VERSION ""

NS_ :

BS_:

BU_: TIMServer TIMClient3 TIMClient2 TIMClient1 DiagnosticNode

BO_ 2498166526 VT12: 34 Vector__XXX
 SG_ AffectedMaskObjectID m189 : 24|16@1+ (1,0) [0|65535] "" Vector__XXX
 SG_ AuxiliaryFunctionID m32 : 24|16@1+ (1,0) [0|65535] "" Vector__XXX
 SG_ AuxiliaryInputNumber m32 : 16|8@1+ (1,0) [0|255] "" Vector__XXX
 SG_ SourceAddressOfAuxiliaryInputDev m32 : 8|8@1+ (1,0) [0|255] "" Vector__XXX
 SG_ ErrorCodeSelectColourMap3 m186 : 26|1@1+ (1,0) [0|1] "" Vector__XXX
 SG_ ErrorCodeGetAttributeValue3 m65535 : 52|1@1+ (1,0) [0|1] "" Vector__XXX
 SG_ ErrorCodeGetAttributeValue2 m65535 : 49|1@1+ (1,0) [0|1] "" Vector__XXX
 SG_ ErrorCodeGetAttributeValue1 m65535 : 48|1@1+ (1,0) [0|1] "" Vector__XXX
 SG_ GetAttributeValueObjectID m65535 : 32|16@1+ (1,0) [0|65535] "" Vector__XXX
 SG_ AttributeValue m0 : 32|64@1+ (1,0) [0|4294967295] "" Vector__XXX
 SG_ ErrorCodeChangeSoftKeyMask3 m174 : 42|1@1+ (1,0) [0|1] "" Vector__XXX
 SG_ ErrorCodeChangeSoftKeyMask4 m174 : 43|1@1+ (1,0) [0|1] "" Vector__XXX
 SG_ ErrorCodeAudioVolume3 m164 : 12|1@1+ (1,0) [0|1] "" Vector__XXX
 SG_ ErrorCodeHideShowObj4 m160 : 36|1@1+ (1,0) [0|1] "" Vector__XXX
 SG_ ErrorCodeGetSupportedWideChars3 m193 : 52|1@1+ (1,0) [0|1] "" Vector__XXX
 SG_ Hardware8 m199 : 31|1@1+ (1,0) [0|1] "" Vector__XXX
 SG_ Hardware7 m199 : 30|1@1+ (1,0) [0|1] "" Vector__XXX
 SG_ ImageIdentificationNumber m198 : 32|16@1+ (1,0) [0|65535] "" Vector__XXX
 SG_ VTControlAudioSigTerminationTAN m10 : 20|4@1+ (1,0) [0|0] "" Vector__XXX
 SG_ ParentMaskObjectID m2 : 48|16@1+ (1,0) [0|0] "" Vector__XXX
 SG_ OperatingState4 m38 : 59|1@1+ (1,0) [0|1] "" Vector__XXX
 SG_ OperatingState3 m38 : 58|1@1+ (1,0) [0|1] "" Vector__XXX
 SG_ VTSelectInputObjectMessageTAN m3 : 60|4@1+ (1,0) [0|15] "" Vector__XXX
 SG_ VTOnUserLayoutHideShowMessageTAN m9 : 60|4@1+ (1,0) [0|15] "" Vector__XXX
 SG_ VTESCMessageTAN m4 : 60|4@1+ (1,0) [0|15] "" Vector__XXX
 SG_ VTChangeNumericValueMessageTAN m5 : 28|4@1+ (1,0) [0|15] "" Vector__XXX
 SG_ SoftKeyActivationMessageTAN m0 : 60|4@1+ (1,0) [0|15] "" Vector__XXX
 SG_ PointingEventMessageTAN m2 : 44|4@1+ (1,0) [0|15] "" Vector__XXX
 SG_ ButtonActivationMessageTAN m1 : 60|4@1+ (1,0) [0|15] "" Vector__XXX
 SG_ PathRequested m198 : 16|8@1+ (1,0) [0|255] "" Vector__XXX
 SG_ ItemRequested m198 : 8|8@1+ (1,0) [0|255] "" Vector__XXX
 SG_ ErrorCodeShowWorkingSet8 m144 : 15|1@1+ (1,0) [0|1] "" Vector__XXX
 SG_ ErrorCodeShowWorkingSet5 m144 : 12|1@1+ (1,0) [0|1] "" Vector__XXX
 SG_ ErrorCodeShowWorkingSet4 m144 : 11|1@1+ (1,0) [0|1] "" Vector__XXX
 SG_ ErrorCodeShowWorkingSet3 m144 : 10|1@1+ (1,0) [0|1] "" Vector__XXX
 SG_ ErrorCodeShowWorkingSet2 m144 : 9|1@1+ (1,0) [0|1] "" Vector__XXX
 SG_ ErrorCodeShowWorkingSet1 m144 : 8|1@1+ (1,0) [0|1] "" Vector__XXX
 SG_ ErrorCodeScreenCapture6 m198 : 29|1@1+ (1,0) [0|1] "" Vector__XXX
 SG_ ErrorCodeScreenCapture5 m198 : 28|1@1+ (1,0) [0|1] "" Vector__XXX
 SG_ ErrorCodeScreenCapture4 m198 : 27|1@1+ (1,0) [0|1] "" Vector__XXX
 SG_ ErrorCodeScreenCapture3 m198 : 26|1@1+ (1,0) [0|1] "" Vector__XXX
 SG_ ErrorCodeScreenCapture2 m198 : 25|1@1+ (1,0) [0|1] "" Vector__XXX
 SG_ ErrorCodeScreenCapture1 m198 : 24|1@1+ (1,0) [0|1] "" Vector__XXX
 SG_ UnsupportedVtFunction m253 : 8|8@1+ (1,0) [0|255] "" Vector__XXX
 SG_ AssignedAttribute2OfSet1 m39 : 105|1@1+ (1,0) [0|1] "" Vector__XXX
 SG_ AssignedAttribute1OfSet1 m39 : 104|1@1+ (1,0) [0|1] "" Vector__XXX
 SG_ FunctionAttributeOfSet1 m39 : 96|8@1+ (1,0) [0|255] "" Vector__XXX
 SG_ AuxiliaryFunctionObjectID m36 : 96|16@1+ (1,0) [0|65535] "" Vector__XXX
 SG_ NumberOfInstancesOfSet1 m39 : 88|8@1+ (1,0) [0|255] "" Vector__XXX
 SG_ NumberOfDifferentSetsOfUnit1 m39 : 80|8@1+ (1,0) [0|255] "" Vector__XXX
 SG_ AuxiliaryInputObjectID m36 : 80|16@1+ (1,0) [0|65535] "" Vector__XXX
 SG_ StoreAsPreferredAssignment m36 : 79|1@1+ (1,0) [0|1] "" Vector__XXX
 SG_ ErrorCodeChangeAttribute5 m175 : 36|1@1+ (1,0) [0|1] "" Vector__XXX
 SG_ AuxiliaryFunctionType m36 : 72|4@1+ (1,0) [0|15] "" Vector__XXX
 SG_ SelfConfigurableAddress m36 : 71|1@1+ (1,0) [0|1] "" Vector__XXX
 SG_ DeviceClassInstance m36 : 64|4@1+ (1,0) [0|15] "" Vector__XXX
 SG_ IndustryGroup m36 : 68|3@1+ (1,0) [0|7] "" Vector__XXX
 SG_ FontType_ProportionalFont m195 : 63|1@1+ (1,0) [0|1] "" Vector__XXX
 SG_ FontType_FlashHidden m195 : 62|1@1+ (1,0) [0|1] "" Vector__XXX
 SG_ FontType_FlashInverted m195 : 61|1@1+ (1,0) [0|1] "" Vector__XXX
 SG_ FontType_InvertedText m195 : 60|1@1+ (1,0) [0|1] "" Vector__XXX
 SG_ ErrorCodeChangePolygonScale5 m183 : 60|1@1+ (1,0) [0|1] "" Vector__XXX
 SG_ FontType_ItalicsText m195 : 59|1@1+ (1,0) [0|1] "" Vector__XXX
 SG_ FontType_UnderlinedText m195 : 58|1@1+ (1,0) [0|1] "" Vector__XXX
 SG_ FontType_CrossedOutText m195 : 57|1@1+ (1,0) [0|1] "" Vector__XXX
 SG_ DeviceClass m36 : 57|7@1+ (1,0) [0|127] "" Vector__XXX
 SG_ OperatingState2 m38 : 57|1@1+ (1,0) [0|1] "" Vector__XXX
 SG_ VTFunctionCode m254 : 56|8@1+ (1,0) [0|255] "" Vector__XXX
 SG_ FontType_BoldText m195 : 56|1@1+ (1,0) [0|1] "" Vector__XXX
 SG_ NumberOfPhysicalSoftKeys m194 : 56|8@1+ (1,0) [0|255] "" Vector__XXX
 SG_ NumberOfRanges m193 : 56|8@1+ (1,0) [0|255] "" Vector__XXX
 SG_ ErrorCodeChangePolygonScale1 m183 : 56|1@1+ (1,0) [0|1] "" Vector__XXX
 SG_ OperatingState1 m38 : 56|1@1+ (1,0) [0|1] "" Vector__XXX
 SG_ VTBusyCode8 m254 : 55|1@1+ (1,0) [0|1] "" Vector__XXX
 SG_ FontSize_128x192 m195 : 54|1@1+ (1,0) [0|1] "" Vector__XXX
 SG_ VTBusyCode7 m254 : 54|1@1+ (1,0) [0|1] "" Vector__XXX
 SG_ FontSize_128x128 m195 : 53|1@1+ (1,0) [0|1] "" Vector__XXX
 SG_ VTBusyCode5 m254 : 52|1@1+ (1,0) [0|1] "" Vector__XXX
 SG_ FontSize_96x128 m195 : 52|1@1+ (1,0) [0|1] "" Vector__XXX
 SG_ ErrorCodeGetSupportedWideChars2 m193 : 49|1@1+ (1,0) [0|1] "" Vector__XXX
 SG_ ErrorCodeChangeListItem5 m177 : 52|1@1+ (1,0) [0|1] "" Vector__XXX
 SG_ ErrorCodeChangeListItem4 m177 : 51|1@1+ (1,0) [0|1] "" Vector__XXX
 SG_ VTBusyCode4 m254 : 51|1@1+ (1,0) [0|1] "" Vector__XXX
 SG_ FontSize_64x96 m195 : 51|1@1+ (1,0) [0|1] "" Vector__XXX
 SG_ ErrorCodeObjectPool4 m18 : 51|1@1+ (1,0) [0|1] "" Vector__XXX
 SG_ VTBusyCode3 m254 : 50|1@1+ (1,0) [0|1] "" Vector__XXX
 SG_ FontSize_64x64 m195 : 50|1@1+ (1,0) [0|1] "" Vector__XXX
 SG_ ErrorCodeChangeListItem3 m177 : 50|1@1+ (1,0) [0|1] "" Vector__XXX
 SG_ ErrorCodeObjectPool3 m18 : 50|1@1+ (1,0) [0|1] "" Vector__XXX
 SG_ VTBusyCode2 m254 : 49|1@1+ (1,0) [0|1] "" Vector__XXX
 SG_ FontSize_48x64 m195 : 49|1@1+ (1,0) [0|1] "" Vector__XXX
 SG_ ErrorCodeChangeListItem2 m177 : 49|1@1+ (1,0) [0|1] "" Vector__XXX
 SG_ ErrorCodeObjectPool2 m18 : 49|1@1+ (1,0) [0|1] "" Vector__XXX
 SG_ VTBusyCode1 m254 : 48|1@1+ (1,0) [0|1] "" Vector__XXX
 SG_ NrOfYPixelsInDataAreaMask m199 : 48|16@1+ (1,0) [0|65535] "" Vector__XXX
 SG_ FontSize_32x48 m195 : 48|1@1+ (1,0) [0|1] "" Vector__XXX
 SG_ NumberOfPossibleVirtualSoftKeys m194 : 48|8@1+ (1,0) [0|255] "" Vector__XXX
 SG_ ErrorCodeGetSupportedWideChars1 m193 : 48|1@1+ (1,0) [0|1] "" Vector__XXX
 SG_ ErrorCodeChangeListItem1 m177 : 48|1@1+ (1,0) [0|1] "" Vector__XXX
 SG_ Function m36 : 48|8@1+ (1,0) [0|255] "" Vector__XXX
 SG_ ErrorCodeObjectPool1 m18 : 48|1@1+ (1,0) [0|1] "" Vector__XXX
 SG_ VTChangeActiveMaskParentID m6 : 48|16@1+ (1,0) [0|65535] "" Vector__XXX
 SG_ ButtonKeyCode m1 : 48|8@1+ (1,0) [0|255] "" Vector__XXX
 SG_ SoftKeyCode m0 : 48|8@1+ (1,0) [0|255] "" Vector__XXX
 SG_ BooleanValue m33 : 48|8@1+ (1,0) [0|2] "" Vector__XXX
 SG_ Status_2 m9 : 48|8@1+ (1,0) [0|1] "" Vector__XXX
 SG_ ErrorCodeVTChangeSoftKeyMask4 m7 : 45|1@1+ (1,0) [0|1] "" Vector__XXX
 SG_ FontSize_32x32 m195 : 46|1@1+ (1,0) [0|1] "" Vector__XXX
 SG_ FontSize_24x32 m195 : 45|1@1+ (1,0) [0|1] "" Vector__XXX
 SG_ FontSize_16x24 m195 : 44|1@1+ (1,0) [0|1] "" Vector__XXX
 SG_ ErrorCodeChangePosInvalidError m180 : 44|1@1+ (1,0) [0|1] "" Vector__XXX
 SG_ ErrorCodeChangeSoftKeyMask5 m174 : 44|1@1+ (1,0) [0|1] "" Vector__XXX
 SG_ ErrorCodeChangeChildLocation5 m165 : 44|1@1+ (1,0) [0|1] "" Vector__XXX
 SG_ ErrorCodeVTChangeSoftKeyMask3 m7 : 44|1@1+ (1,0) [0|1] "" Vector__XXX
 SG_ ErrorCodeChangeStrValueInUse m179 : 44|1@1+ (1,0) [0|1] "" Vector__XXX
 SG_ ErrorCodeVtObjPoolError4 m240 : 43|1@1+ (1,0) [0|1] "" Vector__XXX
 SG_ FontSize_16x16 m195 : 43|1@1+ (1,0) [0|1] "" Vector__XXX
 SG_ ErrorCodeChangeStrError m179 : 43|1@1+ (1,0) [0|1] "" Vector__XXX
 SG_ FunctionInstance m36 : 43|5@1+ (1,0) [0|31] "" Vector__XXX
 SG_ ErrorCodeVTChangeSoftKeyMask2 m7 : 43|1@1+ (1,0) [0|1] "" Vector__XXX
 SG_ ErrorCodeVtObjPoolError3 m240 : 42|1@1+ (1,0) [0|1] "" Vector__XXX
 SG_ FontSize_12x16 m195 : 42|1@1+ (1,0) [0|1] "" Vector__XXX
 SG_ ErrorCodeChangeStrTooLong m179 : 42|1@1+ (1,0) [0|1] "" Vector__XXX
 SG_ ErrorCodeVTChangeSoftKeyMask1 m7 : 42|1@1+ (1,0) [0|1] "" Vector__XXX
 SG_ ErrorCodeVtObjPoolError2 m240 : 41|1@1+ (1,0) [0|1] "" Vector__XXX
 SG_ FontSize_8x12 m195 : 41|1@1+ (1,0) [0|1] "" Vector__XXX
 SG_ ErrorCodeChangePosInvalidObject m180 : 41|1@1+ (1,0) [0|1] "" Vector__XXX
 SG_ ErrorCodeChangeStrObjectID m179 : 41|1@1+ (1,0) [0|1] "" Vector__XXX
 SG_ ErrorCodeChangeSoftKeyMask2 m174 : 41|1@1+ (1,0) [0|1] "" Vector__XXX
 SG_ ErrorCodeChangeChildLocation2 m165 : 41|1@1+ (1,0) [0|1] "" Vector__XXX
 SG_ ErrorCodeVtObjPoolError1 m240 : 40|1@1+ (1,0) [0|1] "" Vector__XXX
 SG_ AcknowledgmentDeleteVersion m210 : 40|4@1+ (1,0) [0|8] "" Vector__XXX
 SG_ AcknowledgmentLoadVersion m209 : 40|4@1+ (1,0) [0|8] "" Vector__XXX
 SG_ AcknowledgmentStoreVersion m208 : 40|4@1+ (1,0) [0|8] "" Vector__XXX
 SG_ FontSize_8x8 m195 : 40|1@1+ (1,0) [0|1] "" Vector__XXX
 SG_ YDotsForSoftKeyDescriptor m194 : 40|8@1+ (1,0) [0|255] "" Vector__XXX
 SG_ NewHeigthAttribute m183 : 40|16@1+ (1,0) [0|0] "" Vector__XXX
 SG_ ErrorCodeChangePosInvalidParent m180 : 40|1@1+ (1,0) [0|1] "" Vector__XXX
 SG_ ErrorCodeChangeSoftKeyMask1 m174 : 40|1@1+ (1,0) [0|1] "" Vector__XXX
 SG_ ErrorCodeChangeChildLocation1 m165 : 40|1@1+ (1,0) [0|1] "" Vector__XXX
 SG_ Value2 m38 : 40|16@1+ (1,0) [0|65535] "" Vector__XXX
 SG_ ECUInstance m36 : 40|3@1+ (1,0) [0|7] "" Vector__XXX
 SG_ TouchState m2 : 40|4@1+ (1,0) [0|255] "" Vector__XXX
 SG_ ErrorCodeSelectObject6 m162 : 37|1@1+ (1,0) [0|1] "" Vector__XXX
 SG_ ErrorCodeGraphicsContextCmd5 m184 : 36|1@1+ (1,0) [0|1] "" Vector__XXX
 SG_ ErrorCodeChangePriority3 m176 : 36|1@1+ (1,0) [0|1] "" Vector__XXX
 SG_ ErrorCodeChangeAttribute4 m175 : 35|1@1+ (1,0) [0|1] "" Vector__XXX
 SG_ ErrorCodeChangeColour3 m167 : 36|1@1+ (1,0) [0|1] "" Vector__XXX
 SG_ ErrorCodeSelectObject5 m162 : 36|1@1+ (1,0) [0|1] "" Vector__XXX
 SG_ ErrorCodeEnableDisableObj4 m161 : 36|1@1+ (1,0) [0|1] "" Vector__XXX
 SG_ ErrorCodeGraphicsContextCmd4 m184 : 35|1@1+ (1,0) [0|1] "" Vector__XXX
 SG_ ErrorCodeSelectObject4 m162 : 35|1@1+ (1,0) [0|1] "" Vector__XXX
 SG_ ErrorCodeEnableDisableObj3 m161 : 35|1@1+ (1,0) [0|1] "" Vector__XXX
 SG_ ErrorCodeHideShowObj3 m160 : 34|1@1+ (1,0) [0|1] "" Vector__XXX
 SG_ ErrorCodeGraphicsContextCmd3 m184 : 34|1@1+ (1,0) [0|1] "" Vector__XXX
 SG_ ErrorCodeChangeAttribute3 m175 : 34|1@1+ (1,0) [0|1] "" Vector__XXX
 SG_ ErrorCodeSelectObject3 m162 : 34|1@1+ (1,0) [0|1] "" Vector__XXX
 SG_ ErrorCodeEnableDisableObj2 m161 : 34|1@1+ (1,0) [0|1] "" Vector__XXX
 SG_ ErrorCodeGraphicsContextCmd2 m184 : 33|1@1+ (1,0) [0|1] "" Vector__XXX
 SG_ ErrorCodeChangePriority2 m176 : 33|1@1+ (1,0) [0|1] "" Vector__XXX
 SG_ ErrorCodeChangeAttribute2 m175 : 33|1@1+ (1,0) [0|1] "" Vector__XXX
 SG_ ErrorCodeChangeColour2 m167 : 33|1@1+ (1,0) [0|1] "" Vector__XXX
 SG_ ErrorCodeSelectObject2 m162 : 33|1@1+ (1,0) [0|1] "" Vector__XXX
 SG_ ErrorCodeEnableDisableObj1 m161 : 33|1@1+ (1,0) [0|1] "" Vector__XXX
 SG_ ErrorCodeHideShowObj2 m160 : 33|1@1+ (1,0) [0|1] "" Vector__XXX
 SG_ VisibleSoftKeyMaskObjectID m254 : 32|16@1+ (1,0) [0|65535] "" Vector__XXX
 SG_ NrOfXPixelsInDataAreaMask m199 : 32|16@1+ (1,0) [0|65535] "" Vector__XXX
 SG_ XDotsForSoftKeyDescriptor m194 : 32|8@1+ (1,0) [0|255] "" Vector__XXX
 SG_ LastWideChar m193 : 32|16@1+ (1,0) [0|65535] "" Vector__XXX
 SG_ ErrorCodeGraphicsContextCmd1 m184 : 32|1@1+ (1,0) [0|1] "" Vector__XXX
 SG_ NewObjectID m177 : 32|16@1+ (1,0) [0|65535] "" Vector__XXX
 SG_ ErrorCodeChangePriority1 m176 : 32|1@1+ (1,0) [0|1] "" Vector__XXX
 SG_ ErrorCodeChangeAttribute1 m175 : 32|1@1+ (1,0) [0|1] "" Vector__XXX
 SG_ ValueOfTheObject m168 : 32|32@1+ (1,0) [0|2704] "" Vector__XXX
 SG_ ErrorCodeChangeColour1 m167 : 32|1@1+ (1,0) [0|1] "" Vector__XXX
 SG_ ErrorCodeSelectObject1 m162 : 32|1@1+ (1,0) [0|1] "" Vector__XXX
 SG_ ErrorCodeHideShowObj1 m160 : 32|1@1+ (1,0) [0|1] "" Vector__XXX
 SG_ ObjectIdOfFaultyObject m18 : 32|16@1+ (1,0) [0|65535] "" Vector__XXX
 SG_ VTChangeActiveMaskErrorID m6 : 32|16@1+ (1,0) [0|65535] "" Vector__XXX
 SG_ VTChangeNumericValueValue m5 : 32|32@1+ (1,0) [0|4294967295] "" Vector__XXX
 SG_ VTSelectInputObjectIsEdited m3 : 32|1@1+ (1,0) [0|1] "" Vector__XXX
 SG_ ButtonObjectParentID m1 : 32|16@1+ (1,0) [0|65535] "" Vector__XXX
 SG_ KeyObjectParentID m0 : 32|16@1+ (1,0) [0|65535] "" Vector__XXX
 SG_ NumTransitionsDisabledToEnabled m33 : 32|16@1+ (1,0) [0|65535] "" Vector__XXX
 SG_ ObjectID_2 m9 : 32|16@1+ (1,0) [0|65535] "" Vector__XXX
 SG_ Hardware6 m199 : 29|1@1+ (1,0) [0|1] "" Vector__XXX
 SG_ ErrorCodeChangeFont6 m170 : 29|1@1+ (1,0) [0|1] "" Vector__XXX
 SG_ ManufacturerCode m36 : 29|11@1+ (1,0) [0|2047] "" Vector__XXX
 SG_ ErrorCodePoolDeleted m6 : 29|1@1+ (1,0) [0|1] "" Vector__XXX
 SG_ Hardware5 m199 : 28|1@1+ (1,0) [0|1] "" Vector__XXX
 SG_ ErrorCodeChangeActiveMask3 m173 : 28|1@1+ (1,0) [0|1] "" Vector__XXX
 SG_ ErrorCodeChangeFillAttributes5 m172 : 28|1@1+ (1,0) [0|1] "" Vector__XXX
 SG_ ErrorCodeChangeLineAttribute4 m171 : 28|1@1+ (1,0) [0|1] "" Vector__XXX
 SG_ ErrorCodeChangeFont5 m170 : 28|1@1+ (1,0) [0|1] "" Vector__XXX
 SG_ ErrorCodeChangeEditPoint3 m169 : 28|1@1+ (1,0) [0|1] "" Vector__XXX
 SG_ ErrorCodeObjToSize2 m166 : 28|1@1+ (1,0) [0|1] "" Vector__XXX
 SG_ ErrorCodeEscapeObj2 m146 : 28|1@1+ (1,0) [0|1] "" Vector__XXX
 SG_ ErrorCodeAnyOtherError m6 : 28|1@1+ (1,0) [0|1] "" Vector__XXX
 SG_ ErrorCodeVTEsc5 m4 : 28|1@1+ (1,0) [0|1] "" Vector__XXX
 SG_ ErrorCodeChangeNumValue4 m168 : 28|1@1+ (1,0) [0|1] "" Vector__XXX
 SG_ Hardware4 m199 : 27|1@1+ (1,0) [0|1] "" Vector__XXX
 SG_ ErrorCodeChangeFillAttributes4 m172 : 27|1@1+ (1,0) [0|1] "" Vector__XXX
 SG_ ErrorCodeChangeFont4 m170 : 27|1@1+ (1,0) [0|1] "" Vector__XXX
 SG_ ErrorCodeMaskOrChildObjectError m6 : 27|1@1+ (1,0) [0|1] "" Vector__XXX
 SG_ ErrorCodeChangeNumValue3 m168 : 26|1@1+ (1,0) [0|1] "" Vector__XXX
 SG_ Hardware3 m199 : 26|1@1+ (1,0) [0|1] "" Vector__XXX
 SG_ ErrorCodeChangePoygonPoint3 m182 : 26|1@1+ (1,0) [0|1] "" Vector__XXX
 SG_ ErrorCodeChangeFillAttributes3 m172 : 26|1@1+ (1,0) [0|1] "" Vector__XXX
 SG_ ErrorCodeChangeLineAttribute3 m171 : 26|1@1+ (1,0) [0|1] "" Vector__XXX
 SG_ ErrorCodeChangeFont3 m170 : 26|1@1+ (1,0) [0|1] "" Vector__XXX
 SG_ ErrorCodeMissingObjects m6 : 26|1@1+ (1,0) [0|1] "" Vector__XXX
 SG_ ErrorCodeExecuteExtendedMacro3 m188 : 26|1@1+ (1,0) [0|1] "" Vector__XXX
 SG_ Hardware2 m199 : 25|1@1+ (1,0) [0|1] "" Vector__XXX
 SG_ ErrorCodeSelectColourMap2 m186 : 25|1@1+ (1,0) [0|1] "" Vector__XXX
 SG_ ErrorCodeChangePoygonPoint2 m182 : 25|1@1+ (1,0) [0|1] "" Vector__XXX
 SG_ ErrorCodeChangeActiveMask2 m173 : 25|1@1+ (1,0) [0|1] "" Vector__XXX
 SG_ ErrorCodeChangeFillAttributes2 m172 : 25|1@1+ (1,0) [0|1] "" Vector__XXX
 SG_ ErrorCodeChangeLineAttribute2 m171 : 25|1@1+ (1,0) [0|1] "" Vector__XXX
 SG_ ErrorCodeChangeFont2 m170 : 25|1@1+ (1,0) [0|1] "" Vector__XXX
 SG_ ErrorCodeChangeEditPoint2 m169 : 25|1@1+ (1,0) [0|1] "" Vector__XXX
 SG_ ErrorCodeChangeNumValue2 m168 : 25|1@1+ (1,0) [0|1] "" Vector__XXX
 SG_ ErrorCodeExecuteExtendedMacro2 m188 : 25|1@1+ (1,0) [0|1] "" Vector__XXX
 SG_ ObjectIDOfFaultyObject m240 : 24|16@1+ (1,0) [0|65535] "" Vector__XXX
 SG_ Hardware1 m199 : 24|1@1+ (1,0) [0|1] "" Vector__XXX
 SG_ ErrorCodeSelectColourMap1 m186 : 24|1@1+ (1,0) [0|1] "" Vector__XXX
 SG_ AttributeID m185M : 24|8@1+ (1,0) [0|0] "" Vector__XXX
 SG_ SubCommandID m184 : 24|8@1+ (1,0) [0|0] "" Vector__XXX
 SG_ NewWidthAttribute m183 : 24|16@1+ (1,0) [0|65535] "" Vector__XXX
 SG_ ErrorCodeChangePoygonPoint1 m182 : 24|1@1+ (1,0) [0|1] "" Vector__XXX
 SG_ ChangeChildPosObjID m180 : 24|16@1+ (1,0) [0|65535] "" Vector__XXX
 SG_ ChangeStringValueObjID m179 : 24|16@1+ (1,0) [0|65535] "" Vector__XXX
 SG_ ListIndex m177 : 24|8@1+ (1,0) [0|255] "" Vector__XXX
 SG_ NewPriority m176 : 24|8@1+ (1,0) [0|255] "" Vector__XXX
 SG_ AttributeToChangeID m175 : 24|8@1+ (1,0) [0|65535] "" Vector__XXX
 SG_ SoftKeyMaskObjectID m174 : 24|16@1+ (1,0) [0|65535] "" Vector__XXX
 SG_ ErrorCodeChangeActiveMask1 m173 : 24|1@1+ (1,0) [0|1] "" Vector__XXX
 SG_ ErrorCodeChangeFillAttributes1 m172 : 24|1@1+ (1,0) [0|1] "" Vector__XXX
 SG_ ErrorCodeChangeLineAttribute1 m171 : 24|1@1+ (1,0) [0|1] "" Vector__XXX
 SG_ ErrorCodeChangeFont1 m170 : 24|1@1+ (1,0) [0|1] "" Vector__XXX
 SG_ ErrorCodeChangeEditPoint1 m169 : 24|1@1+ (1,0) [0|1] "" Vector__XXX
 SG_ ErrorCodeChangeNumValue1 m168 : 24|1@1+ (1,0) [0|1] "" Vector__XXX
 SG_ NewBackgroundColour m167 : 24|8@1+ (1,0) [0|255] "" Vector__XXX
 SG_ ErrorCodeObjToSize1 m166 : 24|1@1+ (1,0) [0|1] "" Vector__XXX
 SG_ ChangeChildLocObjID m165 : 24|16@1+ (1,0) [0|65535] "" Vector__XXX
 SG_ ObjectSelectStatus m162 : 24|8@1+ (1,0) [0|2] "" Vector__XXX
 SG_ ObjectEnableStatus m161 : 24|8@1+ (1,0) [0|1] "" Vector__XXX
 SG_ ObjectShowStatus m160 : 24|8@1+ (1,0) [0|1] "" Vector__XXX
 SG_ ErrorCodeEscapeObj1 m146 : 24|1@1+ (1,0) [0|1] "" Vector__XXX
 SG_ AuxInputEnable m37 : 24|8@1+ (1,0) [0|1] "" Vector__XXX
 SG_ Value1 m38 : 24|16@1+ (1,0) [0|65535] "" Vector__XXX
 SG_ EnteredStringValue m8 : 24|8@1+ (1,0) [0|255] "" Vector__XXX
 SG_ VTChangeSoftKeyMaskObjectID m7 : 24|16@1+ (1,0) [0|65535] "" Vector__XXX
 SG_ ErrorCodeVTEsc1 m4 : 24|1@1+ (1,0) [0|1] "" Vector__XXX
 SG_ VTSelectInputObjectStatus m3 : 24|8@1+ (1,0) [0|1] "" Vector__XXX
 SG_ YPosition m2 : 24|16@1+ (1,0) [0|65535] "" Vector__XXX
 SG_ Status_1 m9 : 24|8@1+ (1,0) [0|1] "" Vector__XXX
 SG_ ErrorCodeExecuteExtendedMacro1 m188 : 24|1@1+ (1,0) [0|1] "" Vector__XXX
 SG_ ErrorCodeLockUnlockMask8 m189 : 23|1@1+ (1,0) [0|1] "" Vector__XXX
 SG_ ErrorCodeLockUnlockMask7 m189 : 22|1@1+ (1,0) [0|1] "" Vector__XXX
 SG_ ErrorCodeLockUnlockMask6 m189 : 21|1@1+ (1,0) [0|1] "" Vector__XXX
 SG_ ErrorCodeLockUnlockMask5 m189 : 20|1@1+ (1,0) [0|1] "" Vector__XXX
 SG_ ErrorCodeLockUnlockMask4 m189 : 19|1@1+ (1,0) [0|1] "" Vector__XXX
 SG_ ErrorCodeExecuteMacro3 m190 : 18|1@1+ (1,0) [0|1] "" Vector__XXX
 SG_ ErrorCodeLockUnlockMask3 m189 : 18|1@1+ (1,0) [0|1] "" Vector__XXX
 SG_ ErrorCodeExecuteMacro2 m190 : 17|1@1+ (1,0) [0|1] "" Vector__XXX
 SG_ ErrorCodeLockUnlockMask2 m189 : 17|1@1+ (1,0) [0|1] "" Vector__XXX
 SG_ NameOfAuxiliaryUnit1 m39 : 16|64@1+ (1,0) [0|0] "" Vector__XXX
 SG_ ExtendedVersionLables m211 : 16|256@1+ (1,0) [0|16777215] "" Vector__XXX
 SG_ VisibleDataOrAlarmMaskObjectID m254 : 16|16@1+ (1,0) [0|65535] "" Vector__XXX
 SG_ VersionLables m224 : 16|56@1+ (1,0) [0|0] "" Vector__XXX
 SG_ SupportedGraphicMode m199 : 16|8@1+ (1,0) [0|2] "" Vector__XXX
 SG_ FirstWideChar m193 : 16|16@1+ (1,0) [0|65535] "" Vector__XXX
 SG_ MemoryStatus m192 : 16|8@1+ (1,0) [0|1] "" Vector__XXX
 SG_ ErrorCodeExecuteMacro1 m190 : 16|1@1+ (1,0) [0|1] "" Vector__XXX
 SG_ ErrorCodeLockUnlockMask1 m189 : 16|1@1+ (1,0) [0|1] "" Vector__XXX
 SG_ ParentObjectIDOfFaultyObject m18 : 16|16@1+ (1,0) [0|65535] "" Vector__XXX
 SG_ ButtonObjectID m1 : 16|16@1+ (1,0) [0|65535] "" Vector__XXX
 SG_ KeyObjectID m0 : 16|16@1+ (1,0) [0|65535] "" Vector__XXX
 SG_ AuxFunctObjOfFaultyAssignment m34 : 16|16@1- (1,0) [0|65535] "" Vector__XXX
 SG_ AnalogValue m33 : 16|16@1+ (1,0) [0|65535] "" Vector__XXX
 SG_ BgrColourUserLayoutSoftkeyMask m196 : 16|8@1+ (1,0) [0|255] "" Vector__XXX
 SG_ ErrorCodeSetObjectLabel6 m181 : 13|1@1+ (1,0) [0|1] "" Vector__XXX
 SG_ ErrorCodeSetObjectLabel5 m181 : 12|1@1+ (1,0) [0|1] "" Vector__XXX
 SG_ ErrorCodeDeleteObjectPool2 m178 : 12|1@1+ (1,0) [0|1] "" Vector__XXX
 SG_ ErrorCodeAudioVolume2 m164 : 9|1@1+ (1,0) [0|1] "" Vector__XXX
 SG_ ErrorCodeControlAudioDevice2 m163 : 12|1@1+ (1,0) [0|1] "" Vector__XXX
 SG_ ErrorCodeEndOfObjectPool3 m18 : 12|1@1+ (1,0) [0|1] "" Vector__XXX
 SG_ AuxPreferredAssignmentRespError5 m34 : 12|1@1+ (1,0) [0|1] "" Vector__XXX
 SG_ ErrorCodeSetObjectLabel4 m181 : 11|1@1+ (1,0) [0|1] "" Vector__XXX
 SG_ AuxPreferredAssignmentRespError4 m34 : 11|1@1+ (1,0) [0|1] "" Vector__XXX
 SG_ ErrorCodeSetObjectLabel3 m181 : 10|1@1+ (1,0) [0|1] "" Vector__XXX
 SG_ AuxPreferredAssignmentRespError3 m34 : 10|1@1+ (1,0) [0|1] "" Vector__XXX
 SG_ ErrorCodeSetObjectLabel2 m181 : 9|1@1+ (1,0) [0|1] "" Vector__XXX
 SG_ AuxPreferredAssignmentRespError2 m34 : 9|1@1+ (1,0) [0|1] "" Vector__XXX
 SG_ ErrorCodeEndOfObjectPool2 m18 : 9|1@1+ (1,0) [0|1] "" Vector__XXX
 SG_ SourceAdressOfActiveWSM m254 : 8|8@1+ (1,0) [0|255] "" Vector__XXX
 SG_ ParentIDOfFaultyObject m240 : 8|16@1+ (1,0) [0|65535] "" Vector__XXX
 SG_ NrOfVersionStrings m224 : 8|8@1+ (1,0) [0|255] "" Vector__XXX
 SG_ NavigationSoftKeys m194 : 8|8@1+ (1,0) [0|254] "" Vector__XXX
 SG_ CodePlane m193 : 8|8@1+ (1,0) [0|16] "" Vector__XXX
 SG_ VersionNumberISO11783Part6 m192 : 8|8@1+ (1,0) [0|255] "" Vector__XXX
 SG_ MacroObjectID m190 : 8|8@1+ (1,0) [0|255] "" Vector__XXX
 SG_ LockUnlockCommand m189 : 8|8@1+ (1,0) [0|1] "" Vector__XXX
 SG_ ColourMapObjectID m186 : 8|16@1+ (1,0) [0|65535] "" Vector__XXX
 SG_ ObjectToGetAttributeID m185 : 8|16@1+ (1,0) [0|65535] "" Vector__XXX
 SG_ GraphicsContextObjectID m184 : 8|16@1+ (1,0) [0|65535] "" Vector__XXX
 SG_ PolygonObjectToScaleID m183 : 8|16@1+ (1,0) [0|65535] "" Vector__XXX
 SG_ PolygonObjectToChangeID m182 : 8|16@1+ (1,0) [0|65535] "" Vector__XXX
 SG_ ErrorCodeSetObjectLabel1 m181 : 8|1@1+ (1,0) [0|1] "" Vector__XXX
 SG_ ChangeChildPosParObjID m180 : 8|16@1+ (1,0) [0|65535] "" Vector__XXX
 SG_ ErrorCodeDeleteObjectPool1 m178 : 8|1@1+ (1,0) [0|1] "" Vector__XXX
 SG_ ListInputObjectID m177 : 8|16@1+ (1,0) [0|65535] "" Vector__XXX
 SG_ AlarmMaskObjectID m176 : 8|16@1+ (1,0) [0|65535] "" Vector__XXX
 SG_ ObjectToChangeAttributeID m175 : 8|16@1+ (1,0) [0|65535] "" Vector__XXX
 SG_ DataOrAlarmMaskObjectID m174 : 8|16@1+ (1,0) [0|65535] "" Vector__XXX
 SG_ ActiveMaskObjectID m173 : 8|16@1+ (1,0) [0|0] "" Vector__XXX
 SG_ ObjectToChangeFillAttributesID m172 : 8|16@1+ (1,0) [0|65535] "" Vector__XXX
 SG_ ObjectToChangeLineAttributeID m171 : 8|16@1+ (1,0) [0|65535] "" Vector__XXX
 SG_ ObjectToChangeFontID m170 : 8|16@1+ (1,0) [0|65535] "" Vector__XXX
 SG_ ObjectToChangeEndPointID m169 : 8|16@1+ (1,0) [0|65535] "" Vector__XXX
 SG_ ObjectToChangeNumValueID m168 : 8|16@1+ (1,0) [0|65535] "" Vector__XXX
 SG_ ObjectToChangeColourID m167 : 8|16@1+ (1,0) [0|65535] "" Vector__XXX
 SG_ ObjectToSizeID m166 : 8|16@1+ (1,0) [0|65535] "" Vector__XXX
 SG_ ChangeChildLocParObjID m165 : 8|16@1+ (1,0) [0|65535] "" Vector__XXX
 SG_ ErrorCodeAudioVolume1 m164 : 8|1@1+ (1,0) [0|1] "" Vector__XXX
 SG_ ErrorCodeControlAudioDevice1 m163 : 8|1@1+ (1,0) [0|1] "" Vector__XXX
 SG_ SelectInputObjectID m162 : 8|16@1+ (1,0) [0|65535] "" Vector__XXX
 SG_ ObjectToEnableDisableID m161 : 8|16@1+ (1,0) [0|65535] "" Vector__XXX
 SG_ ObjectToHideShowID m160 : 8|16@1+ (1,0) [0|65535] "" Vector__XXX
 SG_ ObjectEscapeID m146 : 8|16@1+ (1,0) [0|65535] "" Vector__XXX
 SG_ InputStatusObjectId m37 : 8|16@1+ (1,0) [0|255] "" Vector__XXX
 SG_ AuxPreferredAssignmentRespError1 m34 : 8|1@1+ (1,0) [0|1] "" Vector__XXX
 SG_ InputObjectId m38 : 8|16@1+ (1,0) [0|255] "" Vector__XXX
 SG_ IdentityNumber m36 : 8|21@1+ (1,0) [0|2097150] "" Vector__XXX
 SG_ ErrorCodeEndOfObjectPool1 m18 : 8|1@1+ (1,0) [0|1] "" Vector__XXX
 SG_ ObjectToChangeStringID m8 : 8|16@1+ (1,0) [0|65535] "" Vector__XXX
 SG_ VTChangeSoftKeyMaskParentID m7 : 8|16@1+ (1,0) [0|65535] "" Vector__XXX
 SG_ VTChangeActiveMaskObjectID m6 : 8|16@1+ (1,0) [0|65535] "" Vector__XXX
 SG_ VTChangeNumericValueObjectID m5 : 8|16@1+ (1,0) [0|65535] "" Vector__XXX
 SG_ VTEscObjectID m4 : 8|16@1+ (1,0) [0|65535] "" Vector__XXX
 SG_ VTSelectInputObjectID m3 : 8|16@1+ (1,0) [0|65535] "" Vector__XXX
 SG_ XPosition m2 : 8|16@1+ (1,0) [0|65535] "" Vector__XXX
 SG_ ButtonActivationCode m1 : 8|8@1+ (1,0) [0|2] "" Vector__XXX
 SG_ KeyActivationCode m0 : 8|8@1+ (1,0) [0|2] "" Vector__XXX
 SG_ TerminationCause m10 : 8|8@1+ (1,0) [0|255] "" Vector__XXX
 SG_ InputNumber m33 : 8|8@1+ (1,0) [0|250] "" Vector__XXX
 SG_ ObjectID_1 m9 : 8|16@1+ (1,0) [0|65535] "" Vector__XXX
 SG_ BgrColourUserLayoutDataMask m196 : 8|8@1+ (1,0) [0|255] "" Vector__XXX
 SG_ NumberOfSupportedObjects m197 : 8|8@1+ (1,0) [0|255] "" Vector__XXX
 SG_ BootTime m199 : 8|8@1+ (1,0) [0|255] "s" Vector__XXX
 SG_ NumberOfAuxiliaryUnits m39 : 8|8@1+ (1,0) [0|255] "" Vector__XXX
 SG_ MacroObjectID_2 m188 : 8|16@1+ (1,0) [0|65535] "" Vector__XXX
 SG_ VTFunctionVTtoECU M : 0|8@1+ (1,0) [0|255] "" Vector__XXX

BO_ 2565799678 AC: 8 Vector__XXX
 SG_ ReservedBit : 48|1@1+ (1,0) [0|0] "" Vector__XXX
 SG_ ArbitraryAddressCapable : 63|1@1+ (1,0) [0|1] "" Vector__XXX
 SG_ IndustryGroup M : 60|3@1+ (1,0) [0|7] "" Vector__XXX
 SG_ VehicleSystemInstance : 56|4@1+ (1,0) [0|15] "" Vector__XXX
 SG_ VehicleSystem m0 : 49|7@1+ (1,0) [0|127] "" Vector__XXX
 SG_ VehicleSystem5 m5 : 49|7@1+ (1,0) [0|127] "" Vector__XXX
 SG_ VehicleSystem4 m4 : 49|7@1+ (1,0) [0|127] "" Vector__XXX
 SG_ VehicleSystem3 m3 : 49|7@1+ (1,0) [0|127] "" Vector__XXX
 SG_ VehicleSystem2 m2 : 49|7@1+ (1,0) [0|127] "" Vector__XXX
 SG_ VehicleSystem1 m1 : 49|7@1+ (1,0) [0|127] "" Vector__XXX
 SG_ Function : 40|8@1+ (1,0) [0|255] "" Vector__XXX
 SG_ FunctionInstance : 35|5@1+ (1,0) [0|31] "" Vector__XXX
 SG_ ECUInstance : 32|3@1+ (1,0) [0|7] "" Vector__XXX
 SG_ ManufacturerCode : 21|11@1+ (1,0) [0|2047] "" Vector__XXX
 SG_ IdentityNumber : 0|21@1+ (1,0) [0|2097152] "" Vector__XXX

BO_ 2566838526 CA: 9 Vector__XXX
 SG_ AddressAssignment : 64|8@1+ (1,0) [0|255] "" Vector__XXX
 SG_ ArbitraryAddressCapable : 63|1@1+ (1,0) [0|1] "" Vector__XXX
 SG_ IndustryGroup M : 60|3@1+ (1,0) [0|7] "" Vector__XXX
 SG_ VehicleSystemInstance : 56|4@1+ (1,0) [0|15] "" Vector__XXX
 SG_ VehicleSystem1 m1 : 49|7@1+ (1,0) [0|127] "" Vector__XXX
 SG_ VehicleSystem2 m2 : 49|7@1+ (1,0) [0|127] "" Vector__XXX
 SG_ VehicleSystem3 m3 : 49|7@1+ (1,0) [0|127] "" Vector__XXX
 SG_ VehicleSystem4 m4 : 49|7@1+ (1,0) [0|127] "" Vector__XXX
 SG_ VehicleSystem5 m5 : 49|7@1+ (1,0) [0|127] "" Vector__XXX
 SG_ VehicleSystem m0 : 49|7@1+ (1,0) [0|127] "" Vector__XXX
 SG_ Function : 40|8@1+ (1,0) [0|255] "" Vector__XXX
 SG_ FunctionInstance : 35|5@1+ (1,0) [0|31] "" Vector__XXX
 SG_ ECUInstance : 32|3@1+ (1,0) [0|7] "" Vector__XXX
 SG_ ManufacturerCode : 21|11@1+ (1,0) [0|2047] "" Vector__XXX
 SG_ IdentityNumber : 0|21@1+ (1,0) [0|2097152] "" Vector__XXX

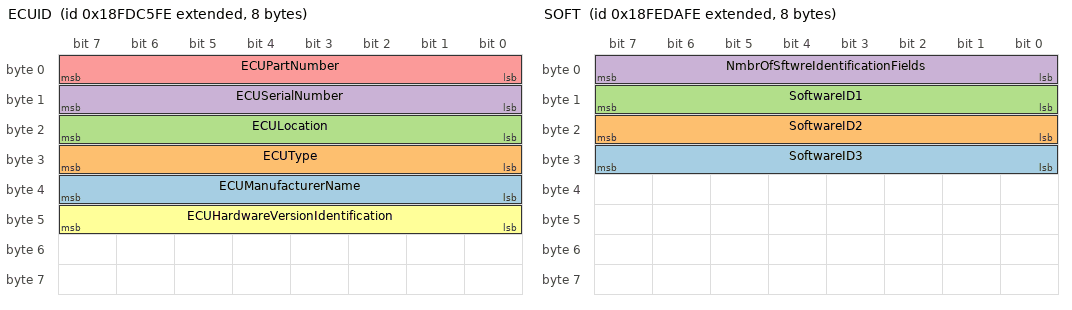
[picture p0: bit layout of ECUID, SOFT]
BO_ 2566768126 ECUID: 8 Vector__XXX
 SG_ ECUManufacturerName : 32|8@1+ (1,0) [0|255] "" Vector__XXX
 SG_ ECUType : 24|8@1+ (1,0) [0|255] "" Vector__XXX
 SG_ ECULocation : 16|8@1+ (1,0) [0|255] "" Vector__XXX
 SG_ ECUSerialNumber : 8|8@1+ (1,0) [0|255] "" Vector__XXX
 SG_ ECUPartNumber : 0|8@1+ (1,0) [0|255] "" Vector__XXX
 SG_ ECUHardwareVersionIdentification : 40|8@1+ (1,0) [0|255] "" Vector__XXX

BO_ 2566839038 SOFT: 8 Vector__XXX
 SG_ SoftwareID3 : 24|8@1+ (1,0) [0|255] "" Vector__XXX
 SG_ SoftwareID2 : 16|8@1+ (1,0) [0|255] "" Vector__XXX
 SG_ SoftwareID1 : 8|8@1+ (1,0) [0|255] "" Vector__XXX
 SG_ NmbrOfSftwreIdentificationFields : 0|8@1+ (1,0) [0|250] "steps" Vector__XXX

BO_ 2566834942 DM1: 22 Vector__XXX
 SG_ DTC5 : 144|32@1+ (1,0) [0|4294967295] "" Vector__XXX
 SG_ DTC4 : 112|32@1+ (1,0) [0|4294967295] "" Vector__XXX
 SG_ DTC3 : 80|32@1+ (1,0) [0|4294967295] "" Vector__XXX
 SG_ DTC2 : 48|32@1+ (1,0) [0|4294967295] "" Vector__XXX
 SG_ DTC1 : 16|32@1+ (1,0) [0|4294967295] "" Vector__XXX

BO_ 2566835198 DM2: 22 Vector__XXX
 SG_ DTC5 : 144|32@1+ (1,0) [0|4294967295] "" Vector__XXX
 SG_ DTC4 : 112|32@1+ (1,0) [0|4294967295] "" Vector__XXX
 SG_ DTC3 : 80|32@1+ (1,0) [0|4294967295] "" Vector__XXX
 SG_ DTC2 : 48|32@1+ (1,0) [0|4294967295] "" Vector__XXX
 SG_ DTC1 : 16|32@1+ (1,0) [0|4294967295] "" Vector__XXX

BO_ 2566734590 ICC: 8 Vector__XXX
 SG_ CertLaboratoryType_FirstDef m0 : 9|3@1+ (1,0) [0|7] "" Vector__XXX
 SG_ TestProtocolRevision_MSBits m1 : 11|2@1+ (1,0) [0|0] "" Vector__XXX
 SG_ MessageRevision M : 47|1@1+ (1,0) [0|0] "" Vector__XXX
 SG_ CertificationReferenceNumber : 48|16@1+ (1,0) [0|65535] "" Vector__XXX
 SG_ CertTypeTaskController m0 : 39|1@1+ (1,0) [0|1] "" Vector__XXX
 SG_ CertTypeTCWorkingSetMaster m0 : 38|1@1+ (1,0) [0|1] "" Vector__XXX
 SG_ CertTypeTCWorkingSetMember m0 : 37|1@1+ (1,0) [0|1] "" Vector__XXX
 SG_ CertTypeFileServer m0 : 36|1@1+ (1,0) [0|1] "" Vector__XXX
 SG_ CertTypeGPSReceiver m0 : 35|1@1+ (1,0) [0|1] "" Vector__XXX
 SG_ CertTypeMinimumECU m0 : 31|1@1+ (1,0) [0|1] "" Vector__XXX
 SG_ CertTypeTECUClass1 m0 : 30|1@1+ (1,0) [0|1] "" Vector__XXX
 SG_ CertTypeTECUClass2 m0 : 29|1@1+ (1,0) [0|1] "" Vector__XXX
 SG_ CertTypeTECUClass3 m0 : 28|1@1+ (1,0) [0|1] "" Vector__XXX
 SG_ CertTypeClass3ECU m0 : 27|1@1+ (1,0) [0|1] "" Vector__XXX
 SG_ CertTypeVirtualTerminal m0 : 26|1@1+ (1,0) [0|1] "" Vector__XXX
 SG_ CertTypeVTWorkingSetMaster m0 : 25|1@1+ (1,0) [0|1] "" Vector__XXX
 SG_ CertTypeVTWorkingSetMember m0 : 24|1@1+ (1,0) [0|1] "" Vector__XXX
 SG_ CertificationLaboratoryID : 13|11@1+ (1,0) [0|2047] "" Vector__XXX
 SG_ CertLaboratoryType_SecondDef m1 : 9|2@1+ (1,0) [0|3] "" Vector__XXX
 SG_ TestProtocolRevision : 6|3@1+ (1,0) [0|7] "" Vector__XXX
 SG_ TestProtocolPublicationYear : 0|6@1+ (1,2000) [2000|2061] "year" Vector__XXX

BO_ 2566835454 DM3: 0 Vector__XXX

BO_ 2365391614 AISO: 8 Vector__XXX
 SG_ StopAllImplOpTransitionNum : 48|8@1+ (1,0) [0|0] "" Vector__XXX
 SG_ StopAllImplOpSwitchState : 56|2@1- (1,0) [0|3] "" Vector__XXX

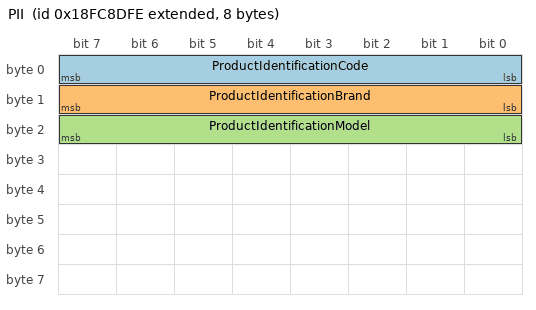
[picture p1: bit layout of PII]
BO_ 2566688254 PII: 8 Vector__XXX
 SG_ ProductIdentificationCode : 0|8@1- (1,0) [0|0] "" Vector__XXX
 SG_ ProductIdentificationBrand : 8|8@1- (1,0) [0|0] "" Vector__XXX
 SG_ ProductIdentificationModel : 16|8@1- (1,0) [0|0] "" Vector__XXX

CM_ BO_ 2498166526 "VT to ECU";
CM_ SG_ 2498166526 AuxiliaryFunctionType "Auxiliary function type of assigned auxiliary input";
CM_ SG_ 2498166526 VTChangeActiveMaskParentID "Parent object ID of error object ID";
CM_ SG_ 2498166526 VTChangeActiveMaskErrorID "Object ID containing error";
CM_ SG_ 2498166526 NumTransitionsDisabledToEnabled "Number of transitions of disabled to enabled";
CM_ SG_ 2498166526 ErrorCodePoolDeleted "VT change mask error code: Pool being deleted";
CM_ SG_ 2498166526 ErrorCodeAnyOtherError "VT change mask error code: Any other error";
CM_ SG_ 2498166526 AuxInputEnable "Auxiliary Input Enable";
CM_ SG_ 2498166526 AnalogValue "Analog value of 0xFFFF if input type is boolean";
CM_ BO_ 2565799678 "Address Claimed";
CM_ SG_ 2565799678 ReservedBit "The reserved bit shall be set to zero.";
CM_ BO_ 2566838526 "Commanded Address";
CM_ SG_ 2566838526 AddressAssignment "The source address that is to be assigned to the CA that has the NAME corresponding to the one conveyed in the first eight bytes of this Commanded Address message.";
CM_ BO_ 2566768126 "ECU Identification Information";
CM_ SG_ 2566768126 ECULocation "The location of the ECU within a network.";
CM_ SG_ 2566768126 ECUSerialNumber "The serial number of the physical ECU.";
CM_ SG_ 2566768126 ECUPartNumber "The part number of the physical ECU.";
CM_ SG_ 2566768126 ECUHardwareVersionIdentification "The part number of the physical ECU.";
CM_ BO_ 2566839038 "Software Identification";
CM_ SG_ 2566839038 SoftwareID3 "Software ID";
CM_ SG_ 2566839038 SoftwareID2 "Software ID";
CM_ SG_ 2566839038 SoftwareID1 "Software ID";
CM_ SG_ 2566839038 NmbrOfSftwreIdentificationFields "Number of software identification designators represented in the software identification parameter group.";
CM_ BO_ 2566834942 "Active diagnostic trouble codes";
CM_ SG_ 2566834942 DTC5 "Diagnostic Trouble Code";
CM_ SG_ 2566834942 DTC4 "Diagnostic Trouble Code";
CM_ SG_ 2566834942 DTC3 "Diagnostic Trouble Code";
CM_ SG_ 2566834942 DTC2 "Diagnostic Trouble Code";
CM_ SG_ 2566834942 DTC1 "Diagnostic Trouble Code";
CM_ BO_ 2566835198 "Previously active diagnostic trouble codes";
CM_ SG_ 2566835198 DTC5 "Diagnostic Trouble Code";
CM_ SG_ 2566835198 DTC4 "Diagnostic Trouble Code";
CM_ SG_ 2566835198 DTC3 "Diagnostic Trouble Code";
CM_ SG_ 2566835198 DTC2 "Diagnostic Trouble Code";
CM_ SG_ 2566835198 DTC1 "Diagnostic Trouble Code";
CM_ BO_ 2566734590 "ISOBUS compliance certification";
CM_ SG_ 2566734590 CertLaboratoryType_FirstDef "Approving body for the certification laboratory.";
CM_ SG_ 2566734590 MessageRevision "This parameter distinguishes the format of the ISOBUS Compliance Certification message in the second 
edition from the format in the third and later editions.";
CM_ SG_ 2566734590 CertificationReferenceNumber "ISOBUS Compliance certification reference number";
CM_ SG_ 2566734590 CertTypeTaskController "ISOBUS Compliance certification type - Task Controller";
CM_ SG_ 2566734590 CertTypeTCWorkingSetMaster "ISOBUS Compliance certification type - TC working set master";
CM_ SG_ 2566734590 CertTypeTCWorkingSetMember "ISOBUS Compliance certification type - TC working set member";
CM_ SG_ 2566734590 CertTypeFileServer "ISOBUS Compliance certification type - File server";
CM_ SG_ 2566734590 CertTypeGPSReceiver "ISOBUS Compliance certification type - GPS receiver";
CM_ SG_ 2566734590 CertTypeMinimumECU "ISOBUS Compliance certification type - Minimum ECU";
CM_ SG_ 2566734590 CertTypeTECUClass1 "ISOBUS Compliance certification type - TECU Class 1";
CM_ SG_ 2566734590 CertTypeTECUClass2 "ISOBUS Compliance certification type - TECU Class 2";
CM_ SG_ 2566734590 CertTypeTECUClass3 "ISOBUS Compliance certification type - TECU Class 3";
CM_ SG_ 2566734590 CertTypeClass3ECU "ISOBUS Compliance certification type - Class 3 ECU";
CM_ SG_ 2566734590 CertTypeVirtualTerminal "ISOBUS Compliance certification type - Virtual terminal";
CM_ SG_ 2566734590 CertTypeVTWorkingSetMaster "ISOBUS Compliance certification type - VT working set master";
CM_ SG_ 2566734590 CertTypeVTWorkingSetMember "ISOBUS Compliance certification type - VT working set member";
CM_ SG_ 2566734590 CertificationLaboratoryID "ISOBUS Compliance certification laboratory ID";
CM_ SG_ 2566734590 CertLaboratoryType_SecondDef "Approving body for the certification laboratory.";
CM_ SG_ 2566734590 TestProtocolRevision "ISOBUS compliance certificate revision";
CM_ SG_ 2566734590 TestProtocolPublicationYear "ISOBUS compliance certification year";
CM_ BO_ 2566835454 "Diagnostic data clear/reset of previously active DTCs.";
CM_ BO_ 2365391614 " All implements stop operations switch state";
CM_ SG_ 2365391614 StopAllImplOpTransitionNum "This parameter indicates the number of transitions from Permit (01) to Stop (00) since power up of 
the Stop all implement operations parameter. The parameter resets to zero on the next transition after 
reporting the maximum value.";
CM_ BO_ 2566688254 "Product Identification Information: Each control function of a product shall respond with the same product identification information when it 
receives the Request PGN message for this PGN.";
CM_ SG_ 2566688254 ProductIdentificationCode "The Product Identification Code as assigned by the manufacturer correspondents with the number on the type 
plate of a product.";
CM_ SG_ 2566688254 ProductIdentificationBrand "Specifies  the  brand  of  a  product.  
The  combination  of  the  Product Identification Code and the Product Identification Brand shall make the product unique in the world.";
CM_ SG_ 2566688254 ProductIdentificationModel "The Product Identification Model specifies a unique product within a Brand. ";
BA_DEF_ SG_  "DDI" INT 0 65535;
BA_DEF_ BO_  "SingleFrame" INT 0 1;
BA_DEF_ BO_  "VFrameFormat" ENUM  "StandardCAN","ExtendedCAN","reserved","J1939PG","vector_leerstring";
BA_DEF_ BO_  "GenMsgSendType" ENUM  "cyclic","NotUsed","IfActive","NotUsed","NotUsed","NotUsed","NotUsed","NotUsed","noMsgSendType","vector_leerstring";
BA_DEF_ BO_  "GenMsgCycleTime" INT 0 3600000;
BA_DEF_ BO_  "GenMsgRequestable" INT 0 1;
BA_DEF_ BO_  "GenMsgNrOfRepetition" INT 0 1000000;
BA_DEF_ BO_  "GenMsgCycleTimeFast" INT 0 3600000;
BA_DEF_ SG_  "GenSigInactiveValue" INT 0 0;
BA_DEF_ BO_  "GenMsgFastOnStart" INT 0 100000;
BA_DEF_ BO_  "GenMsgStartDelayTime" INT 0 100000;
BA_DEF_ BO_  "GenMsgILSupport" ENUM  "No","Yes";
BA_DEF_ BO_  "GenMsgDelayTime" INT 0 1000;
BA_DEF_ SG_  "SPN" INT 0 524287;
BA_DEF_ SG_  "GenSigSendType" ENUM  "Cyclic","OnWrite","OnWriteWithRepetition","OnChange","OnChangeWithRepetition","IfActive","IfActiveWithRepetition","NoSigSendType";
BA_DEF_ SG_  "SigType" ENUM  "Default","Range","RangeSigned","ASCII","Discrete","Control","ReferencePGN","DTC","StringDelimiter","StringLength","StringLengthControl","MessageCounter","MessageChecksum";
BA_DEF_ SG_  "GenSigStartValue" INT -2147483648 2147483647;
BA_DEF_ SG_  "GenSigILSupport" ENUM  "No","Yes";
BA_DEF_DEF_  "DDI" 0;
BA_DEF_DEF_  "SingleFrame" 1;
BA_DEF_DEF_  "VFrameFormat" "J1939PG";
BA_DEF_DEF_  "GenMsgSendType" "noMsgSendType";
BA_DEF_DEF_  "GenMsgCycleTime" 0;
BA_DEF_DEF_  "GenMsgRequestable" 1;
BA_DEF_DEF_  "GenMsgNrOfRepetition" 0;
BA_DEF_DEF_  "GenMsgCycleTimeFast" 0;
BA_DEF_DEF_  "GenSigInactiveValue" 0;
BA_DEF_DEF_  "GenMsgFastOnStart" 0;
BA_DEF_DEF_  "GenMsgStartDelayTime" 0;
BA_DEF_DEF_  "GenMsgILSupport" "Yes";
BA_DEF_DEF_  "GenMsgDelayTime" 0;
BA_DEF_DEF_  "SPN" 0;
BA_DEF_DEF_  "GenSigSendType" "NoSigSendType";
BA_DEF_DEF_  "SigType" "Default";
BA_DEF_DEF_  "GenSigStartValue" 0;
BA_DEF_DEF_  "GenSigILSupport" "Yes";
BA_ "GenMsgCycleTime" BO_ 2498166526 100;
BA_ "SPN" SG_ 2498166526 ManufacturerCode 2838;
BA_ "SigType" SG_ 2498166526 ManufacturerCode 1;
BA_ "SigType" SG_ 2498166526 EnteredStringValue 9;
BA_ "SigType" SG_ 2498166526 ExtendedVersionLables 3;
BA_ "SigType" SG_ 2498166526 VersionLables 3;
BA_ "SPN" SG_ 2565799678 ArbitraryAddressCapable 2844;
BA_ "SPN" SG_ 2565799678 IndustryGroup 2846;
BA_ "SPN" SG_ 2565799678 VehicleSystemInstance 2843;
BA_ "SPN" SG_ 2565799678 Function 2841;
BA_ "SPN" SG_ 2565799678 FunctionInstance 2839;
BA_ "SPN" SG_ 2565799678 ECUInstance 2840;
BA_ "SigType" SG_ 2565799678 ManufacturerCode 1;
BA_ "SPN" SG_ 2565799678 ManufacturerCode 2838;
BA_ "SPN" SG_ 2565799678 IdentityNumber 2837;
BA_ "SigType" SG_ 2566838526 AddressAssignment 1;
BA_ "SPN" SG_ 2566838526 AddressAssignment 2847;
BA_ "SPN" SG_ 2566838526 ArbitraryAddressCapable 2844;
BA_ "SPN" SG_ 2566838526 IndustryGroup 2846;
BA_ "SPN" SG_ 2566838526 VehicleSystemInstance 2843;
BA_ "SPN" SG_ 2566838526 Function 2841;
BA_ "SPN" SG_ 2566838526 FunctionInstance 2839;
BA_ "SPN" SG_ 2566838526 ECUInstance 2840;
BA_ "SigType" SG_ 2566838526 ManufacturerCode 1;
BA_ "SPN" SG_ 2566838526 ManufacturerCode 2838;
BA_ "SPN" SG_ 2566838526 IdentityNumber 2837;
BA_ "SPN" SG_ 2566768126 ECUManufacturerName 4304;
BA_ "SigType" SG_ 2566768126 ECUManufacturerName 8;
BA_ "SigType" SG_ 2566768126 ECUType 8;
BA_ "SPN" SG_ 2566768126 ECUType 2904;
BA_ "SigType" SG_ 2566768126 ECULocation 8;
BA_ "SPN" SG_ 2566768126 ECULocation 2903;
BA_ "SigType" SG_ 2566768126 ECUSerialNumber 8;
BA_ "SPN" SG_ 2566768126 ECUSerialNumber 2902;
BA_ "SigType" SG_ 2566768126 ECUPartNumber 8;
BA_ "SPN" SG_ 2566768126 ECUPartNumber 2901;
BA_ "SigType" SG_ 2566768126 ECUHardwareVersionIdentification 8;
BA_ "SigType" SG_ 2566839038 SoftwareID3 8;
BA_ "SPN" SG_ 2566839038 SoftwareID3 234;
BA_ "SigType" SG_ 2566839038 SoftwareID2 8;
BA_ "SPN" SG_ 2566839038 SoftwareID2 234;
BA_ "SigType" SG_ 2566839038 SoftwareID1 8;
BA_ "SPN" SG_ 2566839038 SoftwareID1 234;
BA_ "SigType" SG_ 2566839038 NmbrOfSftwreIdentificationFields 1;
BA_ "SPN" SG_ 2566839038 NmbrOfSftwreIdentificationFields 965;
BA_ "SigType" SG_ 2566834942 DTC5 7;
BA_ "SigType" SG_ 2566834942 DTC4 7;
BA_ "SigType" SG_ 2566834942 DTC3 7;
BA_ "SigType" SG_ 2566834942 DTC2 7;
BA_ "SigType" SG_ 2566834942 DTC1 7;
BA_ "SigType" SG_ 2566835198 DTC5 7;
BA_ "SigType" SG_ 2566835198 DTC4 7;
BA_ "SigType" SG_ 2566835198 DTC3 7;
BA_ "SigType" SG_ 2566835198 DTC2 7;
BA_ "SigType" SG_ 2566835198 DTC1 7;
BA_ "SPN" SG_ 2566734590 CertLaboratoryType_FirstDef 4315;
BA_ "SPN" SG_ 2566734590 MessageRevision 7446;
BA_ "SPN" SG_ 2566734590 CertificationReferenceNumber 4330;
BA_ "SPN" SG_ 2566734590 CertTypeTaskController 4325;
BA_ "SPN" SG_ 2566734590 CertTypeTCWorkingSetMaster 4326;
BA_ "SPN" SG_ 2566734590 CertTypeTCWorkingSetMember 4327;
BA_ "SPN" SG_ 2566734590 CertTypeFileServer 4328;
BA_ "SPN" SG_ 2566734590 CertTypeGPSReceiver 4329;
BA_ "SPN" SG_ 2566734590 CertTypeMinimumECU 4317;
BA_ "SPN" SG_ 2566734590 CertTypeTECUClass1 4318;
BA_ "SPN" SG_ 2566734590 CertTypeTECUClass2 4319;
BA_ "SPN" SG_ 2566734590 CertTypeTECUClass3 4320;
BA_ "SPN" SG_ 2566734590 CertTypeClass3ECU 4321;
BA_ "SPN" SG_ 2566734590 CertTypeVirtualTerminal 4322;
BA_ "SPN" SG_ 2566734590 CertTypeVTWorkingSetMaster 4323;
BA_ "SPN" SG_ 2566734590 CertTypeVTWorkingSetMember 4324;
BA_ "SPN" SG_ 2566734590 CertificationLaboratoryID 4316;
BA_ "SPN" SG_ 2566734590 CertLaboratoryType_SecondDef 4315;
BA_ "SPN" SG_ 2566734590 TestProtocolRevision 4314;
BA_ "SPN" SG_ 2566734590 TestProtocolPublicationYear 4313;
BA_ "SPN" SG_ 2365391614 StopAllImplOpTransitionNum 7443;
BA_ "SPN" SG_ 2365391614 StopAllImplOpSwitchState 5140;
BA_ "SPN" SG_ 2566688254 ProductIdentificationCode 6699;
BA_ "SigType" SG_ 2566688254 ProductIdentificationCode 8;
BA_ "SPN" SG_ 2566688254 ProductIdentificationBrand 6701;
BA_ "SigType" SG_ 2566688254 ProductIdentificationBrand 8;
BA_ "SPN" SG_ 2566688254 ProductIdentificationModel 6701;
BA_ "SigType" SG_ 2566688254 ProductIdentificationModel 8;
VAL_ 2498166526 ErrorCodeSelectColourMap3 0 "NoError" 1 "GeneralError" ;
VAL_ 2498166526 ErrorCodeGetAttributeValue3 1 "GeneralError" 0 "NoErrors" ;
VAL_ 2498166526 ErrorCodeGetAttributeValue2 1 "InvalidAttributeID" 0 "NoErrors" ;
VAL_ 2498166526 ErrorCodeGetAttributeValue1 1 "InvalidObjectID" 0 "NoErrors" ;
VAL_ 2498166526 ErrorCodeChangeSoftKeyMask3 1 "Missing Objects" 0 "NoErrors" ;
VAL_ 2498166526 ErrorCodeChangeSoftKeyMask4 1 "Mask or child object has errors" 0 "NoErrors" ;
VAL_ 2498166526 ErrorCodeAudioVolume3 1 "CommandNotSupported" 0 "NoErrors" ;
VAL_ 2498166526 ErrorCodeHideShowObj4 1 "GeneralError" 0 "NoErrors" ;
VAL_ 2498166526 ErrorCodeGetSupportedWideChars3 0 "NoError" 1 "GeneralError" ;
VAL_ 2498166526 Hardware8 1 "SupportOfIntermediateCoordinates" 0 "NoSupportOfIntermediateCoordinates" ;
VAL_ 2498166526 Hardware7 1 "ReportingOfDragOperations" 0 "NoReportingOfDragOperations" ;
VAL_ 2498166526 OperatingState4 0 "NoInteractionDetected" 1 "InteractionDetected" ;
VAL_ 2498166526 OperatingState3 0 "ControlIsNotLocked" 1 "ControlIsLocked" ;
VAL_ 2498166526 PathRequested 255 "Proprietary15" 254 "Proprietary14" 253 "Proprietary13" 252 "Proprietary12" 251 "Proprietary11" 250 "Proprietary10" 249 "Proprietary9" 248 "Proprietary8" 247 "Proprietary7" 246 "Proprietary6" 245 "Proprietary5" 244 "Proprietary4" 243 "Proprietary3" 242 "Proprietary2" 241 "Proprietary1" 240 "Proprietary0" 1 "VTAccessibleStorage" ;
VAL_ 2498166526 ItemRequested 255 "Proprietary15" 254 "Proprietary14" 253 "Proprietary13" 252 "Proprietary12" 251 "Proprietary11" 250 "Proprietary10" 249 "Proprietary9" 248 "Proprietary8" 247 "Proprietary7" 246 "Proprietary6" 245 "Proprietary5" 244 "Proprietary4" 243 "Proprietary3" 242 "Proprietary2" 241 "Proprietary1" 240 "Proprietary0" 0 "ScreenImage" ;
VAL_ 2498166526 AssignedAttribute2OfSet1 1 "InputIsAssigned" ;
VAL_ 2498166526 AssignedAttribute1OfSet1 0 "AuxiliaryInput" 1 "AuxiliaryFunction" ;
VAL_ 2498166526 StoreAsPreferredAssignment 0 "StoreAssignment" 1 "DoNotStoreAssignment" ;
VAL_ 2498166526 ErrorCodeChangeAttribute5 1 "GeneralError" 0 "NoErrors" ;
VAL_ 2498166526 IndustryGroup 7 "Reserved for SAE" 5 "IndustrialProcessCtrlStationary" 4 "Marine" 3 "Construction" 2 "AgriculturalAndForestry" 1 "On-Highway" 0 "Global" ;
VAL_ 2498166526 FontType_ProportionalFont 1 "Supported" 0 "NotSupported" ;
VAL_ 2498166526 FontType_FlashHidden 1 "Supported" 0 "NotSupported" ;
VAL_ 2498166526 FontType_FlashInverted 1 "Supported" 0 "NotSupported" ;
VAL_ 2498166526 FontType_InvertedText 1 "Supported" 0 "NotSupported" ;
VAL_ 2498166526 ErrorCodeChangePolygonScale5 0 "NoError" 1 "GeneralError" ;
VAL_ 2498166526 FontType_ItalicsText 1 "Supported" 0 "NotSupported" ;
VAL_ 2498166526 FontType_UnderlinedText 1 "Supported" 0 "NotSupported" ;
VAL_ 2498166526 FontType_CrossedOutText 1 "Supported" 0 "NotSupported" ;
VAL_ 2498166526 OperatingState2 0 "InputNotActivatedInLearnMode" 1 "InputActivatedInLearnMode" ;
VAL_ 2498166526 FontType_BoldText 1 "Supported" 0 "NotSupported" ;
VAL_ 2498166526 ErrorCodeChangePolygonScale1 0 "NoError" 1 "InvalidObjectId" ;
VAL_ 2498166526 OperatingState1 0 "LearnModeInactive" 1 "LearnModeActive" ;
VAL_ 2498166526 VTBusyCode8 1 "VTIsOutOfMemory" ;
VAL_ 2498166526 FontSize_128x192 1 "Supported" 0 "NotSupported" ;
VAL_ 2498166526 VTBusyCode7 1 "AuxiliaryControlsLearnModeActive" ;
VAL_ 2498166526 FontSize_128x128 1 "Supported" 0 "NotSupported" ;
VAL_ 2498166526 VTBusyCode5 1 "VTIsBusyParsingAnObjectPool" ;
VAL_ 2498166526 FontSize_96x128 1 "Supported" 0 "NotSupported" ;
VAL_ 2498166526 ErrorCodeGetSupportedWideChars2 0 "NoError" 1 "ErrorInCodePlane" ;
VAL_ 2498166526 ErrorCodeChangeListItem5 1 "ValueInUse" 0 "NoErrors" ;
VAL_ 2498166526 ErrorCodeChangeListItem4 1 "ValueInUse" 0 "NoErrors" ;
VAL_ 2498166526 VTBusyCode4 1 "VTIsBusyExecutingMacro" ;
VAL_ 2498166526 FontSize_64x96 1 "Supported" 0 "NotSupported" ;
VAL_ 2498166526 ErrorCodeObjectPool4 1 "ObjectPoolWasDeletedFromVolatile" 0 "NoErrors" ;
VAL_ 2498166526 VTBusyCode3 1 "VTIsBusyExecutingCommand" ;
VAL_ 2498166526 FontSize_64x64 1 "Supported" 0 "NotSupported" ;
VAL_ 2498166526 ErrorCodeChangeListItem3 1 "InvalidNewListItemObjectID" 0 "NoErrors" ;
VAL_ 2498166526 ErrorCodeObjectPool3 1 "GeneralError" 0 "NoErrors" ;
VAL_ 2498166526 VTBusyCode2 1 "VTIsBusySavingDataToNonVolMemory" ;
VAL_ 2498166526 FontSize_48x64 1 "Supported" 0 "NotSupported" ;
VAL_ 2498166526 ErrorCodeChangeListItem2 1 "InvalidListIndex" 0 "NoErrors" ;
VAL_ 2498166526 ErrorCodeObjectPool2 1 "UnknownObjectReference" 0 "NoErrors" ;
VAL_ 2498166526 VTBusyCode1 1 "VTIsBusyUpdatingVisibleMask" ;
VAL_ 2498166526 FontSize_32x48 1 "Supported" 0 "NotSupported" ;
VAL_ 2498166526 ErrorCodeGetSupportedWideChars1 0 "NoError" 1 "TooManyRanges" ;
VAL_ 2498166526 ErrorCodeChangeListItem1 1 "InvalidListObjectID" 0 "NoErrors" ;
VAL_ 2498166526 Function 43 "Transmission Display" 44 "Exhaust Emission Control" 45 "Vehicle Dynamic Stability Control" 46 "Oil Sensor Unit" 47 "Information System Controller" 48 "Ramp Control" 49 "Clutch/Converter Control" 50 "Auxiliary Heater" 51 "Forward-Looking Collision Warning System" 52 "Chassis Controller" 53 "Alternator/Charging System" 54 "Communications Unit, Cellular" 55 "Communications Unit, Satellite" 56 "Communications Unit, Radio" 57 "Steering Column Unit" 58 "Fan Drive Control" 59 "Starter" 60 "Cab Display" 61 "File Server/Printer" 62 "On-Board Diagnostic Unit" 63 "Engine Valve Controller" 64 "Endurance Braking" 65 "Gas Flow Measurement" 66 "I/O Controller" 67 "Electrical System Controller" 68 "Aftertreatment system gas measurement" 69 "Engine Emission Aftertreatement System" 70 "Auxiliary Regeneration Device" 71 "Transfer Case Control" 72 "Coolant Valve Controller" 73 "Rollover Detection Control" 74 "Lubrication System" 75 "Supplemental Fan" 76 "Temperature Sensor" 77 "Fuel Properties Sensor" 78 "Fire Suppression System" 79 "Power Systems Manager" 80 "Electric Powertrain" 81 "Hydraulic Powertrain" 82 "File Server" 83 "Printer" 84 "Start Aid Device" 85 "Engine Injection Control Module" 86 "Reserved" 87 "Reserved" 88 "Reserved" 89 "Reserved" 90 "Reserved" 91 "Reserved" 92 "Reserved" 93 "Reserved" 94 "Reserved" 95 "Reserved" 96 "Reserved" 97 "Reserved" 98 "Reserved" 99 "Reserved" 100 "Reserved" 0 "Engine" 1 "Auxiliary Power Unit (APU)" 2 "Electric Propulsion Control" 3 "Transmission" 4 "Battery Pack Monitor" 5 "Shift Control/Console" 6 "Power TakeOff - (Main or Rear)" 7 "Axle - Steering" 8 "Axle - Drive" 9 "Brakes - System Controller" 10 "Brakes - Steer Axle" 11 "Brakes - Drive Axle" 12 "Retarder - Engine" 13 "Retarder - Driveline" 14 "Cruise Control" 15 "Fuel System" 16 "Steering Controller" 17 "Suspension - Steer Axle" 18 "Suspension - Drive Axle" 19 "Instrument Cluster" 20 "Trip Recorder" 21 "Cab Climate Control" 22 "Aerodynamic Control" 23 "Vehicle Navigation" 24 "Vehicle Security" 25 "Network Interconnect ECU" 26 "Body Controller" 27 "Power TakeOff (Secondary or Front)" 28 "Off Vehicle Gateway" 29 "Virtual Terminal (in cab)" 30 "Management Computer" 31 "Propulsion Battery Charger" 32 "Headway Controller" 33 "System Monitor" 34 "Hydraulic Pump Controller" 35 "Suspension - System Controller" 36 "Pneumatic - System Controller" 37 "Cab Controller" 38 "Tire Pressure Control" 39 "Ignition Control Module" 40 "Seat Control" 41 "Lighting - Operator Controls" 42 "Water Pump Control" 101 "Reserved" 102 "Reserved" 103 "Reserved" 104 "Reserved" 105 "Reserved" 106 "Reserved" 107 "Reserved" 108 "Reserved" 109 "Reserved" 110 "Reserved" 111 "Reserved" 112 "Reserved" 113 "Reserved" 114 "Reserved" 115 "Reserved" 116 "Reserved" 117 "Reserved" 118 "Reserved" 119 "Reserved" 120 "Reserved" 121 "Reserved" 122 "Reserved" 123 "Reserved" 124 "Reserved" 125 "Reserved" 126 "Reserved" 127 "Reserved" 255 "Not Available" ;
VAL_ 2498166526 ErrorCodeObjectPool1 1 "MethodOrAttributeNotSupportedByV" 0 "NoErrors" ;
VAL_ 2498166526 SoftKeyCode 0 "AlarmACK" ;
VAL_ 2498166526 BooleanValue 0 "Disabled" 1 "Enabled" 2 "EnabledStillHeld" ;
VAL_ 2498166526 Status_2 0 "Hidden" 1 "Shown" ;
VAL_ 2498166526 ErrorCodeVTChangeSoftKeyMask4 1 "PoolBeingDeleted" 0 "NoError" ;
VAL_ 2498166526 FontSize_32x32 1 "Supported" 0 "NotSupported" ;
VAL_ 2498166526 FontSize_24x32 1 "Supported" 0 "NotSupported" ;
VAL_ 2498166526 FontSize_16x24 1 "Supported" 0 "NotSupported" ;
VAL_ 2498166526 ErrorCodeChangePosInvalidError 1 "GeneralError" 0 "NoErrors" ;
VAL_ 2498166526 ErrorCodeChangeSoftKeyMask5 1 "GeneralError" 0 "NoErrors" ;
VAL_ 2498166526 ErrorCodeChangeChildLocation5 1 "GeneralError" 0 "NoErrors" ;
VAL_ 2498166526 ErrorCodeVTChangeSoftKeyMask3 1 "GeneralError" 0 "NoError" ;
VAL_ 2498166526 ErrorCodeChangeStrValueInUse 1 "ValueInUse" 0 "NoErrors" ;
VAL_ 2498166526 ErrorCodeVtObjPoolError4 1 "OtherError" 0 "NoErrors" ;
VAL_ 2498166526 FontSize_16x16 1 "Supported" 0 "NotSupported" ;
VAL_ 2498166526 ErrorCodeChangeStrError 1 "GeneralError" 0 "NoErrors" ;
VAL_ 2498166526 ErrorCodeVTChangeSoftKeyMask2 1 "MaskOrChildObjectHasErrors" 0 "NoError" ;
VAL_ 2498166526 ErrorCodeVtObjPoolError3 1 "RecursiveObjectReference" 0 "NoErrors" ;
VAL_ 2498166526 FontSize_12x16 1 "Supported" 0 "NotSupported" ;
VAL_ 2498166526 ErrorCodeChangeStrTooLong 1 "StringTooLong" 0 "NoErrors" ;
VAL_ 2498166526 ErrorCodeVTChangeSoftKeyMask1 1 "MissingObjects" 0 "NoError" ;
VAL_ 2498166526 ErrorCodeVtObjPoolError2 1 "UnknownObjectReference" 0 "NoErrors" ;
VAL_ 2498166526 FontSize_8x12 1 "Supported" 0 "NotSupported" ;
VAL_ 2498166526 ErrorCodeChangePosInvalidObject 1 "InvalidObjectID" 0 "NoErrors" ;
VAL_ 2498166526 ErrorCodeChangeStrObjectID 1 "InvalidObjectID" 0 "NoErrors" ;
VAL_ 2498166526 ErrorCodeChangeSoftKeyMask2 1 "InvalidSoftKeyMaskObjectID" 0 "NoErrors" ;
VAL_ 2498166526 ErrorCodeChangeChildLocation2 1 "InvalidObjectID" 0 "NoErrors" ;
VAL_ 2498166526 ErrorCodeVtObjPoolError1 1 "UnsupportedMethodOrAttribute" 0 "NoErrors" ;
VAL_ 2498166526 AcknowledgmentDeleteVersion 8 "GeneralError" 4 "NA" 2 "VersionLabelIsNotCorrect" 0 "SuccessfullyDeleted" ;
VAL_ 2498166526 AcknowledgmentLoadVersion 8 "GeneralError" 4 "InsufficientMemoryAvailable" 2 "VersionLabelNotCorrectOrUnknown" 0 "SuccessfullyLoaded" ;
VAL_ 2498166526 AcknowledgmentStoreVersion 8 "GeneralError" 4 "InsufficientMemoryAvailable" 2 "VersionLabelIsNotCorrect" 0 "SuccessfullyStored" ;
VAL_ 2498166526 FontSize_8x8 1 "Supported" 0 "NotSupported" ;
VAL_ 2498166526 ErrorCodeChangePosInvalidParent 1 "InvalidParentObjectID" 0 "NoErrors" ;
VAL_ 2498166526 ErrorCodeChangeSoftKeyMask1 1 "InvalidDataOrAlarmMaskObjectID" 0 "NoErrors" ;
VAL_ 2498166526 ErrorCodeChangeChildLocation1 1 "InvalidParentObjectID" 0 "NoErrors" ;
VAL_ 2498166526 TouchState 0 "Released" 1 "Pressed" 2 "Held" 255 "Pressed" ;
VAL_ 2498166526 ErrorCodeSelectObject6 1 "InvalidOptionValue" 0 "NoErrors" ;
VAL_ 2498166526 ErrorCodeGraphicsContextCmd5 0 "NoError" 1 "GeneralError" ;
VAL_ 2498166526 ErrorCodeChangePriority3 1 "GeneralError" 0 "NoErrors" ;
VAL_ 2498166526 ErrorCodeChangeAttribute4 1 "ValueInUse" 0 "NoErrors" ;
VAL_ 2498166526 ErrorCodeChangeColour3 1 "GeneralError" 0 "NoErrors" ;
VAL_ 2498166526 ErrorCodeSelectObject5 1 "GeneralError" 0 "NoErrors" ;
VAL_ 2498166526 ErrorCodeEnableDisableObj4 1 "GeneralError" 0 "NoErrors" ;
VAL_ 2498166526 ErrorCodeGraphicsContextCmd4 0 "NoError" 1 "CommandWillProduceInvalidResults" ;
VAL_ 2498166526 ErrorCodeSelectObject4 1 "CouldNotComplete" 0 "NoErrors" ;
VAL_ 2498166526 ErrorCodeEnableDisableObj3 0 "NoErrors" 1 "Could not complete. Operator inp" ;
VAL_ 2498166526 ErrorCodeHideShowObj3 1 "CommandError" 0 "NoErrors" ;
VAL_ 2498166526 ErrorCodeGraphicsContextCmd3 0 "NoError" 1 "InvalidParameter" ;
VAL_ 2498166526 ErrorCodeChangeAttribute3 1 "InvalidValue" 0 "NoErrors" ;
VAL_ 2498166526 ErrorCodeSelectObject3 1 "ObjectIsNotVisible" 0 "NoErrors" ;
VAL_ 2498166526 ErrorCodeEnableDisableObj2 1 "CommandError" 0 "NoErrors" ;
VAL_ 2498166526 ErrorCodeGraphicsContextCmd2 0 "NoError" 1 "InvalidCommandID" ;
VAL_ 2498166526 ErrorCodeChangePriority2 1 "InvalidPriority" 0 "NoErrors" ;
VAL_ 2498166526 ErrorCodeChangeAttribute2 1 "InvalidAttributeID" 0 "NoErrors" ;
VAL_ 2498166526 ErrorCodeChangeColour2 1 "InvalidColourCode" 0 "NoErrors" ;
VAL_ 2498166526 ErrorCodeSelectObject2 1 "InvalidObjectID" 0 "NoErrors" ;
VAL_ 2498166526 ErrorCodeEnableDisableObj1 1 "InvalidObjectID" 0 "NoErrors" ;
VAL_ 2498166526 ErrorCodeHideShowObj2 1 "InvalidObjectID" 0 "NoErrors" ;
VAL_ 2498166526 ErrorCodeGraphicsContextCmd1 0 "NoError" 1 "InvalidObjectID" ;
VAL_ 2498166526 ErrorCodeChangePriority1 1 "InvalidObjectID" 0 "NoErrors" ;
VAL_ 2498166526 ErrorCodeChangeAttribute1 1 "InvalidObjectID" 0 "NoErrors" ;
VAL_ 2498166526 ErrorCodeChangeColour1 1 "InvalidObjectID" 0 "NoErrors" ;
VAL_ 2498166526 ErrorCodeSelectObject1 0 "NoErrors" 1 "ObjectIsDisabled" ;
VAL_ 2498166526 ErrorCodeHideShowObj1 1 "ReferencesToMissingObjects" 0 "NoErrors" ;
VAL_ 2498166526 VTSelectInputObjectIsEdited 1 "ObjectIsOpenForEditing" 0 "ObjectIsNotEdited" ;
VAL_ 2498166526 Hardware6 1 "SimultaneousActivationsOfButtons" 0 "NoSimultaneousActivationsOfButtons" ;
VAL_ 2498166526 ErrorCodeChangeFont6 1 "GeneralError" 0 "NoErrors" ;
VAL_ 2498166526 ManufacturerCode 1077 "Ymer Technology" 1076 "DOGA S.A." 1075 "Uniden America Corporation" 1074 "Kindhelm / Navigs Oy" 1073 "Manitou Equipment America LLC" 1072 "La Marche Manufacturing Company" 1071 "MACH SYSTEMS s.r.o." 1070 "Quick-teck Electronics Ltd" 1069 "Lithionics Battery LLC" 1068 "Zapi S.p.A." 1067 "Tecomec S.r.l." 1066 "Spot Zero Water" 1065 "CALYPSO Instruments" 1064 "Omnitech Robotics Inc." 1063 "SolSteer" 1062 "Marol Co Ltd" 1061 "Volvo Construction Equipment" 1060 "Scale-Tec" 1059 "Boatrax" 1058 "Bondioli & Pavesi SpA" 1057 "EquipmentShare" 1056 "Lithium Pros" 1055 "EXA Computing GmbH" 1054 "Schmotzer Hacktechnik GmbH & Co. KG" 1053 "Vetus Maxwell, Inc." 1052 "Pfreundt" 1051 "ProNav AS" 1050 "Spacenus GmbH" 1049 "S&S Cycle" 1048 "Agrivation UG" 1047 "Sonic Corporation" 1046 "Praxidyn" 1045 "CMR Group" 1044 "Xee" 1043 "Hyva" 1042 "engcon group" 1041 "EZ Lynk" 1040 "BPE Electronics Srl" 1039 "Liugong Dressta Machinery" 1038 "EMIT Technologies, Inc." 1037 "Dragonfly Energy Corp." 1036 "Bender GmbH & Co. KG" 1035 "Agres" 1034 "Siren Marine" 1033 "ECCO Safety Group" 1032 "SIMOL S.p.A." 1031 "Flintec UK Ltd." 1030 "Tume-Agri Oy" 1029 "The Marine Guardian LLC" 1028 "Autel Intelligent Technology Corp., Ltd" 1027 "Goldacres PTY LTD" 1026 "ZTR Control Systems, LLC" 1025 "eze System, Inc." 1024 "Inventus Power" 1023 "PEAK-System Technik GmbH" 1022 "ITC Inc" 1021 "Entratech Systems LLC" 1020 "Onyx Marine Automation s.r.l." 1019 "Codek Foundries" 1018 "Flex TTS" 1017 "Caldaro AB" 1016 "Röhren- und Pumpenwerk BAUER GmbH" 1015 "SECURITAG SAS" 1014 "Briri Maschinenbau GmbH" 1013 "Allochis E-Tec" 1012 "Rhodan Marine Systems of Florida LLC" 1011 "Soundmax Electronics Ltd" 1010 "Agricultural Industry Electronics Foundation e.V." 1009 "TouchTronics, Inc." 1008 "Lintest Systems LLC" 1007 "Maschinenfabrik Meyer-Lohne GmbH" 1006 "Proterra" 1005 "TSE Brakes, Inc." 1004 "Ultraflex SpA" 1003 "technotrans SE" 1002 "Kussmaul Electronics Co." 1001 "Cleral Inc." 1000 "Landmaschinen Wienhoff GmbH" 1569 "621 Technologies Inc." 999 "TerraTroniq B.V." 998 "Transcell Technology Inc" 997 "Xenta Systems Srl" 996 "Eniquest Pty Ltd" 995 "Circuitlink Pty Ltd." 994 "Morris Industries Ltd." 993 "Alelion Energy Systems AB" 992 "MarineIOT LLC" 991 "Deutronic Elektronik GmbH" 990 "SAMSUNG SDI Co., Ltd." 989 "Flux-Geräte GmbH" 988 "Voith Turbo" 987 "Baltic Car Equipment" 986 "AAMP Global" 985 "NLR, LLC" 984 "E-T-A Elektrotechnische Apparate GmbH" 983 "Dezwaef NV" 982 "Briggs & Stratton Corporation" 981 "Kobelt Manufacturing Co. Ltd" 980 "Gussi Italia S.R.L." 979 "McHale" 978 "Canfield Connector" 977 "Emerson Electric Co." 976 "Derive Systems, Inc." 975 "Siemens AG" 974 "Pico Technology Limited" 973 "Zasso GmbH" 972 "Axion AG" 971 "B+B Smartworx" 970 "Jaboni Power Products, LLC" 969 "Blue Sea Systems" 968 "Cox Powertrain Limited" 967 "Moteck Electric Corp." 966 "VisibleFarm" 965 "Ro-Sys Software" 964 "AgroVIR Kft" 963 "Thomason Jones Company, LLC" 962 "Timbolier Industries, Inc." 961 "POK SAS" 960 "Vemcon GmbH" 959 "Cascade Corporation" 958 "NHK MEC Corporation" 957 "Sierra Wireless Inc" 956 "Piher Sensors & Controls S.A." 955 "Hottinger Baldwin (Suzhou) Electronic Measurement Technology Co., Ltd." 954 "Setec Pty Ltd" 953 "Curtiss-Wright" 952 "Tan Delta Systems Ltd" 951 "Exor International S.p.A." 950 "RE:Lab s.r.l." 949 "Škoda Electric a.s." 948 "Donix" 947 "Gerd Bär GmbH" 946 "Hydac Tecnologia Ltda" 945 "Equalizer AG" 944 "ZONTISA Marine SL" 943 "FISCHER AG Präzisionspindeln" 942 "Vogelsang GmbH & Co. KG" 941 "Navya" 940 "Dometal Oy" 939 "Warn Industries, Inc." 938 "LEVEL Systems" 937 "Precision Circuits Inc" 936 "Hi-tech Millennium" 935 "Meels GmbH & Co. KG" 934 "Farmobile, Inc." 933 "Delta Mobile Systems, Inc." 932 "Discover Battery" 931 "Enertec Marine Ltd" 930 "Ecotronix Corp." 929 "Jl Marine Systems, Inc." 928 "EAO Automotive GmbH & Co. KG" 927 "Saicon" 926 "Buhler Industries Inc." 925 "GW Lisk Company" 924 "PAS Peschak Autonome Systeme GmbH" 923 "ELTEK S.p.A." 922 "Terberg Benschop B.V." 921 "ROPA Fahrzeug- und Maschinenbau GmbH" 920 "MTD Consumer Group Inc." 919 "Furrion LLC" 918 "AMW Machine Control, Inc" 917 "Sentinel d.o.o." 916 "Turck Inc." 915 "Dosificacion y sistemas electronicos S.L. (DSE)" 914 "ZETOR TRACTORS a.s." 913 "Toyota Motor Corporation" 912 "Steyr Motors GmbH" 911 "Nautic-On" 910 "Hermann Paus Maschinenfabrik GmbH" 909 "Marines Co., Ltd." 908 "Chonbuk National University Department of Electronics" 907 "strautmann" 906 "MOBA AG" 905 "ASA Electronics" 904 "Equipment Safety Systems Pty. Ltd. (EQSS)" 903 "InMotion" 902 "Bucher Hydraulics" 901 "Zivan Srl" 900 "OSB AG" 899 "Lippert Components, Inc" 898 "Josef Kotte Landtechnik GmbH & Co. KG" 897 "Dot Technology Corp." 896 "NextFour Solutions Ltd" 895 "Peloton Technology" 894 "Rhodan Marine Systems of Florida LLC" 893 "KlinkTechnics Ltd." 892 "Mectronx Corp" 891 "CarrierWeb" 890 "L3 Technologies, Inc." 889 "SANY America Inc" 888 "Carma Systems Inc" 887 "Hyperdrive Innovation Limited" 886 "Hitachi Zosen Corporation" 885 "SICK Stegmann GmbH" 884 "Sure Grip Controls Inc." 883 "Swift Navigation, Inc." 882 "BHTronik GmbH & Co. KG" 881 "Sovema" 880 "Revision Military" 879 "PG Trionic, Inc." 878 "FOTON" 877 "SICK ATech GmbH" 876 "SUCO Robert Scheuffele GmbH & Co. KG" 875 "Salvarani S.r.l." 874 "MTA S.p.A." 873 "Garnet Instruments Ltd." 872 "Kählig Antriebstechnik GmbH" 871 "Superior Tech Inc" 870 "Textron Fleet Management" 869 "Intercomp" 868 "Data Panel Corp" 867 "Skeleton Technologies" 866 "Netradyne, Inc." 865 "MyEasyFarm" 864 "Streamline Transportation Technologies Inc." 863 "SMAG" 862 "Prospec Electronics" 861 "Adel System S.r.l." 860 "Michelin" 859 "Valor" 858 "Littelfuse" 857 "Zoomlion Heavy Industry NA, Inc" 856 "FarmFacts GmbH" 855 "Toshiba Infrastructure Systems & Solutions Corporation" 854 "GEMAC Chemnitz GmbH" 853 "Teledyne RESON B.V." 852 "Velvac Inc" 851 "Novotechnik Messwertaufnehmer OHG" 850 "Geoprospectors GmbH" 849 "MTS Maschinentechnik Schrode AG" 848 "ningupex" 847 "Oceanvolt" 846 "L3 Magnet-Motor" 845 "GMB Güstrower Maschinenbau GmbH" 844 "FELL AS" 843 "Hendrickson Truck Commercial Vehicle Systems" 842 "DigiDevice Srl" 841 "Agra-GPS" 840 "E.S.T.E. Srl" 839 "Indexator Rotator Systems AB" 838 "Teamsurv Ltd" 837 "Famic Technologies Inc." 836 "Signature4" 835 "PetTrack Ltd." 834 "Pioneer Microsystems, Inc." 833 "Electrum Automation AB" 832 "Heizomat Gerätebau-Energiesysteme GmbH" 831 "DOK-ING Ltd." 830 "Ultra Motion LLC" 829 "Drov Technologies, Inc." 828 "AgriBrink Inc." 827 "INmatix Technology Group Ltd" 826 "Lewmar Marine Inc" 825 "BPW Hungária" 824 "Undheim Systems AS" 823 "ACEINNA, Inc (formerly MEMSIC, Inc)" 822 "Bren-Tronics, Inc." 821 "Thorsen Teknik A/S" 820 "DIaLOGIKa Gesellschaft fuer angewandte Informatik mbH" 819 "Preco Electronics" 818 "HGNSS" 817 "TE Connectivity Sensor Solutions" 816 "UniStrong" 815 "FLIR Systems, Inc." 814 "Kronotech Srl (formerly Soltec Soluzioni Tecnologiche Srl)" 813 "Thales Suisse SA" 812 "Torch Technologies" 811 "Blue Water Desalination" 810 "Dutch Power Company" 809 "HMS Industrial Networks AB" 808 "RIMEX Supply Ltd." 807 "Schneider-Electric" 806 "Charge Automotive Ltd" 805 "Gundersen & Løken AS" 804 "ASA Electronics" 803 "Gill Sensors & Controls Limited" 802 "SPBI (Bj Technologie)" 801 "LOR Manufacturing Company Inc." 800 "Delta-Q Technologies" 799 "Stillwater Designs and Audio, Inc. - KICKER" 798 "Lumishore Ltd" 797 "Tides Marine" 796 "Canadian Automotive Industries Ltd" 795 "Broyda Enterprises Pty Ltd" 794 "Shihlin Electric & Engineering Corporation" 793 "James Fisher Prolec" 792 "Kostal Mexicana" 791 "AUTEC" 790 "VACALL" 789 "GRADALL" 788 "MoTeC Pty Ltd" 787 "Abertax Technologies Limited" 1863 "Thomas G. Faria Co." 1862 "Sanshin" 1861 "Vector North America" 1860 "MMP" 1859 "Kvasar AB" 1858 "Litton" 1857 "Simrad" 1856 "Trimble" 1855 "Furuno USA" 1854 "Northstar Technologies" 1853 "Japan Radio Co" 1852 "Navionics" 1851 "RayMarine" 1850 "Seastar Solutions (formerly Teleflex)" 786 "Johnson Matthey Battery Systems" 785 "Fischer Panda GmbH" 784 "CM Automotive Systems, Inc." 783 "Loup Electronics Inc." 782 "AVR bv (formerly AVR bvba)" 781 "Poly-Planar LLC" 780 "AVID Technology Ltd" 779 "RLC Electronic Systems" 778 "Seakeeper Inc." 777 "Ocean Signal Ltd" 776 "HMI Systems LLC" 775 "ZIEHL-ABEGG Automotive GmbH" 774 "Taisho Corporation" 773 "Clarion Corporation of America" 772 "Blink Marine" 771 "Shaw Development, LLC" 770 "MONOSEM" 769 "Trombetta" 768 "Flores Automation, LLC" 767 "Alliance Wireless Technologies Inc." 766 "Epec Oy" 765 "GIGAVAC" 764 "Bednar FMT s.r.o." 763 "AT-Systems BVBA" 762 "ROJ s.r.l." 761 "MITA OLEODINAMICA S.p.A." 760 "Bernecker + Rainer Industrie Elektronik GmbH" 759 "Hydro-Gear" 758 "Banner Engineering Corp." 757 "IMPCO Technologies" 756 "Maschio Gaspardo S.P.A." 755 "Firefly Integrations" 754 "Parker Hannifin Corp., Automation Group" 753 "AIROD Technologies" 752 "Deep Sea Electronics Plc" 751 "Pacific Track" 750 "Joskin SA" 749 "Chart Inc." 748 "ISOTTA" 747 "Agratronix" 746 "SureFire Ag Systems, Inc." 745 "Cidra Corporate Services Inc." 744 "Woosung Engineering Co., Ltd." 743 "Daemyung Elevator Co., Ltd." 742 "EROAD" 741 "Carling Technologies" 740 "e-Traction" 739 "LXNAV d.o.o." 738 "Blue Ink Technologies" 737 "Balluff GmbH" 736 "Terex Aerial Work Platforms - Genie" 735 "AEM Performance Electronics" 734 "REAPsystems" 733 "Intendia S.L." 732 "Gefran S.p.A." 731 "Modine Manufacturing Company" 730 "BERTHOUD AGRICOLE" 729 "Liebherr" 728 "Streumaster (formerly Streumaster / Panien)" 727 "Dhoot Transmission Pvt Ltd." 726 "MIDORI PRECISIONS" 725 "Hitachi Construction Machinery Co., Ltd." 724 "Electronic Applications, Inc." 723 "Jabil Inc." 722 "Contelec AG" 721 "Hypro" 720 "WITZ Corporation" 719 "Cojali S. L." 718 "Micronet Inc" 717 "Yacht Devices Ltd" 716 "Eaton Control & Power Conversion Division (CPCD)" 715 "Autonnic Research Ltd" 714 "Kobashi Kogyo Co., Ltd." 713 "US Hybrid Corporation" 712 "LOR Manufacturing Company Inc." 711 "DAS Co., LTD" 710 "Greentronics Ltd." 709 "Marquardt GmbH" 708 "Lars Thrane A/S" 707 "Rochester Gauges Inc" 706 "Shanghai Diesel Engine Corporation Limited" 705 "SVAB Hydraulik AB" 704 "JL Audio, Inc." 703 "Hydro Tab Marine Engineering" 702 "Weichai Power Co., Ltd." 701 "BigRoad Inc." 700 "K-Tec Earthmovers Inc." 699 "Harman International Industries" 698 "Scorpion Technologies Ltd." 697 "Ålö AB" 696 "DRS Network & Imaging Systems, LLC (DRS Technologies)" 695 "Weldon Technologies" 694 "GasTOPS Ltd." 693 "Agility Fuel Solutions (formerly Agility Fuel Systems)" 692 "Tanhay Corporation" 691 "Digitroll Agricultural Electronics" 690 "LINAK A/S" 689 "Aarcomm Systems Inc" 688 "Rockford Corp" 687 "Flight Systems, Inc." 686 "Taigene Electric Machinery Corp." 685 "ANEDO (formerly ANEDO Ltd.)" 684 "KEB" 683 "Fosen Elektro" 682 "Eckelmann AG" 681 "BEDIA Motorentechnik GmbH & Co. KG" 680 "AMVAC Chemical Corporation" 679 "Cimco Marine AB" 678 "KeepTruckin, Inc." 677 "DSA Daten- und Systemtechnik GmbH" 676 "Danfoss IXA A/S" 675 "Kawasaki Motors Corp., USA" 674 "Yara International ASA" 673 "Caruelle Nicolas" 672 "OPTIMA Concept" 671 "Innovative Controls Inc." 670 "STEMCO LP" 669 "Quantum Fuel Systems Technologies Worldwide, Inc" 668 "MacDon Industries Ltd." 667 "Bartec" 666 "Schaeffler Technologies AG & Co., KG" 665 "Gebr. Bode GmbH & Co. KG" 664 "Level Developments Ltd" 663 "Delta Systems, Inc" 662 "Kissling Elektrotechnik GmbH" 661 "SPAL Automotive S.r.l." 660 "Auto-Gaz Centrum" 659 "Data Panel Corp." 658 "Shenzhen Jiuzhou Himunication Technology Co., Ltd" 657 "Terzo Power Systems" 656 "PRO SOLUS do Brasil" 655 "Genge & Thoma AG" 654 "Kohler Power Systems, Detroit Engine Development Center (DEDC)" 653 "AEV, spol. s r. o." 652 "MicroControl GmbH & Co. KG" 651 "Takakita Co, Ltd." 650 "Seiko Epson Corp." 649 "Control-Q B.V." 648 "OJSC Ekran" 647 "Siloking" 646 "Veenhuis Machines B.V." 645 "esd electronic system design gmbh" 644 "KUS USA" 643 "Bogballe A/S" 642 "Moog / Aspen Motion Technologies" 641 "Diverse Yacht Services" 640 "Power Solutions International" 639 "Startec s.r.l." 638 "KVH Industries, Inc." 637 "Bavaria Yachtbau GmbH" 636 "Divelbiss Corporation" 635 "Argo Tractors S.p.A." 634 "Rocky Research" 633 "TORC Robotics" 632 "Pepperl+Fuchs GmbH" 631 "Reltima" 630 "SmartDrive Systems Inc." 629 "Agri Info Design, Ltd." 524 "Vomax Instrumentation Pty. Ltd." 523 "Reggio Emilia Innovazione" 522 "Nebraska Tractor Test Laboratory" 521 "Clever Devices Ltd." 520 "Trapeze" 519 "Peeters Landbouwmachines b.v." 518 "Transas USA Inc." 517 "Noland Engineering" 516 "AVAT Automation GmbH" 515 "GINAF Trucks Nederland B.V." 514 "DISTek Integration, Inc." 513 "Precision Technology (Formerly FarmscanAg)" 512 "Inpower LLC" 511 "Sulky" 510 "Marinesoft Co. Ltd" 509 "MOTORTECH GmbH" 508 "Transtech Innovations" 507 "ISOBUS Test Center" 506 "IHI STAR Machinery Corporation" 505 "Yetter Farm Equipment" 504 "Vesper Marine" 503 "Naviop S.R.L." 502 "Attwood Corporation" 501 "Agrotronix S.A." 500 "Oxbo International Corporation" 499 "LCJ Capteurs" 498 "Innovative Design Solutions, Inc." 497 "SENTRON Sistemas Embarcados" 496 "W. Gessmann GmbH" 495 "HOLMER Maschinenbau GmbH" 494 "Synerject" 493 "Watcheye" 492 "Inergy Automotive Systems" 491 "Penny and Giles Ltd" 490 "QuikQ" 489 "Appareo Systems, LLC" 488 "The Charles Machine Works, Inc." 487 "DSE Test Solutions A/S" 486 "Westport Innovations Inc." 485 "MATT automotive" 484 "Headsight Inc." 483 "Valeo" 482 "Tricon Electronics" 481 "Chetco Digital Instruments" 480 "EnerDel, Inc." 479 "Vapor Bus International" 478 "OceanSat B.V." 477 "OilQuick AB" 476 "Hummingbird Marine Electronics" 475 "GME" 474 "Persen Technologies Inc." 473 "Boss Industries, Inc." 472 "Tenneco Inc." 471 "Sea Cross Marine AB" 628 "Falck Schmidt Defence Systems" 627 "Radio Ocean" 626 "AVL DiTEST GmbH" 625 "Global MRV Inc." 624 "Blackbox Machine Control Pty Ltd" 623 "Xirgo Technologies" 622 "Floyd Bell Inc" 621 "Hagie Manufacturing Company" 620 "Sevcon Ltd." 619 "Right Weigh Load Scales" 618 "Evrard SA" 617 "Zero Emission Vehicles" 616 "SMART-TEC s.r.o." 615 "Networkfleet, Verizon Telematics" 614 "ARLT Technologies GmbH" 613 "HKS Co., Ltd." 612 "Samwon IT" 611 "Esterline" 610 "Trail Tech" 609 "Walvoil S.p.A." 608 "Gale Banks Engineering" 607 "Knappco/Civacon" 606 "Intellian Technologies" 605 "Aventics GmbH" 604 "Indexator Rototilt Systems AB" 603 "Kereval" 602 "Nomad Digital Ltd." 601 "Navitas Systems" 600 "Aquatic AV" 599 "Spudnik Equipment Co, LLC" 598 "ABB Turbo Systems Ltd" 597 "Hydac Filter Systems GmbH" 596 "Brunelco Electronic Innovators B.V." 595 "CustomWare" 594 "Kongsberg Automotive" 593 "Sensata Technologies" 592 "tecsis GmbH" 591 "United States Coast Guard" 590 "ARGO-HYTOS GMBH" 589 "MICO, Inc." 588 "Vignal Systems" 587 "JCA Electronics" 586 "Suzuki Motor Corp" 585 "Industrial Electronic Controls" 584 "CarMedialab GmbH" 583 "Yachtcontrol" 582 "Innovative Software Engineering" 581 "Väderstad - Verken AB" 580 "San Jose Technology, Inc." 579 "KVH Industries, Inc." 578 "advanSea" 577 "Denchi Power Ltd  (formerly ABSL Power Solutions Limited)" 576 "Vectia" 575 "Lytx" 574 "Vishay Precision Group" 573 "Orolia Ltd" 572 "Fasse Valves" 571 "Marinecraft Co., Ltd." 570 "frenzel + berg electronic GmbH & Co. KG" 569 "LORD MicroStrain Sensing Systems" 568 "Makersan Ltd. Co." 567 "Lithiumstart LLC" 566 "Geode Technology, Inc." 565 "Micro-Trak Systems, Inc." 564 "Auto Power Electronic" 563 "LOHR Sistemas Eletronicos LTDA" 562 "Bombardier Transportation GmbH" 561 "b-plus GmbH" 560 "Iowa State University, Agricultural and Biosystems Engineering" 559 "Four Peaks Navigation" 558 "Davis Instruments Corp." 557 "Rockson Automation GmbH" 556 "Doosan Infracore Norway" 555 "Sasaki Corporation" 554 "iris-GmbH infrared & intelligent sensors" 553 "KIB Electronics" 552 "Matsuyama Plow Mfg Co, Ltd" 551 "Wexler CSD Ltd." 550 "SUN-A Corporation" 549 "ROAD Deutschland GmbH" 548 "TM4 Inc." 547 "Thomson Linear LLC" 546 "Maruyama Mfg Co, Inc." 545 "GS Hydraulics" 544 "Au Group Electronics" 543 "BAUER Maschinen GmbH" 542 "Dinamica Generale s.p.a." 541 "Total Fire Systems, Inc." 540 "Dinex A/S" 539 "Mobileview" 538 "Crop Ventures, Inc." 537 "Schrader Electronics Ltd." 536 "SSI Technologies" 535 "MOTORPAL, a.s." 534 "Webasto Thermo & Comfort SE" 533 "Doran Manufacturing, LLC" 532 "Onwa Marine Electronics Co Ltd." 531 "Genge & Thoma AG" 530 "NMEA" 529 "National Instruments Korea" 528 "Hoganas AB, Electric Drive Systems" 527 "GKN Walterscheid GmbH" 526 "LOFA Industries, Inc" 525 "Rust Sales INC" 470 "SI-TEX Marine Electronics" 469 "RA Consulting GmbH" 468 "Tyco Fire Protection Products" 467 "Lely Industries N.V." 466 "Veethree Electronics and Marine LLC" 465 "Ashcroft Inc" 464 "Leach International Corporation" 463 "PROBOTIQ" 462 "IHI Shibaura Machinery Corporation" 461 "HAWE Hydraulik SE" 460 "San Giorgio S.E.I.N." 459 "Alltek Marine Electronics Corp" 458 "Control Solutions, Inc." 457 "RUSELPROM-ElectricDrive Ltd" 456 "General Kinetics" 455 "ADZ NAGANO GmbH" 454 "NGK Spark Plug Co. Ltd" 453 "Cooper Bussmann" 452 "WIKA Alexander Wiegand SE & Co. KG" 451 "Parker Hannifin Corp" 450 "Dycor Technologies Ltd." 449 "Polaris Industries Inc" 448 "Stanadyne Corporation, Electronics Systems" 447 "Great Plains Mfg." 446 "CertTech, L.L.C." 445 "KAT MECHATRONIC, Electronic Product Division" 444 "ITT Power Solutions" 443 "SignalQuest, Inc." 442 "Horsch Maschinen GmbH" 441 "PTG Reifendruckregelsysteme GmbH" 440 "Cummins Power Generation" 439 "Hyundai Heavy Industries" 438 "Comar Systems Ltd" 437 "Digital Yacht Limited" 436 "Kinze Manufacturing" 435 "Zunhammer GmbH" 434 "Stored Energy Systems" 433 "Rowe Electronics" 432 "S&A Systems, Inc." 431 "Tohatsu Corporation" 430 "Auteq Telematica S.A." 429 "Rota Engineering Ltd." 425 "Methode Electronics Inc, MDI" 424 "Odyne LLC" 423 "BSM Wireless, Inc." 422 "True Heading AB" 421 "Vertex Standard Co, Ltd" 420 "Vermeer Corporation, ACS Group" 419 "Fusion Electronics Ltd" 418 "Intellistick Inc" 417 "KZValve" 416 "Kubota Corporation" 415 "Valid Manufacturing Ltd." 414 "Cattron Group International" 413 "Datapross Nijbroek bv" 412 "WebTech Wireless Inc." 411 "Hy-Drive Technologies Ltd." 410 "COBO S.p.A. Divisione 3B6" 409 "Transfluid S.r.L." 408 "Corvus Energy Ltd." 407 "Comtech Mobile Datacom" 406 "Vecima Networks Inc." 405 "Wema System AS" 404 "Com Nav Marine Ltd" 403 "Trackwell ADS, Inc." 402 "Simma Software, Inc." 401 "Torqeedo GmbH" 400 "Livorsi Marine" 399 "ISEKI & Co., Ltd." 398 "Hilite International" 397 "Sanyo-kiki Co Ltd." 396 "Beyond Measure" 395 "GENTEC S.R.L." 394 "Capi 2 Nederland B.V." 393 "Harvest Tec, Inc" 392 "Tianyuan Technology Co Ltd." 391 "Electronic Design for Industry, Inc" 390 "Partech Inc." 389 "Benchmark Electronics, Minnesota Division" 388 "Innomatix, LLC" 387 "Orscheln Products, LLC" 386 "JLG Automation BVBA" 385 "Johnson Outdoor Marine Electronics" 384 "Camano Light" 383 "MCL Industries" 382 "National Agriculture and Food Research Organization" 381 "B & G" 380 "Suntech International Ltd." 379 "Yamabiko Corporation" 378 "Glendinning Marine Products" 377 "ifm electronic gmbh" 376 "Quake Global" 375 "Williams Controls Inc." 374 "Northern Lights, Inc." 373 "Electronic Design Inc." 372 "Delphi" 371 "Heinzmann GmbH & Co. KG" 370 "Rolls-Royce Marine AS" 369 "Power Torque Engineering Ltd" 368 "HANSENHOF_electronic" 367 "Fliegl Agrartechnik" 366 "Viewnyx Corp." 365 "Digi-Star, LLC" 364 "OEM Controls Inc." 363 "BEI Duncan" 362 "Poettinger Landtechnik GmbH (formerly Alois Poettinger Maschinenfabrik GmbH)" 361 "InMach" 360 "HJS Emission Technology GmbH & Co KG   (formerly HJS Fahrzeugtechnik GmbH & Co KG)" 359 "Ludwig Bergmann GmbH" 358 "Victron Energy B.V." 357 "Hardi International A/S" 356 "Fischer Panda Generators, Inc" 355 "Mastervolt International B.V." 354 "Junkkari OY" 353 "Hegemon Electronics, Inc." 352 "SAME DEUTZ-FAHR GROUP S.p.A." 351 "Thrane & Thrane" 350 "Noris Marine Systems GmbH & Co KG" 349 "Suonentieto" 348 "Amazonen Werke H. Dreyer" 347 "Honeywell" 346 "Control Solutions" 345 "Korean Maritime University" 344 "Parvus Corporation" 343 "Baumer Group" 342 "THOMAS MAGNETE GmbH" 341 "Boning GmbH & Co" 340 "Continental AG" 339 "Competence Center ISOBUS e.V." 338 "GRAF-SYTECO" 337 "Carraro S.p.A." 336 "APE s.r.o." 335 "Evo Electric Ltd" 334 "Takata-Petri AG" 333 "Hadley Products Corporation" 332 "HWH Corporation" 331 "Horton, Inc." 330 "Kidde Aerospace and Defense" 329 "Deif A/S" 328 "Qwerty Electronik AB" 327 "Sonceboz SA" 326 "Akron Brass Company" 325 "ASM Automation Sensorik Messtechnik GmbH" 324 "Snap-on Diagnostics" 323 "Mobileye Vision Technologies Ltd." 322 "MICHENKA s.r.o." 321 "Ultra Electronics, Electrics" 320 "Miedema Landbouwwerktuigenfabriek B.V." 319 "Cadec Global" 318 "SAT Plan" 317 "Navtronics Bvba" 263 "IMMI" 262 "HydraForce, Inc" 261 "Red Dot Corporation" 260 "Reichhardt GmbH Steuerungstechnik" 259 "Jetter AG" 258 "ARAG" 257 "Honda Motor Co., Ltd" 256 "Tyco Electronics AMP" 255 "MEAS France" 254 "GE Sensing" 253 "Mobile Control Systems" 252 "Sensor-Technik Wiedemann GmbH" 251 "German Agricultural Society, Test Center (DLG)" 250 "Kuhn Group" 249 "Schaltbau GmbH" 248 "Cooper Standard Automotive Active Systems Group" 247 "ePULSE" 246 "Class 1, Inc" 245 "Capstan Ag Systems, Inc." 244 "Techno-Matic" 243 "eRide, Inc." 242 "Kokusandenki Co. Ltd" 241 "Schneider Automation SAS" 240 "Vanair Mfg" 239 "May & Scofield Ltd" 238 "ZF Friedrichshafen AG" 237 "Agtron Enterprises Inc" 236 "NORAC Systems International Inc" 235 "SailorMade Marine Telemetry - Tetra Technology Ltd." 234 "Mondial electronic GmbH" 233 "Yacht Monitoring Solutions Inc." 232 "TSD Integrated Controls" 231 "Topcon Positioning Systems, Inc." 230 "Saucon Technologies" 229 "Garmin International Inc." 228 "Unused (formerly ZF Marine Electronics)" 227 "Lykketronic A/S" 226 "Monaco Coach Corporation" 225 "SKF" 224 "EMMI Network, S.L." 223 "Vaueo Retarder Co., Ltd." 222 "Generac Power Systems, Inc." 221 "SiE" 220 "Beede Electrical Instrument Company, Inc" 219 "Cat OEM Solutions" 218 "Gits Manufacturing Company" 217 "RM Michaelides Software & Elektronik GmbH" 216 "Paneltronics Inc." 215 "Aetna Engineering/Fireboy-Xintex" 214 "MC elettronica Srl" 164 "MTU Friedrichshafen GmbH (formerly DaimlerChrysler Off-Highway)" 163 "BRP Inc." 162 "Axiomatic Technologies" 161 "Offshore Systems (UK) Ltd" 160 "Nido" 159 "NTech Industries Inc" 158 "Firestone Industrial Products Company" 157 "ISSPRO Inc." 156 "ITT Industries - Cannon" 155 "Vetronix Corporation" 154 "Westerbeke Corporation" 153 "Woodward, Industrial Controls Division" 152 "elobau GmbH & Co. KG" 151 "Raven Industries, Inc." 150 "Fleetguard" 149 "Holset" 148 "Blue Water Data, Inc." 147 "Nautibus electronic GmbH" 146 "Maxima Technologies" 145 "MurCal Controls" 144 "Mercury Marine" 143 "W. Gmeiner GmbH & Co." 142 "TRW Automotive (Commercial Steering Systems)" 141 "Thales Navigation Ltd." 140 "Lowrance Electronics, Inc." 139 "Caterpillar Trimble Control Technologies (CTCT), LLC" 138 "Georg Fritzmeier GmbH & Co. KG" 137 "Maretron" 136 "Komatsu Ltd" 135 "Airmar Technology Corporation" 134 "Iris Technology Ltd" 133 "Bucher Schoerling GmbH" 132 "Mulag-Fahrzeugwerk" 131 "ITT Industries" 130 "Nido - Universal Machines B.V." 129 "OMNEX Control Systems Inc." 128 "Gerhard Duecker GmbH & Co. KG" 127 "Holland USA" 126 "Driver Tech" 125 "Nevada Automotive Test Center" 124 "Hydac Electronic" 123 "Basler Electric" 122 "FG Wilson (Engineering) Limited" 121 "HED (Hydro Electronic Devices, Inc.)" 120 "RDS Technology Ltd" 119 "IntegriNautics  " 118 "Intron GmbH" 117 "HUSCO International" 116 "BEELINE Technologies" 115 "NACCO Materials Handling Group, Inc." 114 "EControls, Inc." 113 "Stress-Tek, Inc." 112 "MECALAC" 111 "Bernard Krone Holding SE & Co. KG (formerly Maschinenfabrik Bernard Krone GmbH)" 110 "EPIQ Sensor-Nite" 109 "TeeJet Technologies Denmark (formerly LH Technologies ApS)" 108 "WTK-Elecktronik GmbH" 107 "Grimme Landmaschinen GmbH & Co. KG" 106 "BAE Systems Controls, Inc." 105 "Kiepe Elektrik GmbH & Co. KG" 104 "CLAAS KGaA mbH (formerly CLAAS Selbstfahrende Erntemaschinen GmbH)" 103 "CLAAS E-Systems GmbH (formerly CLAAS E-Systems KGaA mbH & Co. KG)" 102 "AGCO (formerly AGCO GmbH & Co.)" 101 "Sensoria" 100 "VDO Technik AG" 99 "International Transmissions Ltd (ITL)" 98 "Mueller-Elektronik GmbH & Co" 97 "Ag Leader Technology, Inc." 96 "Mech@tronic IT GmbH" 95 "Pacific Insight Electronics Corp." 94 "CNH Industrial N.V. (formerly CNH Global N.V.)" 93 "Perkins Engines Company Ltd." 92 "Ag-Chem Equipment Co., Inc." 91 "BSG Bodensee Steuergeraete GmbH" 90 "Knorr-Bremse SfN GmbH" 89 "Kverneland Group, Electronics Division" 88 "Hemisphere GPS Inc (formerly Satloc Precision GPS)" 87 "J.C. Bamford Excavators Ltd (JCB)" 86 "C. E. Niehoff & Company" 85 "Kohler Co" 84 "New Holland UK Limited" 83 "Bendix VORAD Technologies (formerly Eaton VORAD Technologies)" 82 "Bobcat/Ingersoll-Rand (formerly Melroe/Ingersoll-Rand)" 81 "Fire Research Corp." 80 "Twin Disc, Inc." 79 "Daimler Benz AG - Engine Division (PBM)" 78 "Frank W. Murphy Manufacturing, Inc" 77 "Deere Power Systems Group" 76 "unused (formerly Deere & Co, Construction Division)" 75 "Deere & Co, Agricultural Division" 74 "Eaton Axle-Brake Division" 73 "LeTourneau, Inc." 72 "Sisu Corporation" 71 "Vansco Electronics Ltd." 70 "Flex-coil Limited" 69 "Trimble Navigation" 316 "ITT Flow Control" 315 "Icom Incorporated" 314 "CSM GmbH" 313 "Ilmor Engineering, Inc." 312 "Lectronix, Inc." 311 "Patrick Power Products" 310 "TECNORD srl" 309 "Krauss-Maffei Wegmann GmbH & Co. KG" 308 "Cyntrx" 307 "MAS Technologies" 306 "Sleipner Motor AB" 305 "NovAtel Inc" 304 "EmpirBus AB" 303 "CTS Corporation" 302 "Nissin Kogyo Co., LTD" 301 "Parker Hannifin (UK) Ltd FDE group" 300 "Systron Donner Automotive" 299 "Rauch" 298 "Holley Performance" 297 "Zonar Systems Inc" 296 "micro dynamics GmbH" 295 "BEP Marine" 294 "Grayhill Inc." 293 "Spyder Controls Corp." 292 "IKUSI - Angel Iglesias S.A." 291 "Groeneveld Transport Efficiency BV" 290 "Kuebler GmbH" 289 "Watlow" 288 "Mitsubishi FUSO Truck & Bus Corp." 287 "NTech Industries, Inc" 286 "Coelmo srl" 285 "Sea Recovery Corp" 284 "Mobile Tech Chile" 283 "CWF Hamilton & Co Ltd" 282 "Medallion Instrumentation Systems" 281 "Precision Governors LLC" 280 "Leica Geosystems Pty Ltd" 279 "Geometris LP" 278 "Takata Electronics" 277 "LHP Telematics" 276 "Aqua-Hot Heating Systems" 275 "Navico Egersund AS" 274 "LTW Technology Co., LTD" 273 "Active Research Limited" 272 "Gross Mechanical Laboratories, Inc" 271 "Cole Hersee" 270 "Tennant" 269 "Saft America Inc.,  Space & Defense Division" 268 "Accurate Technologies" 267 "Red Lion Controls, Inc" 266 "International Thermal Research Ltd" 265 "MTS Sensor Technologie GmbH" 264 "Autolync" 213 "CNH Belgium N.V." 212 "Sure Power Industries, Inc" 211 "DNA Group" 210 "Iteris, Inc." 209 "Bell Equip. Co. SA (PTY) LTD" 208 "Drew Technologies, Inc" 207 "Otto Engineering" 206 "port GmbH" 205 "SmarTire Systems Inc" 204 "The Morey Corporation" 203 "MILtronik GmbH" 202 "Curtis Instruments, Inc" 201 "Disenos y Tecnologia S.A." 200 "MGM Brakes" 199 "ACTIA Group (formerly Actia Corp)" 198 "Mystic Valley Communications" 197 "Mechron Power Systems" 196 "LEMKEN GmbH & Co KG" 195 "General Engine Products" 194 "TriMark Corporation" 193 "Jeppesen Marine" 192 "Floscan" 191 "XRS Corporation (formerly XATA Corporation)" 190 "Hella KGaA Hueck & Co" 189 "QUALCOMM" 188 "EMP Corp" 187 "Air-Weigh" 186 "Altronic, Inc" 185 "Beede Electrical Instrument Company" 184 "EIA Electronics" 183 "KDS Controls, Inc" 182 "Vehicle Systems Engineering B.V." 181 "Coretronics, Inc." 180 "Smart Power Systems" 179 "TeeJet Technologies Springfield (formerly Midwest Technologies Illinois, LLC)" 178 "Continental Automotive GmbH (formerly Siemens VDO Automotive AG)" 177 "Diagnostic Systems Associates" 176 "Moritz Aerospace" 175 "Veris Technologies, Inc." 174 "AB Volvo Penta" 173 "Ryeso, Inc." 172 "Yanmar Co., Ltd. (formerly Yanmar Marine USA)" 171 "Topcon Electronics GmbH & Co. KG (formerly Wachendorff Elektronik GmbH & Co. KG)" 170 "Computronics Corporation Ltd." 169 "Marlin Technologies Inc." 168 "Xantrex" 167 "JLG Industries Inc" 166 "John Deere Electronic Solutions (formerly Phoenix International)" 165 "CPAC Systems AB" 68 "Scania" 67 "John Deere Coffeyville Works (formerly Funk Manufacturing Company)" 66 "John Deere Construction Equipment Division" 65 "MAN Nutzfahrzeuge AG" 64 "Unused (formerly SpectraPrecision Laserplane, then SpectraPhysics)" 63 "ZF Industries Inc." 62 "Wabco" 61 "Volvo Truck Corp." 60 "Volvo Trucks North America Inc." 59 "VES Inc." 58 "SPX Corporation, OTC Div" 57 "Danfoss  (formerly Sauer Sundstrand Co, then Sauer-Danfoss Co)" 56 "SAIC" 55 "Ryder System Inc." 54 "Meritor Wabco" 53 "Continental Automotive Systems US, Inc. (formerly Rockwell Land Transportation)" 52 "Meritor Automotive, Inc. (formerly Rockwell Automotive)" 51 "Robert Bosch GmbH" 50 "Robert Bosch Corp" 49 "RE America Inc." 48 "Pollak Alphabet" 47 "Phillips Semiconductor" 46 "Noregon Systems, Inc  (formerly Parasoft Computing Solutions)" 45 "PACCAR" 44 "Nippondenso Co. Ltd." 43 "International Truck and Engine Corporation - Vehicle Electronics (formerly Navistar Intl Trans Corp.)" 42 "International Truck and Engine Corporation - Engine Electronics  (formerly Navistar Intl Trans Co., Engine Electronics)" 41 "Motorola Inc." 40 "Motorola AIEG Inc." 39 "Microfirm Inc." 38 "Micro Processor Systems Inc." 37 "Mack Trucks Inc." 36 "Lucas Ind." 35 "Kenworth Truck Co." 34 "Kelsey Hayes Co." 33 "John Deere" 32 "Jacobs Vehicle Systems" 31 "J Pollak Corp" 30 "Isuzu Motors Ltd" 29 "Hino Motors Ltd." 28 "Grote Ind. Inc." 27 "GMC" 26 "General Motors Corp, Service Technology Grp" 25 "Daimler Trucks North America LLC (formerly Freightliner LLC)" 24 "Ford Motor Co., Vehicle Controls" 23 "Ford Motor Co., Heavy Truck" 22 "Ford Motor Co., Electronic Concepts & Systems" 21 "Echlin Inc., Midland Brake Inc." 20 "Eaton Ltd" 19 "Eaton Corp. Trucking Info Services" 18 "Eaton Corp, Transmission Div." 17 "Eaton Corp, Corp Res & Dev" 16 "Eaton Corp" 15 "DICKEY-john Corporation" 14 "Detroit Diesel Corporation" 13 "Delco Electronics" 12 "Deere & Company, Precision Farming" 11 "Dearborn Group Inc." 10 "Cummins Inc (formerly Cummins Engine Co)" 9 "Chrysler Corp." 8 "Caterpillar Inc." 7 "Case Corp." 6 "Berifors Electronics AB" 5 "AMP Inc." 4 "Ametek-Dixson" 3 "Ametek, US Gauge Division" 2 "Allison Transmission, Inc." 1 "Bendix Commercial Vehicle Systems LLC (formerly Allied Signal Inc.)" 0 "Reserved" ;
VAL_ 2498166526 ErrorCodePoolDeleted 1 "PoolBeingDeleted" 0 "NoErrors" ;
VAL_ 2498166526 Hardware5 1 "SimultaneousActivationsOfSoftkeys" 0 "NoSimultaneousActivationsOfSoftkeys" ;
VAL_ 2498166526 ErrorCodeChangeActiveMask3 1 "GeneralError" 0 "NoErrors" ;
VAL_ 2498166526 ErrorCodeChangeFillAttributes5 1 "GeneralError" 0 "NoErrors" ;
VAL_ 2498166526 ErrorCodeChangeLineAttribute4 1 "GeneralError" 0 "NoErrors" ;
VAL_ 2498166526 ErrorCodeChangeFont5 1 "InvalidStyle" 0 "NoErrors" ;
VAL_ 2498166526 ErrorCodeChangeEditPoint3 1 "GeneralError" 0 "NoErrors" ;
VAL_ 2498166526 ErrorCodeObjToSize2 1 "GeneralError" 0 "NoErrors" ;
VAL_ 2498166526 ErrorCodeEscapeObj2 1 "GeneralError" 0 "NoErrors" ;
VAL_ 2498166526 ErrorCodeAnyOtherError 1 "GeneralError" 0 "NoErrors" ;
VAL_ 2498166526 ErrorCodeVTEsc5 1 "GeneralError" 0 "NoError" ;
VAL_ 2498166526 ErrorCodeChangeNumValue4 1 "ValueInUse" 0 "NoErrors" ;
VAL_ 2498166526 Hardware4 1 "AdjustableVolumeAudio" 0 "NoAdjustableVolumeAudio" ;
VAL_ 2498166526 ErrorCodeChangeFillAttributes4 1 "InvalidPatternObjectID" 0 "NoErrors" ;
VAL_ 2498166526 ErrorCodeChangeFont4 1 "InvalidType" 0 "NoErrors" ;
VAL_ 2498166526 ErrorCodeMaskOrChildObjectError 1 "MaskOrChildObjectHasErrors" 0 "NoErrors" ;
VAL_ 2498166526 ErrorCodeChangeNumValue3 1 "ValueInUse" 0 "NoErrors" ;
VAL_ 2498166526 Hardware3 1 "MultipleFrequencyAudio" 0 "NoMultipleFrequencyAudio" ;
VAL_ 2498166526 ErrorCodeChangePoygonPoint3 0 "NoError" 1 "GeneralError" ;
VAL_ 2498166526 ErrorCodeChangeFillAttributes3 1 "InvalidColour" 0 "NoErrors" ;
VAL_ 2498166526 ErrorCodeChangeLineAttribute3 1 "InvalidWidth" 0 "NoErrors" ;
VAL_ 2498166526 ErrorCodeChangeFont3 1 "InvalidSize" 0 "NoErrors" ;
VAL_ 2498166526 ErrorCodeMissingObjects 1 "MissingObjects" 0 "NoErrors" ;
VAL_ 2498166526 ErrorCodeExecuteExtendedMacro3 0 "NoError" 1 "GeneralError" ;
VAL_ 2498166526 Hardware2 1 "PointingDevice" 0 "NoPointingDevice" ;
VAL_ 2498166526 ErrorCodeSelectColourMap2 0 "NoError" 1 "InvalidColourMapOrPalette" ;
VAL_ 2498166526 ErrorCodeChangePoygonPoint2 0 "NoError" 1 "InvalidPointIndex" ;
VAL_ 2498166526 ErrorCodeChangeActiveMask2 1 "InvalidMaskObjectID" 0 "NoErrors" ;
VAL_ 2498166526 ErrorCodeChangeFillAttributes2 1 "InvalidType" 0 "NoErrors" ;
VAL_ 2498166526 ErrorCodeChangeLineAttribute2 1 "InvalidObjectColour" 0 "NoErrors" ;
VAL_ 2498166526 ErrorCodeChangeFont2 1 "InvalidColour" 0 "NoErrors" ;
VAL_ 2498166526 ErrorCodeChangeEditPoint2 1 "InvalidLineDirection" 0 "NoErrors" ;
VAL_ 2498166526 ErrorCodeChangeNumValue2 1 "InvalidValue" 0 "NoErrors" ;
VAL_ 2498166526 ErrorCodeExecuteExtendedMacro2 0 "NoError" 1 "ObjectIdIsNoMacro" ;
VAL_ 2498166526 Hardware1 1 "TouchScreen" 0 "NoTouchScreen" ;
VAL_ 2498166526 ErrorCodeSelectColourMap1 0 "NoError" 1 "InvalidObjectID" ;
VAL_ 2498166526 SubCommandID 0 "SetGraphicsCursor" 1 "MoveGraphicsCursor" 2 "SetForegroundColour" 3 "SetBackgroundColour" 4 "SetLineAttributesObjectID" 5 "SetFillAttributesObjectID" 6 "SetFontAttributesID" 7 "EraseRectangle" 8 "DrawPoint" 9 "DrawLine" 10 "DrawRectangle" 11 "DrawClosedEllipse" 12 "DrawPolygon" 13 "DrawText" 14 "PanViewport" 15 "ZoomViewport" 16 "PanAndZoomViewport" 17 "ChangeViewportSize" 18 "DrawVTObject" 19 "CopyCanvasToPictureGraphic" 20 "CopyViewportToPictureGraphic" ;
VAL_ 2498166526 ErrorCodeChangePoygonPoint1 0 "NoError" 1 "InvalidObjectId" ;
VAL_ 2498166526 ErrorCodeChangeActiveMask1 1 "InvalidWorkingSetObject" 0 "NoErrors" ;
VAL_ 2498166526 ErrorCodeChangeFillAttributes1 1 "InvalidObjectID" 0 "NoErrors" ;
VAL_ 2498166526 ErrorCodeChangeLineAttribute1 1 "InvalidObjectID" 0 "NoErrors" ;
VAL_ 2498166526 ErrorCodeChangeFont1 1 "InvalidObjectID" 0 "NoErrors" ;
VAL_ 2498166526 ErrorCodeChangeEditPoint1 1 "InvalidObjectID" 0 "NoErrors" ;
VAL_ 2498166526 ErrorCodeChangeNumValue1 1 "InvalidObjectID" 0 "NoErrors" ;
VAL_ 2498166526 ErrorCodeObjToSize1 1 "InvalidObjectID" 0 "NoErrors" ;
VAL_ 2498166526 ObjectSelectStatus 1 "ObjectIsSelected" 0 "ObjectIsDeselectedOrObjectIDIsNullObject" 2 "ObjectIsOpenedForEdit" ;
VAL_ 2498166526 ObjectEnableStatus 1 "ObjectIsEnabled" 0 "ObjectIsDisabled" ;
VAL_ 2498166526 ObjectShowStatus 1 "ObjectIsShown" 0 "ObjectIsHidden" ;
VAL_ 2498166526 ErrorCodeEscapeObj1 1 "NoInputFieldIsOpenForInput" 0 "NoErrors" ;
VAL_ 2498166526 ErrorCodeVTEsc1 1 "NoInputFieldSelected ESC_Ignored" 0 "NoError" ;
VAL_ 2498166526 VTSelectInputObjectStatus 1 "ObjectIsSelected" 0 "ObjectIsDeselected" ;
VAL_ 2498166526 Status_1 0 "Hidden" 1 "Shown" ;
VAL_ 2498166526 ErrorCodeExecuteExtendedMacro1 0 "NoError" 1 "ObjectIdNotExist" ;
VAL_ 2498166526 ErrorCodeLockUnlockMask8 0 "NoError" 1 "GeneralError" ;
VAL_ 2498166526 ErrorCodeLockUnlockMask7 0 "NoError" 1 "UnsolicitedUnlock_OperatorInduce" ;
VAL_ 2498166526 ErrorCodeLockUnlockMask6 0 "NoError" 1 "UnsolicitedUnlock_MaskChanged" ;
VAL_ 2498166526 ErrorCodeLockUnlockMask5 0 "NoError" 1 "UnsolicitedUnlock_TimeoutOccured" ;
VAL_ 2498166526 ErrorCodeLockUnlockMask4 0 "NoError" 1 "AlarmMaskIsActive" ;
VAL_ 2498166526 ErrorCodeExecuteMacro3 0 "NoError" 1 "GeneralError" ;
VAL_ 2498166526 ErrorCodeLockUnlockMask3 0 "NoError" 1 "MaskNotLocked" ;
VAL_ 2498166526 ErrorCodeExecuteMacro2 0 "NoError" 1 "ObjectIdIsNoMacro" ;
VAL_ 2498166526 ErrorCodeLockUnlockMask2 0 "NoError" 1 "MaskAlreadyLocked" ;
VAL_ 2498166526 SupportedGraphicMode 2 "Colour256" 1 "Colour16" 0 "Monocrome" ;
VAL_ 2498166526 MemoryStatus 1 "NotEnoughMemoryAvailable" 0 "EnoughMemoryMayBeAvailable" ;
VAL_ 2498166526 ErrorCodeExecuteMacro1 0 "NoError" 1 "ObjectIdNotExist" ;
VAL_ 2498166526 ErrorCodeLockUnlockMask1 0 "NoError" 1 "MaskNotVisibleOrInvalidObjectId" ;
VAL_ 2498166526 ErrorCodeSetObjectLabel6 0 "NoError" 1 "GeneralError" ;
VAL_ 2498166526 ErrorCodeSetObjectLabel5 0 "NoError" 1 "DesignatorReferencesInvalidObjects" ;
VAL_ 2498166526 ErrorCodeDeleteObjectPool2 1 "GeneralError" 0 "NoErrors" ;
VAL_ 2498166526 ErrorCodeAudioVolume2 1 "CommandNotSupported" 0 "NoErrors" ;
VAL_ 2498166526 ErrorCodeControlAudioDevice2 1 "GeneralError" 0 "NoErrors" ;
VAL_ 2498166526 ErrorCodeEndOfObjectPool3 1 "GeneralError" 0 "NoErrors" ;
VAL_ 2498166526 AuxPreferredAssignmentRespError5 0 "NoErrors" 1 "GeneralError" ;
VAL_ 2498166526 ErrorCodeSetObjectLabel4 0 "NoError" 1 "InvalidDesignatorObjectReference" ;
VAL_ 2498166526 AuxPreferredAssignmentRespError4 0 "NoErrors" 1 "DuplicateObjectIdOfAuxFct" ;
VAL_ 2498166526 ErrorCodeSetObjectLabel3 0 "NoError" 1 "InvalidFontType" ;
VAL_ 2498166526 AuxPreferredAssignmentRespError3 0 "NoErrors" 1 "InputObjectID(s)NotValid" ;
VAL_ 2498166526 ErrorCodeSetObjectLabel2 0 "NoError" 1 "InvalidStringVariableObjectId" ;
VAL_ 2498166526 AuxPreferredAssignmentRespError2 0 "NoErrors" 1 "FunctionObjectID(s)NotValid" ;
VAL_ 2498166526 ErrorCodeEndOfObjectPool2 1 "VTRanOutOfMemoryDuringTransfer" 0 "NoErrors" ;
VAL_ 2498166526 VersionNumberISO11783Part6 6 "FourthEdition_2017" 5 "ThirdEdition_2014" 4 "SecondEdition_2010" 3 "SecondEdition_2010" 2 "FirstEdition_2002" 1 "FDIS_Version" 0 "Hannover Agritechnica 2001 limit" ;
VAL_ 2498166526 LockUnlockCommand 0 "UnlockMask" 1 "LockMask" ;
VAL_ 2498166526 ErrorCodeSetObjectLabel1 0 "NoError" 1 "InvalidObjectId" ;
VAL_ 2498166526 ErrorCodeDeleteObjectPool1 1 "DeletionError" 0 "NoErrors" ;
VAL_ 2498166526 ErrorCodeAudioVolume1 1 "AudioDeviceIsBusy" 0 "NoErrors" ;
VAL_ 2498166526 ErrorCodeControlAudioDevice1 1 "AudioDeviceIsBusy" 0 "NoErrors" ;
VAL_ 2498166526 AuxPreferredAssignmentRespError1 0 "NoErrors" 1 "AuxiliaryInputUnit(s)NotValid" ;
VAL_ 2498166526 ErrorCodeEndOfObjectPool1 0 "NoErrors" 1 "ErrorsInTheObjectPool" ;
VAL_ 2498166526 ButtonActivationCode 2 "ButtonIsStillHeld" 1 "ButtonHasBeenLatched" 0 "ButtonHasBeenUnlatched" 3 "ButtonPressAborted" ;
VAL_ 2498166526 KeyActivationCode 2 "KeyIsStillPressed" 1 "KeyHasBeenPressed" 0 "KeyHasBeenReleased" 3 "KeyPressAborted" ;
VAL_ 2498166526 TerminationCause 1 "AudioWasTerminated" ;
VAL_ 2498166526 BootTime 255 "Information not available" ;
VAL_ 2498166526 VTFunctionVTtoECU 200 "GetFontVersionResponse" 198 "ScreenCaptureResponse" 144 "ShowWorkingSetResponse" 253 "VTUnsupportedVTFunction" 34 "AuxiliaryPreferredAssignmentResponse" 180 "ChangeChildPositionResponse" 179 "ChangeStringValueResponse" 240 "VTObjectPoolErrorMessage" 196 "GetWindowMaskDataResponse" 8 "VTChangeStringValue" 7 "VTChangeSoftKeyMask" 6 "VTChangeActiveMask" 5 "VTChangeNumericValue" 4 "VTESC" 3 "VTSelectInputObject" 33 "AuxiliaryInputStatus" 254 "VTStatusMessage" 224 "GetVersionsResponse" 210 "DeleteVersionResponse" 209 "LoadVersionResponse" 208 "StoreVersionResponse" 199 "GetHardwareResponse" 195 "GetTextFontDataResponse" 194 "GetNumberOfSoftKeysResponse" 192 "GetMemoryResponse" 178 "DeleteObjectPoolResponse" 177 "ChangeListItemResponse" 176 "ChangePriorityResponse" 175 "ChangeAttributeResponse" 174 "ChangeSoftKeyMaskResponse" 173 "ChangeActiveMaskResponse" 172 "ChangeFillAttributesResponse" 171 "ChangeLineAttributesResponse" 170 "ChangeFontAttributesResponse" 169 "ChangeEndPointResponse" 168 "ChangeNumericValueResponse" 167 "ChangeBackgroundColourResponse" 166 "ChangeSizeResponse" 165 "ChangeChildLocationResponse" 164 "SetAudioVolumeResponse" 163 "ControlAudioDeviceResponse" 162 "SelectInputObjectResponse" 161 "EnableDisableObjectResponse" 160 "ShowHideObjectResponse" 146 "ESCResponse" 32 "AuxiliaryAssignmentCommand" 18 "EndOfObjectPoolResponse" 2 "PointingEvent" 1 "ButtonActivation" 0 "SoftKeyActivation" 181 "ChangeObjectLabelResponse" 182 "ChangePolygonPointResponse" 183 "ChangePolygonScaleResponse" 184 "GraphicsContextCommandResponse" 185 "GetAttributeValueResponse" 186 "SelectColourMapResponse" 9 "VTOnUserLayoutHideShow" 10 "VTControlAudioDeviceTermination" 35 "AuxiliaryInputMaintenance" 189 "LockUnlockMaskResponse" 190 "ExecuteMacroResponse" 37 "AuxiliaryInputStatusEnableCommand" 193 "GetSupportedWideCharsResponse" 36 "AuxiliaryAssignmentCommandType2" 38 "AuxiliaryInputStatusType2" 187 "IdentifyVTResponse" 197 "GetSupportedObjectsResponse" 188 "ExecuteExtendedMacroResponse" 211 "ExtendedGetVersionsResponse" 212 "ExtendedStoreVersionResponse" 213 "ExtendedLoadVersionResponse" 214 "ExtendedDeleteVersionResponse" 39 "AuxiliaryCapabilitiesResponse" ;
VAL_ 2565799678 IndustryGroup 7 "Reserved for SAE" 5 "IndustrialProcessCtrlStationary" 4 "Marine" 3 "Construction" 2 "AgriculturalAndForestry" 1 "On-Highway" 0 "Global" ;
VAL_ 2565799678 VehicleSystem 127 "Not Available" 0 "NonSpecificSystem" ;
VAL_ 2565799678 VehicleSystem5 0 "Ind. Process Control Stationary" 127 "Not Available" ;
VAL_ 2565799678 VehicleSystem4 0 "NonSpecificSystem" 127 "Not Available" 10 "System Tools" 20 "Safety Systems" 25 "Inter/Intranetwork Device" 30 "Electrical Distribution" 40 "Steering and Control Surfaces" 50 "Propulsion" 60 "Navigation" 70 "Communications" 80 "Instrumentation/General Systems (deprecate)" 90 "Internal Environment" 100 "Deck, Cargo and Fishing Equipment" 35 "Electrical Generation" 75 "Sensor Communication Interface" 85 "External Environment" 120 "Display" 125 "Entertainment" ;
VAL_ 2565799678 VehicleSystem3 0 "NonSpecificSystem" 127 "Not Available" 1 "Skid Steer Loader" 2 "Articulated Dump Truck" 3 "Backhoe" 4 "Crawler" 5 "Excavator" 6 "Forklift" 7 "Four Wheel Drive Loader" 8 "Grader" ;
VAL_ 2565799678 VehicleSystem2 0 "NonSpecificSystem" 127 "Not Available" 1 "Tractor" 2 "Tillage" 3 "Secondary Tillage" 4 "Planters/Seeders" 5 "Fertilizers" 6 "Sprayers" 7 "Harvesters" 8 "Root Harvesters" 9 "Forage" 10 "Irrigation" 11 "Transport/Trailer" 12 "Farm Yard Operations" 13 "Powered Auxiliary Device" 14 "Special Crops" 15 "Earth Work" 16 "Skidder" 17 "Sensor Systems" 19 "Timber Harvesters" 20 "Forwarders" 21 "Timber loaders" 22 "Timber Processing Machines" 23 "Mulchers" 24 "Utility Vehicles" 25 "Slurry Applicators" ;
VAL_ 2565799678 VehicleSystem1 0 "NonSpecificSystem" 127 "Not Available" 1 "Tractor" 2 "Trailer" ;
VAL_ 2565799678 Function 142 "TIMServer" 43 "Transmission Display" 44 "Exhaust Emission Control" 45 "Vehicle Dynamic Stability Control" 46 "Oil Sensor Unit" 47 "Information System Controller" 48 "Ramp Control" 49 "Clutch/Converter Control" 50 "Auxiliary Heater" 51 "Forward-Looking Collision Warning System" 52 "Chassis Controller" 53 "Alternator/Charging System" 54 "Communications Unit, Cellular" 55 "Communications Unit, Satellite" 56 "Communications Unit, Radio" 57 "Steering Column Unit" 58 "Fan Drive Control" 59 "Starter" 60 "Cab Display" 61 "File Server/Printer" 62 "On-Board Diagnostic Unit" 63 "Engine Valve Controller" 64 "Endurance Braking" 65 "Gas Flow Measurement" 66 "I/O Controller" 67 "Electrical System Controller" 68 "Aftertreatment system gas measurement" 69 "Engine Emission Aftertreatement System" 70 "Auxiliary Regeneration Device" 71 "Transfer Case Control" 72 "Coolant Valve Controller" 73 "Rollover Detection Control" 74 "Lubrication System" 75 "Supplemental Fan" 76 "Temperature Sensor" 77 "Fuel Properties Sensor" 78 "Fire Suppression System" 79 "Power Systems Manager" 80 "Electric Powertrain" 81 "Hydraulic Powertrain" 82 "File Server" 83 "Printer" 84 "Start Aid Device" 85 "Engine Injection Control Module" 86 "Reserved" 87 "Reserved" 88 "Reserved" 89 "Reserved" 90 "Reserved" 91 "Reserved" 92 "Reserved" 93 "Reserved" 94 "Reserved" 95 "Reserved" 96 "Reserved" 97 "Reserved" 98 "Reserved" 99 "Reserved" 100 "Reserved" 0 "Engine" 1 "Auxiliary Power Unit (APU)" 2 "Electric Propulsion Control" 3 "Transmission" 4 "Battery Pack Monitor" 5 "Shift Control/Console" 6 "Power TakeOff - (Main or Rear)" 7 "Axle - Steering" 8 "Axle - Drive" 9 "Brakes - System Controller" 10 "Brakes - Steer Axle" 11 "Brakes - Drive Axle" 12 "Retarder - Engine" 13 "Retarder - Driveline" 14 "Cruise Control" 15 "Fuel System" 16 "Steering Controller" 17 "Suspension - Steer Axle" 18 "Suspension - Drive Axle" 19 "Instrument Cluster" 20 "Trip Recorder" 21 "Cab Climate Control" 22 "Aerodynamic Control" 23 "Vehicle Navigation" 24 "Vehicle Security" 25 "Network Interconnect ECU" 26 "Body Controller" 27 "Power TakeOff (Secondary or Front)" 28 "Off Vehicle Gateway" 29 "Virtual Terminal (in cab)" 30 "Management Computer" 31 "Propulsion Battery Charger" 32 "Headway Controller" 33 "System Monitor" 34 "Hydraulic Pump Controller" 35 "Suspension - System Controller" 36 "Pneumatic - System Controller" 37 "Cab Controller" 38 "Tire Pressure Control" 39 "Ignition Control Module" 40 "Seat Control" 41 "Lighting - Operator Controls" 42 "Water Pump Control" 101 "Reserved" 102 "Reserved" 103 "Reserved" 104 "Reserved" 105 "Reserved" 106 "Reserved" 107 "Reserved" 108 "Reserved" 109 "Reserved" 110 "Reserved" 111 "Reserved" 112 "Reserved" 113 "Reserved" 114 "Reserved" 115 "Reserved" 116 "Reserved" 117 "Reserved" 118 "Reserved" 119 "Reserved" 120 "Reserved" 121 "Reserved" 122 "Reserved" 123 "Reserved" 124 "Reserved" 125 "Reserved" 126 "Reserved" 127 "Reserved" 255 "Not Available" ;
VAL_ 2565799678 ManufacturerCode 1077 "Ymer Technology" 1076 "DOGA S.A." 1075 "Uniden America Corporation" 1074 "Kindhelm / Navigs Oy" 1073 "Manitou Equipment America LLC" 1072 "La Marche Manufacturing Company" 1071 "MACH SYSTEMS s.r.o." 1070 "Quick-teck Electronics Ltd" 1069 "Lithionics Battery LLC" 1068 "Zapi S.p.A." 1067 "Tecomec S.r.l." 1066 "Spot Zero Water" 1065 "CALYPSO Instruments" 1064 "Omnitech Robotics Inc." 1063 "SolSteer" 1062 "Marol Co Ltd" 1061 "Volvo Construction Equipment" 1060 "Scale-Tec" 1059 "Boatrax" 1058 "Bondioli & Pavesi SpA" 1057 "EquipmentShare" 1056 "Lithium Pros" 1055 "EXA Computing GmbH" 1054 "Schmotzer Hacktechnik GmbH & Co. KG" 1053 "Vetus Maxwell, Inc." 1052 "Pfreundt" 1051 "ProNav AS" 1050 "Spacenus GmbH" 1049 "S&S Cycle" 1048 "Agrivation UG" 1047 "Sonic Corporation" 1046 "Praxidyn" 1045 "CMR Group" 1044 "Xee" 1043 "Hyva" 1042 "engcon group" 1041 "EZ Lynk" 1040 "BPE Electronics Srl" 1039 "Liugong Dressta Machinery" 1038 "EMIT Technologies, Inc." 1037 "Dragonfly Energy Corp." 1036 "Bender GmbH & Co. KG" 1035 "Agres" 1034 "Siren Marine" 1033 "ECCO Safety Group" 1032 "SIMOL S.p.A." 1031 "Flintec UK Ltd." 1030 "Tume-Agri Oy" 1029 "The Marine Guardian LLC" 1028 "Autel Intelligent Technology Corp., Ltd" 1027 "Goldacres PTY LTD" 1026 "ZTR Control Systems, LLC" 1025 "eze System, Inc." 1024 "Inventus Power" 1023 "PEAK-System Technik GmbH" 1022 "ITC Inc" 1021 "Entratech Systems LLC" 1020 "Onyx Marine Automation s.r.l." 1019 "Codek Foundries" 1018 "Flex TTS" 1017 "Caldaro AB" 1016 "Röhren- und Pumpenwerk BAUER GmbH" 1015 "SECURITAG SAS" 1014 "Briri Maschinenbau GmbH" 1013 "Allochis E-Tec" 1012 "Rhodan Marine Systems of Florida LLC" 1011 "Soundmax Electronics Ltd" 1010 "Agricultural Industry Electronics Foundation e.V." 1009 "TouchTronics, Inc." 1008 "Lintest Systems LLC" 1007 "Maschinenfabrik Meyer-Lohne GmbH" 1006 "Proterra" 1005 "TSE Brakes, Inc." 1004 "Ultraflex SpA" 1003 "technotrans SE" 1002 "Kussmaul Electronics Co." 1001 "Cleral Inc." 1000 "Landmaschinen Wienhoff GmbH" 1569 "621 Technologies Inc." 999 "TerraTroniq B.V." 998 "Transcell Technology Inc" 997 "Xenta Systems Srl" 996 "Eniquest Pty Ltd" 995 "Circuitlink Pty Ltd." 994 "Morris Industries Ltd." 993 "Alelion Energy Systems AB" 992 "MarineIOT LLC" 991 "Deutronic Elektronik GmbH" 990 "SAMSUNG SDI Co., Ltd." 989 "Flux-Geräte GmbH" 988 "Voith Turbo" 987 "Baltic Car Equipment" 986 "AAMP Global" 985 "NLR, LLC" 984 "E-T-A Elektrotechnische Apparate GmbH" 983 "Dezwaef NV" 982 "Briggs & Stratton Corporation" 981 "Kobelt Manufacturing Co. Ltd" 980 "Gussi Italia S.R.L." 979 "McHale" 978 "Canfield Connector" 977 "Emerson Electric Co." 976 "Derive Systems, Inc." 975 "Siemens AG" 974 "Pico Technology Limited" 973 "Zasso GmbH" 972 "Axion AG" 971 "B+B Smartworx" 970 "Jaboni Power Products, LLC" 969 "Blue Sea Systems" 968 "Cox Powertrain Limited" 967 "Moteck Electric Corp." 966 "VisibleFarm" 965 "Ro-Sys Software" 964 "AgroVIR Kft" 963 "Thomason Jones Company, LLC" 962 "Timbolier Industries, Inc." 961 "POK SAS" 960 "Vemcon GmbH" 959 "Cascade Corporation" 958 "NHK MEC Corporation" 957 "Sierra Wireless Inc" 956 "Piher Sensors & Controls S.A." 955 "Hottinger Baldwin (Suzhou) Electronic Measurement Technology Co., Ltd." 954 "Setec Pty Ltd" 953 "Curtiss-Wright" 952 "Tan Delta Systems Ltd" 951 "Exor International S.p.A." 950 "RE:Lab s.r.l." 949 "Škoda Electric a.s." 948 "Donix" 947 "Gerd Bär GmbH" 946 "Hydac Tecnologia Ltda" 945 "Equalizer AG" 944 "ZONTISA Marine SL" 943 "FISCHER AG Präzisionspindeln" 942 "Vogelsang GmbH & Co. KG" 941 "Navya" 940 "Dometal Oy" 939 "Warn Industries, Inc." 938 "LEVEL Systems" 937 "Precision Circuits Inc" 936 "Hi-tech Millennium" 935 "Meels GmbH & Co. KG" 934 "Farmobile, Inc." 933 "Delta Mobile Systems, Inc." 932 "Discover Battery" 931 "Enertec Marine Ltd" 930 "Ecotronix Corp." 929 "Jl Marine Systems, Inc." 928 "EAO Automotive GmbH & Co. KG" 927 "Saicon" 926 "Buhler Industries Inc." 925 "GW Lisk Company" 924 "PAS Peschak Autonome Systeme GmbH" 923 "ELTEK S.p.A." 922 "Terberg Benschop B.V." 921 "ROPA Fahrzeug- und Maschinenbau GmbH" 920 "MTD Consumer Group Inc." 919 "Furrion LLC" 918 "AMW Machine Control, Inc" 917 "Sentinel d.o.o." 916 "Turck Inc." 915 "Dosificacion y sistemas electronicos S.L. (DSE)" 914 "ZETOR TRACTORS a.s." 913 "Toyota Motor Corporation" 912 "Steyr Motors GmbH" 911 "Nautic-On" 910 "Hermann Paus Maschinenfabrik GmbH" 909 "Marines Co., Ltd." 908 "Chonbuk National University Department of Electronics" 907 "strautmann" 906 "MOBA AG" 905 "ASA Electronics" 904 "Equipment Safety Systems Pty. Ltd. (EQSS)" 903 "InMotion" 902 "Bucher Hydraulics" 901 "Zivan Srl" 900 "OSB AG" 899 "Lippert Components, Inc" 898 "Josef Kotte Landtechnik GmbH & Co. KG" 897 "Dot Technology Corp." 896 "NextFour Solutions Ltd" 895 "Peloton Technology" 894 "Rhodan Marine Systems of Florida LLC" 893 "KlinkTechnics Ltd." 892 "Mectronx Corp" 891 "CarrierWeb" 890 "L3 Technologies, Inc." 889 "SANY America Inc" 888 "Carma Systems Inc" 887 "Hyperdrive Innovation Limited" 886 "Hitachi Zosen Corporation" 885 "SICK Stegmann GmbH" 884 "Sure Grip Controls Inc." 883 "Swift Navigation, Inc." 882 "BHTronik GmbH & Co. KG" 881 "Sovema" 880 "Revision Military" 879 "PG Trionic, Inc." 878 "FOTON" 877 "SICK ATech GmbH" 876 "SUCO Robert Scheuffele GmbH & Co. KG" 875 "Salvarani S.r.l." 874 "MTA S.p.A." 873 "Garnet Instruments Ltd." 872 "Kählig Antriebstechnik GmbH" 871 "Superior Tech Inc" 870 "Textron Fleet Management" 869 "Intercomp" 868 "Data Panel Corp" 867 "Skeleton Technologies" 866 "Netradyne, Inc." 865 "MyEasyFarm" 864 "Streamline Transportation Technologies Inc." 863 "SMAG" 862 "Prospec Electronics" 861 "Adel System S.r.l." 860 "Michelin" 859 "Valor" 858 "Littelfuse" 857 "Zoomlion Heavy Industry NA, Inc" 856 "FarmFacts GmbH" 855 "Toshiba Infrastructure Systems & Solutions Corporation" 854 "GEMAC Chemnitz GmbH" 853 "Teledyne RESON B.V." 852 "Velvac Inc" 851 "Novotechnik Messwertaufnehmer OHG" 850 "Geoprospectors GmbH" 849 "MTS Maschinentechnik Schrode AG" 848 "ningupex" 847 "Oceanvolt" 846 "L3 Magnet-Motor" 845 "GMB Güstrower Maschinenbau GmbH" 844 "FELL AS" 843 "Hendrickson Truck Commercial Vehicle Systems" 842 "DigiDevice Srl" 841 "Agra-GPS" 840 "E.S.T.E. Srl" 839 "Indexator Rotator Systems AB" 838 "Teamsurv Ltd" 837 "Famic Technologies Inc." 836 "Signature4" 835 "PetTrack Ltd." 834 "Pioneer Microsystems, Inc." 833 "Electrum Automation AB" 832 "Heizomat Gerätebau-Energiesysteme GmbH" 831 "DOK-ING Ltd." 830 "Ultra Motion LLC" 829 "Drov Technologies, Inc." 828 "AgriBrink Inc." 827 "INmatix Technology Group Ltd" 826 "Lewmar Marine Inc" 825 "BPW Hungária" 824 "Undheim Systems AS" 823 "ACEINNA, Inc (formerly MEMSIC, Inc)" 822 "Bren-Tronics, Inc." 821 "Thorsen Teknik A/S" 820 "DIaLOGIKa Gesellschaft fuer angewandte Informatik mbH" 819 "Preco Electronics" 818 "HGNSS" 817 "TE Connectivity Sensor Solutions" 816 "UniStrong" 815 "FLIR Systems, Inc." 814 "Kronotech Srl (formerly Soltec Soluzioni Tecnologiche Srl)" 813 "Thales Suisse SA" 812 "Torch Technologies" 811 "Blue Water Desalination" 810 "Dutch Power Company" 809 "HMS Industrial Networks AB" 808 "RIMEX Supply Ltd." 807 "Schneider-Electric" 806 "Charge Automotive Ltd" 805 "Gundersen & Løken AS" 804 "ASA Electronics" 803 "Gill Sensors & Controls Limited" 802 "SPBI (Bj Technologie)" 801 "LOR Manufacturing Company Inc." 800 "Delta-Q Technologies" 799 "Stillwater Designs and Audio, Inc. - KICKER" 798 "Lumishore Ltd" 797 "Tides Marine" 796 "Canadian Automotive Industries Ltd" 795 "Broyda Enterprises Pty Ltd" 794 "Shihlin Electric & Engineering Corporation" 793 "James Fisher Prolec" 792 "Kostal Mexicana" 791 "AUTEC" 790 "VACALL" 789 "GRADALL" 788 "MoTeC Pty Ltd" 787 "Abertax Technologies Limited" 1863 "Thomas G. Faria Co." 1862 "Sanshin" 1861 "Vector North America" 1860 "MMP" 1859 "Kvasar AB" 1858 "Litton" 1857 "Simrad" 1856 "Trimble" 1855 "Furuno USA" 1854 "Northstar Technologies" 1853 "Japan Radio Co" 1852 "Navionics" 1851 "RayMarine" 1850 "Seastar Solutions (formerly Teleflex)" 786 "Johnson Matthey Battery Systems" 785 "Fischer Panda GmbH" 784 "CM Automotive Systems, Inc." 783 "Loup Electronics Inc." 782 "AVR bv (formerly AVR bvba)" 781 "Poly-Planar LLC" 780 "AVID Technology Ltd" 779 "RLC Electronic Systems" 778 "Seakeeper Inc." 777 "Ocean Signal Ltd" 776 "HMI Systems LLC" 775 "ZIEHL-ABEGG Automotive GmbH" 774 "Taisho Corporation" 773 "Clarion Corporation of America" 772 "Blink Marine" 771 "Shaw Development, LLC" 770 "MONOSEM" 769 "Trombetta" 768 "Flores Automation, LLC" 767 "Alliance Wireless Technologies Inc." 766 "Epec Oy" 765 "GIGAVAC" 764 "Bednar FMT s.r.o." 763 "AT-Systems BVBA" 762 "ROJ s.r.l." 761 "MITA OLEODINAMICA S.p.A." 760 "Bernecker + Rainer Industrie Elektronik GmbH" 759 "Hydro-Gear" 758 "Banner Engineering Corp." 757 "IMPCO Technologies" 756 "Maschio Gaspardo S.P.A." 755 "Firefly Integrations" 754 "Parker Hannifin Corp., Automation Group" 753 "AIROD Technologies" 752 "Deep Sea Electronics Plc" 751 "Pacific Track" 750 "Joskin SA" 749 "Chart Inc." 748 "ISOTTA" 747 "Agratronix" 746 "SureFire Ag Systems, Inc." 745 "Cidra Corporate Services Inc." 744 "Woosung Engineering Co., Ltd." 743 "Daemyung Elevator Co., Ltd." 742 "EROAD" 741 "Carling Technologies" 740 "e-Traction" 739 "LXNAV d.o.o." 738 "Blue Ink Technologies" 737 "Balluff GmbH" 736 "Terex Aerial Work Platforms - Genie" 735 "AEM Performance Electronics" 734 "REAPsystems" 733 "Intendia S.L." 732 "Gefran S.p.A." 731 "Modine Manufacturing Company" 730 "BERTHOUD AGRICOLE" 729 "Liebherr" 728 "Streumaster (formerly Streumaster / Panien)" 727 "Dhoot Transmission Pvt Ltd." 726 "MIDORI PRECISIONS" 725 "Hitachi Construction Machinery Co., Ltd." 724 "Electronic Applications, Inc." 723 "Jabil Inc." 722 "Contelec AG" 721 "Hypro" 720 "WITZ Corporation" 719 "Cojali S. L." 718 "Micronet Inc" 717 "Yacht Devices Ltd" 716 "Eaton Control & Power Conversion Division (CPCD)" 715 "Autonnic Research Ltd" 714 "Kobashi Kogyo Co., Ltd." 713 "US Hybrid Corporation" 712 "LOR Manufacturing Company Inc." 711 "DAS Co., LTD" 710 "Greentronics Ltd." 709 "Marquardt GmbH" 708 "Lars Thrane A/S" 707 "Rochester Gauges Inc" 706 "Shanghai Diesel Engine Corporation Limited" 705 "SVAB Hydraulik AB" 704 "JL Audio, Inc." 703 "Hydro Tab Marine Engineering" 702 "Weichai Power Co., Ltd." 701 "BigRoad Inc." 700 "K-Tec Earthmovers Inc." 699 "Harman International Industries" 698 "Scorpion Technologies Ltd." 697 "Ålö AB" 696 "DRS Network & Imaging Systems, LLC (DRS Technologies)" 695 "Weldon Technologies" 694 "GasTOPS Ltd." 693 "Agility Fuel Solutions (formerly Agility Fuel Systems)" 692 "Tanhay Corporation" 691 "Digitroll Agricultural Electronics" 690 "LINAK A/S" 689 "Aarcomm Systems Inc" 688 "Rockford Corp" 687 "Flight Systems, Inc." 686 "Taigene Electric Machinery Corp." 685 "ANEDO (formerly ANEDO Ltd.)" 684 "KEB" 683 "Fosen Elektro" 682 "Eckelmann AG" 681 "BEDIA Motorentechnik GmbH & Co. KG" 680 "AMVAC Chemical Corporation" 679 "Cimco Marine AB" 678 "KeepTruckin, Inc." 677 "DSA Daten- und Systemtechnik GmbH" 676 "Danfoss IXA A/S" 675 "Kawasaki Motors Corp., USA" 674 "Yara International ASA" 673 "Caruelle Nicolas" 672 "OPTIMA Concept" 671 "Innovative Controls Inc." 670 "STEMCO LP" 669 "Quantum Fuel Systems Technologies Worldwide, Inc" 668 "MacDon Industries Ltd." 667 "Bartec" 666 "Schaeffler Technologies AG & Co., KG" 665 "Gebr. Bode GmbH & Co. KG" 664 "Level Developments Ltd" 663 "Delta Systems, Inc" 662 "Kissling Elektrotechnik GmbH" 661 "SPAL Automotive S.r.l." 660 "Auto-Gaz Centrum" 659 "Data Panel Corp." 658 "Shenzhen Jiuzhou Himunication Technology Co., Ltd" 657 "Terzo Power Systems" 656 "PRO SOLUS do Brasil" 655 "Genge & Thoma AG" 654 "Kohler Power Systems, Detroit Engine Development Center (DEDC)" 653 "AEV, spol. s r. o." 652 "MicroControl GmbH & Co. KG" 651 "Takakita Co, Ltd." 650 "Seiko Epson Corp." 649 "Control-Q B.V." 648 "OJSC Ekran" 647 "Siloking" 646 "Veenhuis Machines B.V." 645 "esd electronic system design gmbh" 644 "KUS USA" 643 "Bogballe A/S" 642 "Moog / Aspen Motion Technologies" 641 "Diverse Yacht Services" 640 "Power Solutions International" 639 "Startec s.r.l." 638 "KVH Industries, Inc." 637 "Bavaria Yachtbau GmbH" 636 "Divelbiss Corporation" 635 "Argo Tractors S.p.A." 634 "Rocky Research" 633 "TORC Robotics" 632 "Pepperl+Fuchs GmbH" 631 "Reltima" 630 "SmartDrive Systems Inc." 629 "Agri Info Design, Ltd." 524 "Vomax Instrumentation Pty. Ltd." 523 "Reggio Emilia Innovazione" 522 "Nebraska Tractor Test Laboratory" 521 "Clever Devices Ltd." 520 "Trapeze" 519 "Peeters Landbouwmachines b.v." 518 "Transas USA Inc." 517 "Noland Engineering" 516 "AVAT Automation GmbH" 515 "GINAF Trucks Nederland B.V." 514 "DISTek Integration, Inc." 513 "Precision Technology (Formerly FarmscanAg)" 512 "Inpower LLC" 511 "Sulky" 510 "Marinesoft Co. Ltd" 509 "MOTORTECH GmbH" 508 "Transtech Innovations" 507 "ISOBUS Test Center" 506 "IHI STAR Machinery Corporation" 505 "Yetter Farm Equipment" 504 "Vesper Marine" 503 "Naviop S.R.L." 502 "Attwood Corporation" 501 "Agrotronix S.A." 500 "Oxbo International Corporation" 499 "LCJ Capteurs" 498 "Innovative Design Solutions, Inc." 497 "SENTRON Sistemas Embarcados" 496 "W. Gessmann GmbH" 495 "HOLMER Maschinenbau GmbH" 494 "Synerject" 493 "Watcheye" 492 "Inergy Automotive Systems" 491 "Penny and Giles Ltd" 490 "QuikQ" 489 "Appareo Systems, LLC" 488 "The Charles Machine Works, Inc." 487 "DSE Test Solutions A/S" 486 "Westport Innovations Inc." 485 "MATT automotive" 484 "Headsight Inc." 483 "Valeo" 482 "Tricon Electronics" 481 "Chetco Digital Instruments" 480 "EnerDel, Inc." 479 "Vapor Bus International" 478 "OceanSat B.V." 477 "OilQuick AB" 476 "Hummingbird Marine Electronics" 475 "GME" 474 "Persen Technologies Inc." 473 "Boss Industries, Inc." 472 "Tenneco Inc." 471 "Sea Cross Marine AB" 628 "Falck Schmidt Defence Systems" 627 "Radio Ocean" 626 "AVL DiTEST GmbH" 625 "Global MRV Inc." 624 "Blackbox Machine Control Pty Ltd" 623 "Xirgo Technologies" 622 "Floyd Bell Inc" 621 "Hagie Manufacturing Company" 620 "Sevcon Ltd." 619 "Right Weigh Load Scales" 618 "Evrard SA" 617 "Zero Emission Vehicles" 616 "SMART-TEC s.r.o." 615 "Networkfleet, Verizon Telematics" 614 "ARLT Technologies GmbH" 613 "HKS Co., Ltd." 612 "Samwon IT" 611 "Esterline" 610 "Trail Tech" 609 "Walvoil S.p.A." 608 "Gale Banks Engineering" 607 "Knappco/Civacon" 606 "Intellian Technologies" 605 "Aventics GmbH" 604 "Indexator Rototilt Systems AB" 603 "Kereval" 602 "Nomad Digital Ltd." 601 "Navitas Systems" 600 "Aquatic AV" 599 "Spudnik Equipment Co, LLC" 598 "ABB Turbo Systems Ltd" 597 "Hydac Filter Systems GmbH" 596 "Brunelco Electronic Innovators B.V." 595 "CustomWare" 594 "Kongsberg Automotive" 593 "Sensata Technologies" 592 "tecsis GmbH" 591 "United States Coast Guard" 590 "ARGO-HYTOS GMBH" 589 "MICO, Inc." 588 "Vignal Systems" 587 "JCA Electronics" 586 "Suzuki Motor Corp" 585 "Industrial Electronic Controls" 584 "CarMedialab GmbH" 583 "Yachtcontrol" 582 "Innovative Software Engineering" 581 "Väderstad - Verken AB" 580 "San Jose Technology, Inc." 579 "KVH Industries, Inc." 578 "advanSea" 577 "Denchi Power Ltd  (formerly ABSL Power Solutions Limited)" 576 "Vectia" 575 "Lytx" 574 "Vishay Precision Group" 573 "Orolia Ltd" 572 "Fasse Valves" 571 "Marinecraft Co., Ltd." 570 "frenzel + berg electronic GmbH & Co. KG" 569 "LORD MicroStrain Sensing Systems" 568 "Makersan Ltd. Co." 567 "Lithiumstart LLC" 566 "Geode Technology, Inc." 565 "Micro-Trak Systems, Inc." 564 "Auto Power Electronic" 563 "LOHR Sistemas Eletronicos LTDA" 562 "Bombardier Transportation GmbH" 561 "b-plus GmbH" 560 "Iowa State University, Agricultural and Biosystems Engineering" 559 "Four Peaks Navigation" 558 "Davis Instruments Corp." 557 "Rockson Automation GmbH" 556 "Doosan Infracore Norway" 555 "Sasaki Corporation" 554 "iris-GmbH infrared & intelligent sensors" 553 "KIB Electronics" 552 "Matsuyama Plow Mfg Co, Ltd" 551 "Wexler CSD Ltd." 550 "SUN-A Corporation" 549 "ROAD Deutschland GmbH" 548 "TM4 Inc." 547 "Thomson Linear LLC" 546 "Maruyama Mfg Co, Inc." 545 "GS Hydraulics" 544 "Au Group Electronics" 543 "BAUER Maschinen GmbH" 542 "Dinamica Generale s.p.a." 541 "Total Fire Systems, Inc." 540 "Dinex A/S" 539 "Mobileview" 538 "Crop Ventures, Inc." 537 "Schrader Electronics Ltd." 536 "SSI Technologies" 535 "MOTORPAL, a.s." 534 "Webasto Thermo & Comfort SE" 533 "Doran Manufacturing, LLC" 532 "Onwa Marine Electronics Co Ltd." 531 "Genge & Thoma AG" 530 "NMEA" 529 "National Instruments Korea" 528 "Hoganas AB, Electric Drive Systems" 527 "GKN Walterscheid GmbH" 526 "LOFA Industries, Inc" 525 "Rust Sales INC" 470 "SI-TEX Marine Electronics" 469 "RA Consulting GmbH" 468 "Tyco Fire Protection Products" 467 "Lely Industries N.V." 466 "Veethree Electronics and Marine LLC" 465 "Ashcroft Inc" 464 "Leach International Corporation" 463 "PROBOTIQ" 462 "IHI Shibaura Machinery Corporation" 461 "HAWE Hydraulik SE" 460 "San Giorgio S.E.I.N." 459 "Alltek Marine Electronics Corp" 458 "Control Solutions, Inc." 457 "RUSELPROM-ElectricDrive Ltd" 456 "General Kinetics" 455 "ADZ NAGANO GmbH" 454 "NGK Spark Plug Co. Ltd" 453 "Cooper Bussmann" 452 "WIKA Alexander Wiegand SE & Co. KG" 451 "Parker Hannifin Corp" 450 "Dycor Technologies Ltd." 449 "Polaris Industries Inc" 448 "Stanadyne Corporation, Electronics Systems" 447 "Great Plains Mfg." 446 "CertTech, L.L.C." 445 "KAT MECHATRONIC, Electronic Product Division" 444 "ITT Power Solutions" 443 "SignalQuest, Inc." 442 "Horsch Maschinen GmbH" 441 "PTG Reifendruckregelsysteme GmbH" 440 "Cummins Power Generation" 439 "Hyundai Heavy Industries" 438 "Comar Systems Ltd" 437 "Digital Yacht Limited" 436 "Kinze Manufacturing" 435 "Zunhammer GmbH" 434 "Stored Energy Systems" 433 "Rowe Electronics" 432 "S&A Systems, Inc." 431 "Tohatsu Corporation" 430 "Auteq Telematica S.A." 429 "Rota Engineering Ltd." 425 "Methode Electronics Inc, MDI" 424 "Odyne LLC" 423 "BSM Wireless, Inc." 422 "True Heading AB" 421 "Vertex Standard Co, Ltd" 420 "Vermeer Corporation, ACS Group" 419 "Fusion Electronics Ltd" 418 "Intellistick Inc" 417 "KZValve" 416 "Kubota Corporation" 415 "Valid Manufacturing Ltd." 414 "Cattron Group International" 413 "Datapross Nijbroek bv" 412 "WebTech Wireless Inc." 411 "Hy-Drive Technologies Ltd." 410 "COBO S.p.A. Divisione 3B6" 409 "Transfluid S.r.L." 408 "Corvus Energy Ltd." 407 "Comtech Mobile Datacom" 406 "Vecima Networks Inc." 405 "Wema System AS" 404 "Com Nav Marine Ltd" 403 "Trackwell ADS, Inc." 402 "Simma Software, Inc." 401 "Torqeedo GmbH" 400 "Livorsi Marine" 399 "ISEKI & Co., Ltd." 398 "Hilite International" 397 "Sanyo-kiki Co Ltd." 396 "Beyond Measure" 395 "GENTEC S.R.L." 394 "Capi 2 Nederland B.V." 393 "Harvest Tec, Inc" 392 "Tianyuan Technology Co Ltd." 391 "Electronic Design for Industry, Inc" 390 "Partech Inc." 389 "Benchmark Electronics, Minnesota Division" 388 "Innomatix, LLC" 387 "Orscheln Products, LLC" 386 "JLG Automation BVBA" 385 "Johnson Outdoor Marine Electronics" 384 "Camano Light" 383 "MCL Industries" 382 "National Agriculture and Food Research Organization" 381 "B & G" 380 "Suntech International Ltd." 379 "Yamabiko Corporation" 378 "Glendinning Marine Products" 377 "ifm electronic gmbh" 376 "Quake Global" 375 "Williams Controls Inc." 374 "Northern Lights, Inc." 373 "Electronic Design Inc." 372 "Delphi" 371 "Heinzmann GmbH & Co. KG" 370 "Rolls-Royce Marine AS" 369 "Power Torque Engineering Ltd" 368 "HANSENHOF_electronic" 367 "Fliegl Agrartechnik" 366 "Viewnyx Corp." 365 "Digi-Star, LLC" 364 "OEM Controls Inc." 363 "BEI Duncan" 362 "Poettinger Landtechnik GmbH (formerly Alois Poettinger Maschinenfabrik GmbH)" 361 "InMach" 360 "HJS Emission Technology GmbH & Co KG   (formerly HJS Fahrzeugtechnik GmbH & Co KG)" 359 "Ludwig Bergmann GmbH" 358 "Victron Energy B.V." 357 "Hardi International A/S" 356 "Fischer Panda Generators, Inc" 355 "Mastervolt International B.V." 354 "Junkkari OY" 353 "Hegemon Electronics, Inc." 352 "SAME DEUTZ-FAHR GROUP S.p.A." 351 "Thrane & Thrane" 350 "Noris Marine Systems GmbH & Co KG" 349 "Suonentieto" 348 "Amazonen Werke H. Dreyer" 347 "Honeywell" 346 "Control Solutions" 345 "Korean Maritime University" 344 "Parvus Corporation" 343 "Baumer Group" 342 "THOMAS MAGNETE GmbH" 341 "Boning GmbH & Co" 340 "Continental AG" 339 "Competence Center ISOBUS e.V." 338 "GRAF-SYTECO" 337 "Carraro S.p.A." 336 "APE s.r.o." 335 "Evo Electric Ltd" 334 "Takata-Petri AG" 333 "Hadley Products Corporation" 332 "HWH Corporation" 331 "Horton, Inc." 330 "Kidde Aerospace and Defense" 329 "Deif A/S" 328 "Qwerty Electronik AB" 327 "Sonceboz SA" 326 "Akron Brass Company" 325 "ASM Automation Sensorik Messtechnik GmbH" 324 "Snap-on Diagnostics" 323 "Mobileye Vision Technologies Ltd." 322 "MICHENKA s.r.o." 321 "Ultra Electronics, Electrics" 320 "Miedema Landbouwwerktuigenfabriek B.V." 319 "Cadec Global" 318 "SAT Plan" 317 "Navtronics Bvba" 263 "IMMI" 262 "HydraForce, Inc" 261 "Red Dot Corporation" 260 "Reichhardt GmbH Steuerungstechnik" 259 "Jetter AG" 258 "ARAG" 257 "Honda Motor Co., Ltd" 256 "Tyco Electronics AMP" 255 "MEAS France" 254 "GE Sensing" 253 "Mobile Control Systems" 252 "Sensor-Technik Wiedemann GmbH" 251 "German Agricultural Society, Test Center (DLG)" 250 "Kuhn Group" 249 "Schaltbau GmbH" 248 "Cooper Standard Automotive Active Systems Group" 247 "ePULSE" 246 "Class 1, Inc" 245 "Capstan Ag Systems, Inc." 244 "Techno-Matic" 243 "eRide, Inc." 242 "Kokusandenki Co. Ltd" 241 "Schneider Automation SAS" 240 "Vanair Mfg" 239 "May & Scofield Ltd" 238 "ZF Friedrichshafen AG" 237 "Agtron Enterprises Inc" 236 "NORAC Systems International Inc" 235 "SailorMade Marine Telemetry - Tetra Technology Ltd." 234 "Mondial electronic GmbH" 233 "Yacht Monitoring Solutions Inc." 232 "TSD Integrated Controls" 231 "Topcon Positioning Systems, Inc." 230 "Saucon Technologies" 229 "Garmin International Inc." 228 "Unused (formerly ZF Marine Electronics)" 227 "Lykketronic A/S" 226 "Monaco Coach Corporation" 225 "SKF" 224 "EMMI Network, S.L." 223 "Vaueo Retarder Co., Ltd." 222 "Generac Power Systems, Inc." 221 "SiE" 220 "Beede Electrical Instrument Company, Inc" 219 "Cat OEM Solutions" 218 "Gits Manufacturing Company" 217 "RM Michaelides Software & Elektronik GmbH" 216 "Paneltronics Inc." 215 "Aetna Engineering/Fireboy-Xintex" 214 "MC elettronica Srl" 164 "MTU Friedrichshafen GmbH (formerly DaimlerChrysler Off-Highway)" 163 "BRP Inc." 162 "Axiomatic Technologies" 161 "Offshore Systems (UK) Ltd" 160 "Nido" 159 "NTech Industries Inc" 158 "Firestone Industrial Products Company" 157 "ISSPRO Inc." 156 "ITT Industries - Cannon" 155 "Vetronix Corporation" 154 "Westerbeke Corporation" 153 "Woodward, Industrial Controls Division" 152 "elobau GmbH & Co. KG" 151 "Raven Industries, Inc." 150 "Fleetguard" 149 "Holset" 148 "Blue Water Data, Inc." 147 "Nautibus electronic GmbH" 146 "Maxima Technologies" 145 "MurCal Controls" 144 "Mercury Marine" 143 "W. Gmeiner GmbH & Co." 142 "TRW Automotive (Commercial Steering Systems)" 141 "Thales Navigation Ltd." 140 "Lowrance Electronics, Inc." 139 "Caterpillar Trimble Control Technologies (CTCT), LLC" 138 "Georg Fritzmeier GmbH & Co. KG" 137 "Maretron" 136 "Komatsu Ltd" 135 "Airmar Technology Corporation" 134 "Iris Technology Ltd" 133 "Bucher Schoerling GmbH" 132 "Mulag-Fahrzeugwerk" 131 "ITT Industries" 130 "Nido - Universal Machines B.V." 129 "OMNEX Control Systems Inc." 128 "Gerhard Duecker GmbH & Co. KG" 127 "Holland USA" 126 "Driver Tech" 125 "Nevada Automotive Test Center" 124 "Hydac Electronic" 123 "Basler Electric" 122 "FG Wilson (Engineering) Limited" 121 "HED (Hydro Electronic Devices, Inc.)" 120 "RDS Technology Ltd" 119 "IntegriNautics  " 118 "Intron GmbH" 117 "HUSCO International" 116 "BEELINE Technologies" 115 "NACCO Materials Handling Group, Inc." 114 "EControls, Inc." 113 "Stress-Tek, Inc." 112 "MECALAC" 111 "Bernard Krone Holding SE & Co. KG (formerly Maschinenfabrik Bernard Krone GmbH)" 110 "EPIQ Sensor-Nite" 109 "TeeJet Technologies Denmark (formerly LH Technologies ApS)" 108 "WTK-Elecktronik GmbH" 107 "Grimme Landmaschinen GmbH & Co. KG" 106 "BAE Systems Controls, Inc." 105 "Kiepe Elektrik GmbH & Co. KG" 104 "CLAAS KGaA mbH (formerly CLAAS Selbstfahrende Erntemaschinen GmbH)" 103 "CLAAS E-Systems GmbH (formerly CLAAS E-Systems KGaA mbH & Co. KG)" 102 "AGCO (formerly AGCO GmbH & Co.)" 101 "Sensoria" 100 "VDO Technik AG" 99 "International Transmissions Ltd (ITL)" 98 "Mueller-Elektronik GmbH & Co" 97 "Ag Leader Technology, Inc." 96 "Mech@tronic IT GmbH" 95 "Pacific Insight Electronics Corp." 94 "CNH Industrial N.V. (formerly CNH Global N.V.)" 93 "Perkins Engines Company Ltd." 92 "Ag-Chem Equipment Co., Inc." 91 "BSG Bodensee Steuergeraete GmbH" 90 "Knorr-Bremse SfN GmbH" 89 "Kverneland Group, Electronics Division" 88 "Hemisphere GPS Inc (formerly Satloc Precision GPS)" 87 "J.C. Bamford Excavators Ltd (JCB)" 86 "C. E. Niehoff & Company" 85 "Kohler Co" 84 "New Holland UK Limited" 83 "Bendix VORAD Technologies (formerly Eaton VORAD Technologies)" 82 "Bobcat/Ingersoll-Rand (formerly Melroe/Ingersoll-Rand)" 81 "Fire Research Corp." 80 "Twin Disc, Inc." 79 "Daimler Benz AG - Engine Division (PBM)" 78 "Frank W. Murphy Manufacturing, Inc" 77 "Deere Power Systems Group" 76 "unused (formerly Deere & Co, Construction Division)" 75 "Deere & Co, Agricultural Division" 74 "Eaton Axle-Brake Division" 73 "LeTourneau, Inc." 72 "Sisu Corporation" 71 "Vansco Electronics Ltd." 70 "Flex-coil Limited" 69 "Trimble Navigation" 316 "ITT Flow Control" 315 "Icom Incorporated" 314 "CSM GmbH" 313 "Ilmor Engineering, Inc." 312 "Lectronix, Inc." 311 "Patrick Power Products" 310 "TECNORD srl" 309 "Krauss-Maffei Wegmann GmbH & Co. KG" 308 "Cyntrx" 307 "MAS Technologies" 306 "Sleipner Motor AB" 305 "NovAtel Inc" 304 "EmpirBus AB" 303 "CTS Corporation" 302 "Nissin Kogyo Co., LTD" 301 "Parker Hannifin (UK) Ltd FDE group" 300 "Systron Donner Automotive" 299 "Rauch" 298 "Holley Performance" 297 "Zonar Systems Inc" 296 "micro dynamics GmbH" 295 "BEP Marine" 294 "Grayhill Inc." 293 "Spyder Controls Corp." 292 "IKUSI - Angel Iglesias S.A." 291 "Groeneveld Transport Efficiency BV" 290 "Kuebler GmbH" 289 "Watlow" 288 "Mitsubishi FUSO Truck & Bus Corp." 287 "NTech Industries, Inc" 286 "Coelmo srl" 285 "Sea Recovery Corp" 284 "Mobile Tech Chile" 283 "CWF Hamilton & Co Ltd" 282 "Medallion Instrumentation Systems" 281 "Precision Governors LLC" 280 "Leica Geosystems Pty Ltd" 279 "Geometris LP" 278 "Takata Electronics" 277 "LHP Telematics" 276 "Aqua-Hot Heating Systems" 275 "Navico Egersund AS" 274 "LTW Technology Co., LTD" 273 "Active Research Limited" 272 "Gross Mechanical Laboratories, Inc" 271 "Cole Hersee" 270 "Tennant" 269 "Saft America Inc.,  Space & Defense Division" 268 "Accurate Technologies" 267 "Red Lion Controls, Inc" 266 "International Thermal Research Ltd" 265 "MTS Sensor Technologie GmbH" 264 "Autolync" 213 "CNH Belgium N.V." 212 "Sure Power Industries, Inc" 211 "DNA Group" 210 "Iteris, Inc." 209 "Bell Equip. Co. SA (PTY) LTD" 208 "Drew Technologies, Inc" 207 "Otto Engineering" 206 "port GmbH" 205 "SmarTire Systems Inc" 204 "The Morey Corporation" 203 "MILtronik GmbH" 202 "Curtis Instruments, Inc" 201 "Disenos y Tecnologia S.A." 200 "MGM Brakes" 199 "ACTIA Group (formerly Actia Corp)" 198 "Mystic Valley Communications" 197 "Mechron Power Systems" 196 "LEMKEN GmbH & Co KG" 195 "General Engine Products" 194 "TriMark Corporation" 193 "Jeppesen Marine" 192 "Floscan" 191 "XRS Corporation (formerly XATA Corporation)" 190 "Hella KGaA Hueck & Co" 189 "QUALCOMM" 188 "EMP Corp" 187 "Air-Weigh" 186 "Altronic, Inc" 185 "Beede Electrical Instrument Company" 184 "EIA Electronics" 183 "KDS Controls, Inc" 182 "Vehicle Systems Engineering B.V." 181 "Coretronics, Inc." 180 "Smart Power Systems" 179 "TeeJet Technologies Springfield (formerly Midwest Technologies Illinois, LLC)" 178 "Continental Automotive GmbH (formerly Siemens VDO Automotive AG)" 177 "Diagnostic Systems Associates" 176 "Moritz Aerospace" 175 "Veris Technologies, Inc." 174 "AB Volvo Penta" 173 "Ryeso, Inc." 172 "Yanmar Co., Ltd. (formerly Yanmar Marine USA)" 171 "Topcon Electronics GmbH & Co. KG (formerly Wachendorff Elektronik GmbH & Co. KG)" 170 "Computronics Corporation Ltd." 169 "Marlin Technologies Inc." 168 "Xantrex" 167 "JLG Industries Inc" 166 "John Deere Electronic Solutions (formerly Phoenix International)" 165 "CPAC Systems AB" 68 "Scania" 67 "John Deere Coffeyville Works (formerly Funk Manufacturing Company)" 66 "John Deere Construction Equipment Division" 65 "MAN Nutzfahrzeuge AG" 64 "Unused (formerly SpectraPrecision Laserplane, then SpectraPhysics)" 63 "ZF Industries Inc." 62 "Wabco" 61 "Volvo Truck Corp." 60 "Volvo Trucks North America Inc." 59 "VES Inc." 58 "SPX Corporation, OTC Div" 57 "Danfoss  (formerly Sauer Sundstrand Co, then Sauer-Danfoss Co)" 56 "SAIC" 55 "Ryder System Inc." 54 "Meritor Wabco" 53 "Continental Automotive Systems US, Inc. (formerly Rockwell Land Transportation)" 52 "Meritor Automotive, Inc. (formerly Rockwell Automotive)" 51 "Robert Bosch GmbH" 50 "Robert Bosch Corp" 49 "RE America Inc." 48 "Pollak Alphabet" 47 "Phillips Semiconductor" 46 "Noregon Systems, Inc  (formerly Parasoft Computing Solutions)" 45 "PACCAR" 44 "Nippondenso Co. Ltd." 43 "International Truck and Engine Corporation - Vehicle Electronics (formerly Navistar Intl Trans Corp.)" 42 "International Truck and Engine Corporation - Engine Electronics  (formerly Navistar Intl Trans Co., Engine Electronics)" 41 "Motorola Inc." 40 "Motorola AIEG Inc." 39 "Microfirm Inc." 38 "Micro Processor Systems Inc." 37 "Mack Trucks Inc." 36 "Lucas Ind." 35 "Kenworth Truck Co." 34 "Kelsey Hayes Co." 33 "John Deere" 32 "Jacobs Vehicle Systems" 31 "J Pollak Corp" 30 "Isuzu Motors Ltd" 29 "Hino Motors Ltd." 28 "Grote Ind. Inc." 27 "GMC" 26 "General Motors Corp, Service Technology Grp" 25 "Daimler Trucks North America LLC (formerly Freightliner LLC)" 24 "Ford Motor Co., Vehicle Controls" 23 "Ford Motor Co., Heavy Truck" 22 "Ford Motor Co., Electronic Concepts & Systems" 21 "Echlin Inc., Midland Brake Inc." 20 "Eaton Ltd" 19 "Eaton Corp. Trucking Info Services" 18 "Eaton Corp, Transmission Div." 17 "Eaton Corp, Corp Res & Dev" 16 "Eaton Corp" 15 "DICKEY-john Corporation" 14 "Detroit Diesel Corporation" 13 "Delco Electronics" 12 "Deere & Company, Precision Farming" 11 "Dearborn Group Inc." 10 "Cummins Inc (formerly Cummins Engine Co)" 9 "Chrysler Corp." 8 "Caterpillar Inc." 7 "Case Corp." 6 "Berifors Electronics AB" 5 "AMP Inc." 4 "Ametek-Dixson" 3 "Ametek, US Gauge Division" 2 "Allison Transmission, Inc." 1 "Bendix Commercial Vehicle Systems LLC (formerly Allied Signal Inc.)" 0 "Reserved" ;
VAL_ 2566838526 IndustryGroup 7 "NotAvailable" 5 "Reserved" 4 "Marine" 3 "Construction" 2 "AgriculturalAndForestry" 1 "OnHighway" 0 "Global" ;
VAL_ 2566838526 VehicleSystem1 0 "NonSpecificSystem" 127 "Not Available" 1 "Tractor" 2 "Trailer" ;
VAL_ 2566838526 VehicleSystem2 0 "NonSpecificSystem" 127 "Not Available" 1 "Tractor" 2 "Tillage" 3 "Secondary Tillage" 4 "Planters/Seeders" 5 "Fertilizers" 6 "Sprayers" 7 "Harvesters" 8 "Root Harvesters" 9 "Forage" 10 "Irrigation" 11 "Transport/Trailer" 12 "Farm Yard Operations" 13 "Powered Auxiliary Device" 14 "Special Crops" 15 "Earth Work" 16 "Skidder" 17 "Sensor Systems" 19 "Timber Harvesters" 20 "Forwarders" 21 "Timber loaders" 22 "Timber Processing Machines" 23 "Mulchers" 24 "Utility Vehicles" 25 "Slurry Applicators" ;
VAL_ 2566838526 VehicleSystem3 0 "NonSpecificSystem" 127 "Not Available" 1 "Skid Steer Loader" 2 "Articulated Dump Truck" 3 "Backhoe" 4 "Crawler" 5 "Excavator" 6 "Forklift" 7 "Four Wheel Drive Loader" 8 "Grader" ;
VAL_ 2566838526 VehicleSystem4 0 "NonSpecificSystem" 127 "Not Available" 10 "System Tools" 20 "Safety Systems" 25 "Inter/Intranetwork Device" 30 "Electrical Distribution" 40 "Steering and Control Surfaces" 50 "Propulsion" 60 "Navigation" 70 "Communications" 80 "Instrumentation/General Systems (deprecate)" 90 "Internal Environment" 100 "Deck, Cargo and Fishing Equipment" 35 "Electrical Generation" 75 "Sensor Communication Interface" 85 "External Environment" 120 "Display" 125 "Entertainment" ;
VAL_ 2566838526 VehicleSystem5 0 "Ind. Process Control Stationary" 127 "Not Available" ;
VAL_ 2566838526 VehicleSystem 127 "Not Available" 0 "NonSpecificSystem" ;
VAL_ 2566838526 Function 43 "Transmission Display" 44 "Exhaust Emission Control" 45 "Vehicle Dynamic Stability Control" 46 "Oil Sensor Unit" 47 "Information System Controller" 48 "Ramp Control" 49 "Clutch/Converter Control" 50 "Auxiliary Heater" 51 "Forward-Looking Collision Warning System" 52 "Chassis Controller" 53 "Alternator/Charging System" 54 "Communications Unit, Cellular" 55 "Communications Unit, Satellite" 56 "Communications Unit, Radio" 57 "Steering Column Unit" 58 "Fan Drive Control" 59 "Starter" 60 "Cab Display" 61 "File Server/Printer" 62 "On-Board Diagnostic Unit" 63 "Engine Valve Controller" 64 "Endurance Braking" 65 "Gas Flow Measurement" 66 "I/O Controller" 67 "Electrical System Controller" 68 "Aftertreatment system gas measurement" 69 "Engine Emission Aftertreatement System" 70 "Auxiliary Regeneration Device" 71 "Transfer Case Control" 72 "Coolant Valve Controller" 73 "Rollover Detection Control" 74 "Lubrication System" 75 "Supplemental Fan" 76 "Temperature Sensor" 77 "Fuel Properties Sensor" 78 "Fire Suppression System" 79 "Power Systems Manager" 80 "Electric Powertrain" 81 "Hydraulic Powertrain" 82 "File Server" 83 "Printer" 84 "Start Aid Device" 85 "Engine Injection Control Module" 86 "Reserved" 87 "Reserved" 88 "Reserved" 89 "Reserved" 90 "Reserved" 91 "Reserved" 92 "Reserved" 93 "Reserved" 94 "Reserved" 95 "Reserved" 96 "Reserved" 97 "Reserved" 98 "Reserved" 99 "Reserved" 100 "Reserved" 0 "Engine" 1 "Auxiliary Power Unit (APU)" 2 "Electric Propulsion Control" 3 "Transmission" 4 "Battery Pack Monitor" 5 "Shift Control/Console" 6 "Power TakeOff - (Main or Rear)" 7 "Axle - Steering" 8 "Axle - Drive" 9 "Brakes - System Controller" 10 "Brakes - Steer Axle" 11 "Brakes - Drive Axle" 12 "Retarder - Engine" 13 "Retarder - Driveline" 14 "Cruise Control" 15 "Fuel System" 16 "Steering Controller" 17 "Suspension - Steer Axle" 18 "Suspension - Drive Axle" 19 "Instrument Cluster" 20 "Trip Recorder" 21 "Cab Climate Control" 22 "Aerodynamic Control" 23 "Vehicle Navigation" 24 "Vehicle Security" 25 "Network Interconnect ECU" 26 "Body Controller" 27 "Power TakeOff (Secondary or Front)" 28 "Off Vehicle Gateway" 29 "Virtual Terminal (in cab)" 30 "Management Computer" 31 "Propulsion Battery Charger" 32 "Headway Controller" 33 "System Monitor" 34 "Hydraulic Pump Controller" 35 "Suspension - System Controller" 36 "Pneumatic - System Controller" 37 "Cab Controller" 38 "Tire Pressure Control" 39 "Ignition Control Module" 40 "Seat Control" 41 "Lighting - Operator Controls" 42 "Water Pump Control" 101 "Reserved" 102 "Reserved" 103 "Reserved" 104 "Reserved" 105 "Reserved" 106 "Reserved" 107 "Reserved" 108 "Reserved" 109 "Reserved" 110 "Reserved" 111 "Reserved" 112 "Reserved" 113 "Reserved" 114 "Reserved" 115 "Reserved" 116 "Reserved" 117 "Reserved" 118 "Reserved" 119 "Reserved" 120 "Reserved" 121 "Reserved" 122 "Reserved" 123 "Reserved" 124 "Reserved" 125 "Reserved" 126 "Reserved" 127 "Reserved" 255 "Not Available" ;
VAL_ 2566838526 ManufacturerCode 1077 "Ymer Technology" 1076 "DOGA S.A." 1075 "Uniden America Corporation" 1074 "Kindhelm / Navigs Oy" 1073 "Manitou Equipment America LLC" 1072 "La Marche Manufacturing Company" 1071 "MACH SYSTEMS s.r.o." 1070 "Quick-teck Electronics Ltd" 1069 "Lithionics Battery LLC" 1068 "Zapi S.p.A." 1067 "Tecomec S.r.l." 1066 "Spot Zero Water" 1065 "CALYPSO Instruments" 1064 "Omnitech Robotics Inc." 1063 "SolSteer" 1062 "Marol Co Ltd" 1061 "Volvo Construction Equipment" 1060 "Scale-Tec" 1059 "Boatrax" 1058 "Bondioli & Pavesi SpA" 1057 "EquipmentShare" 1056 "Lithium Pros" 1055 "EXA Computing GmbH" 1054 "Schmotzer Hacktechnik GmbH & Co. KG" 1053 "Vetus Maxwell, Inc." 1052 "Pfreundt" 1051 "ProNav AS" 1050 "Spacenus GmbH" 1049 "S&S Cycle" 1048 "Agrivation UG" 1047 "Sonic Corporation" 1046 "Praxidyn" 1045 "CMR Group" 1044 "Xee" 1043 "Hyva" 1042 "engcon group" 1041 "EZ Lynk" 1040 "BPE Electronics Srl" 1039 "Liugong Dressta Machinery" 1038 "EMIT Technologies, Inc." 1037 "Dragonfly Energy Corp." 1036 "Bender GmbH & Co. KG" 1035 "Agres" 1034 "Siren Marine" 1033 "ECCO Safety Group" 1032 "SIMOL S.p.A." 1031 "Flintec UK Ltd." 1030 "Tume-Agri Oy" 1029 "The Marine Guardian LLC" 1028 "Autel Intelligent Technology Corp., Ltd" 1027 "Goldacres PTY LTD" 1026 "ZTR Control Systems, LLC" 1025 "eze System, Inc." 1024 "Inventus Power" 1023 "PEAK-System Technik GmbH" 1022 "ITC Inc" 1021 "Entratech Systems LLC" 1020 "Onyx Marine Automation s.r.l." 1019 "Codek Foundries" 1018 "Flex TTS" 1017 "Caldaro AB" 1016 "Röhren- und Pumpenwerk BAUER GmbH" 1015 "SECURITAG SAS" 1014 "Briri Maschinenbau GmbH" 1013 "Allochis E-Tec" 1012 "Rhodan Marine Systems of Florida LLC" 1011 "Soundmax Electronics Ltd" 1010 "Agricultural Industry Electronics Foundation e.V." 1009 "TouchTronics, Inc." 1008 "Lintest Systems LLC" 1007 "Maschinenfabrik Meyer-Lohne GmbH" 1006 "Proterra" 1005 "TSE Brakes, Inc." 1004 "Ultraflex SpA" 1003 "technotrans SE" 1002 "Kussmaul Electronics Co." 1001 "Cleral Inc." 1000 "Landmaschinen Wienhoff GmbH" 1569 "621 Technologies Inc." 999 "TerraTroniq B.V." 998 "Transcell Technology Inc" 997 "Xenta Systems Srl" 996 "Eniquest Pty Ltd" 995 "Circuitlink Pty Ltd." 994 "Morris Industries Ltd." 993 "Alelion Energy Systems AB" 992 "MarineIOT LLC" 991 "Deutronic Elektronik GmbH" 990 "SAMSUNG SDI Co., Ltd." 989 "Flux-Geräte GmbH" 988 "Voith Turbo" 987 "Baltic Car Equipment" 986 "AAMP Global" 985 "NLR, LLC" 984 "E-T-A Elektrotechnische Apparate GmbH" 983 "Dezwaef NV" 982 "Briggs & Stratton Corporation" 981 "Kobelt Manufacturing Co. Ltd" 980 "Gussi Italia S.R.L." 979 "McHale" 978 "Canfield Connector" 977 "Emerson Electric Co." 976 "Derive Systems, Inc." 975 "Siemens AG" 974 "Pico Technology Limited" 973 "Zasso GmbH" 972 "Axion AG" 971 "B+B Smartworx" 970 "Jaboni Power Products, LLC" 969 "Blue Sea Systems" 968 "Cox Powertrain Limited" 967 "Moteck Electric Corp." 966 "VisibleFarm" 965 "Ro-Sys Software" 964 "AgroVIR Kft" 963 "Thomason Jones Company, LLC" 962 "Timbolier Industries, Inc." 961 "POK SAS" 960 "Vemcon GmbH" 959 "Cascade Corporation" 958 "NHK MEC Corporation" 957 "Sierra Wireless Inc" 956 "Piher Sensors & Controls S.A." 955 "Hottinger Baldwin (Suzhou) Electronic Measurement Technology Co., Ltd." 954 "Setec Pty Ltd" 953 "Curtiss-Wright" 952 "Tan Delta Systems Ltd" 951 "Exor International S.p.A." 950 "RE:Lab s.r.l." 949 "Škoda Electric a.s." 948 "Donix" 947 "Gerd Bär GmbH" 946 "Hydac Tecnologia Ltda" 945 "Equalizer AG" 944 "ZONTISA Marine SL" 943 "FISCHER AG Präzisionspindeln" 942 "Vogelsang GmbH & Co. KG" 941 "Navya" 940 "Dometal Oy" 939 "Warn Industries, Inc." 938 "LEVEL Systems" 937 "Precision Circuits Inc" 936 "Hi-tech Millennium" 935 "Meels GmbH & Co. KG" 934 "Farmobile, Inc." 933 "Delta Mobile Systems, Inc." 932 "Discover Battery" 931 "Enertec Marine Ltd" 930 "Ecotronix Corp." 929 "Jl Marine Systems, Inc." 928 "EAO Automotive GmbH & Co. KG" 927 "Saicon" 926 "Buhler Industries Inc." 925 "GW Lisk Company" 924 "PAS Peschak Autonome Systeme GmbH" 923 "ELTEK S.p.A." 922 "Terberg Benschop B.V." 921 "ROPA Fahrzeug- und Maschinenbau GmbH" 920 "MTD Consumer Group Inc." 919 "Furrion LLC" 918 "AMW Machine Control, Inc" 917 "Sentinel d.o.o." 916 "Turck Inc." 915 "Dosificacion y sistemas electronicos S.L. (DSE)" 914 "ZETOR TRACTORS a.s." 913 "Toyota Motor Corporation" 912 "Steyr Motors GmbH" 911 "Nautic-On" 910 "Hermann Paus Maschinenfabrik GmbH" 909 "Marines Co., Ltd." 908 "Chonbuk National University Department of Electronics" 907 "strautmann" 906 "MOBA AG" 905 "ASA Electronics" 904 "Equipment Safety Systems Pty. Ltd. (EQSS)" 903 "InMotion" 902 "Bucher Hydraulics" 901 "Zivan Srl" 900 "OSB AG" 899 "Lippert Components, Inc" 898 "Josef Kotte Landtechnik GmbH & Co. KG" 897 "Dot Technology Corp." 896 "NextFour Solutions Ltd" 895 "Peloton Technology" 894 "Rhodan Marine Systems of Florida LLC" 893 "KlinkTechnics Ltd." 892 "Mectronx Corp" 891 "CarrierWeb" 890 "L3 Technologies, Inc." 889 "SANY America Inc" 888 "Carma Systems Inc" 887 "Hyperdrive Innovation Limited" 886 "Hitachi Zosen Corporation" 885 "SICK Stegmann GmbH" 884 "Sure Grip Controls Inc." 883 "Swift Navigation, Inc." 882 "BHTronik GmbH & Co. KG" 881 "Sovema" 880 "Revision Military" 879 "PG Trionic, Inc." 878 "FOTON" 877 "SICK ATech GmbH" 876 "SUCO Robert Scheuffele GmbH & Co. KG" 875 "Salvarani S.r.l." 874 "MTA S.p.A." 873 "Garnet Instruments Ltd." 872 "Kählig Antriebstechnik GmbH" 871 "Superior Tech Inc" 870 "Textron Fleet Management" 869 "Intercomp" 868 "Data Panel Corp" 867 "Skeleton Technologies" 866 "Netradyne, Inc." 865 "MyEasyFarm" 864 "Streamline Transportation Technologies Inc." 863 "SMAG" 862 "Prospec Electronics" 861 "Adel System S.r.l." 860 "Michelin" 859 "Valor" 858 "Littelfuse" 857 "Zoomlion Heavy Industry NA, Inc" 856 "FarmFacts GmbH" 855 "Toshiba Infrastructure Systems & Solutions Corporation" 854 "GEMAC Chemnitz GmbH" 853 "Teledyne RESON B.V." 852 "Velvac Inc" 851 "Novotechnik Messwertaufnehmer OHG" 850 "Geoprospectors GmbH" 849 "MTS Maschinentechnik Schrode AG" 848 "ningupex" 847 "Oceanvolt" 846 "L3 Magnet-Motor" 845 "GMB Güstrower Maschinenbau GmbH" 844 "FELL AS" 843 "Hendrickson Truck Commercial Vehicle Systems" 842 "DigiDevice Srl" 841 "Agra-GPS" 840 "E.S.T.E. Srl" 839 "Indexator Rotator Systems AB" 838 "Teamsurv Ltd" 837 "Famic Technologies Inc." 836 "Signature4" 835 "PetTrack Ltd." 834 "Pioneer Microsystems, Inc." 833 "Electrum Automation AB" 832 "Heizomat Gerätebau-Energiesysteme GmbH" 831 "DOK-ING Ltd." 830 "Ultra Motion LLC" 829 "Drov Technologies, Inc." 828 "AgriBrink Inc." 827 "INmatix Technology Group Ltd" 826 "Lewmar Marine Inc" 825 "BPW Hungária" 824 "Undheim Systems AS" 823 "ACEINNA, Inc (formerly MEMSIC, Inc)" 822 "Bren-Tronics, Inc." 821 "Thorsen Teknik A/S" 820 "DIaLOGIKa Gesellschaft fuer angewandte Informatik mbH" 819 "Preco Electronics" 818 "HGNSS" 817 "TE Connectivity Sensor Solutions" 816 "UniStrong" 815 "FLIR Systems, Inc." 814 "Kronotech Srl (formerly Soltec Soluzioni Tecnologiche Srl)" 813 "Thales Suisse SA" 812 "Torch Technologies" 811 "Blue Water Desalination" 810 "Dutch Power Company" 809 "HMS Industrial Networks AB" 808 "RIMEX Supply Ltd." 807 "Schneider-Electric" 806 "Charge Automotive Ltd" 805 "Gundersen & Løken AS" 804 "ASA Electronics" 803 "Gill Sensors & Controls Limited" 802 "SPBI (Bj Technologie)" 801 "LOR Manufacturing Company Inc." 800 "Delta-Q Technologies" 799 "Stillwater Designs and Audio, Inc. - KICKER" 798 "Lumishore Ltd" 797 "Tides Marine" 796 "Canadian Automotive Industries Ltd" 795 "Broyda Enterprises Pty Ltd" 794 "Shihlin Electric & Engineering Corporation" 793 "James Fisher Prolec" 792 "Kostal Mexicana" 791 "AUTEC" 790 "VACALL" 789 "GRADALL" 788 "MoTeC Pty Ltd" 787 "Abertax Technologies Limited" 1863 "Thomas G. Faria Co." 1862 "Sanshin" 1861 "Vector North America" 1860 "MMP" 1859 "Kvasar AB" 1858 "Litton" 1857 "Simrad" 1856 "Trimble" 1855 "Furuno USA" 1854 "Northstar Technologies" 1853 "Japan Radio Co" 1852 "Navionics" 1851 "RayMarine" 1850 "Seastar Solutions (formerly Teleflex)" 786 "Johnson Matthey Battery Systems" 785 "Fischer Panda GmbH" 784 "CM Automotive Systems, Inc." 783 "Loup Electronics Inc." 782 "AVR bv (formerly AVR bvba)" 781 "Poly-Planar LLC" 780 "AVID Technology Ltd" 779 "RLC Electronic Systems" 778 "Seakeeper Inc." 777 "Ocean Signal Ltd" 776 "HMI Systems LLC" 775 "ZIEHL-ABEGG Automotive GmbH" 774 "Taisho Corporation" 773 "Clarion Corporation of America" 772 "Blink Marine" 771 "Shaw Development, LLC" 770 "MONOSEM" 769 "Trombetta" 768 "Flores Automation, LLC" 767 "Alliance Wireless Technologies Inc." 766 "Epec Oy" 765 "GIGAVAC" 764 "Bednar FMT s.r.o." 763 "AT-Systems BVBA" 762 "ROJ s.r.l." 761 "MITA OLEODINAMICA S.p.A." 760 "Bernecker + Rainer Industrie Elektronik GmbH" 759 "Hydro-Gear" 758 "Banner Engineering Corp." 757 "IMPCO Technologies" 756 "Maschio Gaspardo S.P.A." 755 "Firefly Integrations" 754 "Parker Hannifin Corp., Automation Group" 753 "AIROD Technologies" 752 "Deep Sea Electronics Plc" 751 "Pacific Track" 750 "Joskin SA" 749 "Chart Inc." 748 "ISOTTA" 747 "Agratronix" 746 "SureFire Ag Systems, Inc." 745 "Cidra Corporate Services Inc." 744 "Woosung Engineering Co., Ltd." 743 "Daemyung Elevator Co., Ltd." 742 "EROAD" 741 "Carling Technologies" 740 "e-Traction" 739 "LXNAV d.o.o." 738 "Blue Ink Technologies" 737 "Balluff GmbH" 736 "Terex Aerial Work Platforms - Genie" 735 "AEM Performance Electronics" 734 "REAPsystems" 733 "Intendia S.L." 732 "Gefran S.p.A." 731 "Modine Manufacturing Company" 730 "BERTHOUD AGRICOLE" 729 "Liebherr" 728 "Streumaster (formerly Streumaster / Panien)" 727 "Dhoot Transmission Pvt Ltd." 726 "MIDORI PRECISIONS" 725 "Hitachi Construction Machinery Co., Ltd." 724 "Electronic Applications, Inc." 723 "Jabil Inc." 722 "Contelec AG" 721 "Hypro" 720 "WITZ Corporation" 719 "Cojali S. L." 718 "Micronet Inc" 717 "Yacht Devices Ltd" 716 "Eaton Control & Power Conversion Division (CPCD)" 715 "Autonnic Research Ltd" 714 "Kobashi Kogyo Co., Ltd." 713 "US Hybrid Corporation" 712 "LOR Manufacturing Company Inc." 711 "DAS Co., LTD" 710 "Greentronics Ltd." 709 "Marquardt GmbH" 708 "Lars Thrane A/S" 707 "Rochester Gauges Inc" 706 "Shanghai Diesel Engine Corporation Limited" 705 "SVAB Hydraulik AB" 704 "JL Audio, Inc." 703 "Hydro Tab Marine Engineering" 702 "Weichai Power Co., Ltd." 701 "BigRoad Inc." 700 "K-Tec Earthmovers Inc." 699 "Harman International Industries" 698 "Scorpion Technologies Ltd." 697 "Ålö AB" 696 "DRS Network & Imaging Systems, LLC (DRS Technologies)" 695 "Weldon Technologies" 694 "GasTOPS Ltd." 693 "Agility Fuel Solutions (formerly Agility Fuel Systems)" 692 "Tanhay Corporation" 691 "Digitroll Agricultural Electronics" 690 "LINAK A/S" 689 "Aarcomm Systems Inc" 688 "Rockford Corp" 687 "Flight Systems, Inc." 686 "Taigene Electric Machinery Corp." 685 "ANEDO (formerly ANEDO Ltd.)" 684 "KEB" 683 "Fosen Elektro" 682 "Eckelmann AG" 681 "BEDIA Motorentechnik GmbH & Co. KG" 680 "AMVAC Chemical Corporation" 679 "Cimco Marine AB" 678 "KeepTruckin, Inc." 677 "DSA Daten- und Systemtechnik GmbH" 676 "Danfoss IXA A/S" 675 "Kawasaki Motors Corp., USA" 674 "Yara International ASA" 673 "Caruelle Nicolas" 672 "OPTIMA Concept" 671 "Innovative Controls Inc." 670 "STEMCO LP" 669 "Quantum Fuel Systems Technologies Worldwide, Inc" 668 "MacDon Industries Ltd." 667 "Bartec" 666 "Schaeffler Technologies AG & Co., KG" 665 "Gebr. Bode GmbH & Co. KG" 664 "Level Developments Ltd" 663 "Delta Systems, Inc" 662 "Kissling Elektrotechnik GmbH" 661 "SPAL Automotive S.r.l." 660 "Auto-Gaz Centrum" 659 "Data Panel Corp." 658 "Shenzhen Jiuzhou Himunication Technology Co., Ltd" 657 "Terzo Power Systems" 656 "PRO SOLUS do Brasil" 655 "Genge & Thoma AG" 654 "Kohler Power Systems, Detroit Engine Development Center (DEDC)" 653 "AEV, spol. s r. o." 652 "MicroControl GmbH & Co. KG" 651 "Takakita Co, Ltd." 650 "Seiko Epson Corp." 649 "Control-Q B.V." 648 "OJSC Ekran" 647 "Siloking" 646 "Veenhuis Machines B.V." 645 "esd electronic system design gmbh" 644 "KUS USA" 643 "Bogballe A/S" 642 "Moog / Aspen Motion Technologies" 641 "Diverse Yacht Services" 640 "Power Solutions International" 639 "Startec s.r.l." 638 "KVH Industries, Inc." 637 "Bavaria Yachtbau GmbH" 636 "Divelbiss Corporation" 635 "Argo Tractors S.p.A." 634 "Rocky Research" 633 "TORC Robotics" 632 "Pepperl+Fuchs GmbH" 631 "Reltima" 630 "SmartDrive Systems Inc." 629 "Agri Info Design, Ltd." 524 "Vomax Instrumentation Pty. Ltd." 523 "Reggio Emilia Innovazione" 522 "Nebraska Tractor Test Laboratory" 521 "Clever Devices Ltd." 520 "Trapeze" 519 "Peeters Landbouwmachines b.v." 518 "Transas USA Inc." 517 "Noland Engineering" 516 "AVAT Automation GmbH" 515 "GINAF Trucks Nederland B.V." 514 "DISTek Integration, Inc." 513 "Precision Technology (Formerly FarmscanAg)" 512 "Inpower LLC" 511 "Sulky" 510 "Marinesoft Co. Ltd" 509 "MOTORTECH GmbH" 508 "Transtech Innovations" 507 "ISOBUS Test Center" 506 "IHI STAR Machinery Corporation" 505 "Yetter Farm Equipment" 504 "Vesper Marine" 503 "Naviop S.R.L." 502 "Attwood Corporation" 501 "Agrotronix S.A." 500 "Oxbo International Corporation" 499 "LCJ Capteurs" 498 "Innovative Design Solutions, Inc." 497 "SENTRON Sistemas Embarcados" 496 "W. Gessmann GmbH" 495 "HOLMER Maschinenbau GmbH" 494 "Synerject" 493 "Watcheye" 492 "Inergy Automotive Systems" 491 "Penny and Giles Ltd" 490 "QuikQ" 489 "Appareo Systems, LLC" 488 "The Charles Machine Works, Inc." 487 "DSE Test Solutions A/S" 486 "Westport Innovations Inc." 485 "MATT automotive" 484 "Headsight Inc." 483 "Valeo" 482 "Tricon Electronics" 481 "Chetco Digital Instruments" 480 "EnerDel, Inc." 479 "Vapor Bus International" 478 "OceanSat B.V." 477 "OilQuick AB" 476 "Hummingbird Marine Electronics" 475 "GME" 474 "Persen Technologies Inc." 473 "Boss Industries, Inc." 472 "Tenneco Inc." 471 "Sea Cross Marine AB" 628 "Falck Schmidt Defence Systems" 627 "Radio Ocean" 626 "AVL DiTEST GmbH" 625 "Global MRV Inc." 624 "Blackbox Machine Control Pty Ltd" 623 "Xirgo Technologies" 622 "Floyd Bell Inc" 621 "Hagie Manufacturing Company" 620 "Sevcon Ltd." 619 "Right Weigh Load Scales" 618 "Evrard SA" 617 "Zero Emission Vehicles" 616 "SMART-TEC s.r.o." 615 "Networkfleet, Verizon Telematics" 614 "ARLT Technologies GmbH" 613 "HKS Co., Ltd." 612 "Samwon IT" 611 "Esterline" 610 "Trail Tech" 609 "Walvoil S.p.A." 608 "Gale Banks Engineering" 607 "Knappco/Civacon" 606 "Intellian Technologies" 605 "Aventics GmbH" 604 "Indexator Rototilt Systems AB" 603 "Kereval" 602 "Nomad Digital Ltd." 601 "Navitas Systems" 600 "Aquatic AV" 599 "Spudnik Equipment Co, LLC" 598 "ABB Turbo Systems Ltd" 597 "Hydac Filter Systems GmbH" 596 "Brunelco Electronic Innovators B.V." 595 "CustomWare" 594 "Kongsberg Automotive" 593 "Sensata Technologies" 592 "tecsis GmbH" 591 "United States Coast Guard" 590 "ARGO-HYTOS GMBH" 589 "MICO, Inc." 588 "Vignal Systems" 587 "JCA Electronics" 586 "Suzuki Motor Corp" 585 "Industrial Electronic Controls" 584 "CarMedialab GmbH" 583 "Yachtcontrol" 582 "Innovative Software Engineering" 581 "Väderstad - Verken AB" 580 "San Jose Technology, Inc." 579 "KVH Industries, Inc." 578 "advanSea" 577 "Denchi Power Ltd  (formerly ABSL Power Solutions Limited)" 576 "Vectia" 575 "Lytx" 574 "Vishay Precision Group" 573 "Orolia Ltd" 572 "Fasse Valves" 571 "Marinecraft Co., Ltd." 570 "frenzel + berg electronic GmbH & Co. KG" 569 "LORD MicroStrain Sensing Systems" 568 "Makersan Ltd. Co." 567 "Lithiumstart LLC" 566 "Geode Technology, Inc." 565 "Micro-Trak Systems, Inc." 564 "Auto Power Electronic" 563 "LOHR Sistemas Eletronicos LTDA" 562 "Bombardier Transportation GmbH" 561 "b-plus GmbH" 560 "Iowa State University, Agricultural and Biosystems Engineering" 559 "Four Peaks Navigation" 558 "Davis Instruments Corp." 557 "Rockson Automation GmbH" 556 "Doosan Infracore Norway" 555 "Sasaki Corporation" 554 "iris-GmbH infrared & intelligent sensors" 553 "KIB Electronics" 552 "Matsuyama Plow Mfg Co, Ltd" 551 "Wexler CSD Ltd." 550 "SUN-A Corporation" 549 "ROAD Deutschland GmbH" 548 "TM4 Inc." 547 "Thomson Linear LLC" 546 "Maruyama Mfg Co, Inc." 545 "GS Hydraulics" 544 "Au Group Electronics" 543 "BAUER Maschinen GmbH" 542 "Dinamica Generale s.p.a." 541 "Total Fire Systems, Inc." 540 "Dinex A/S" 539 "Mobileview" 538 "Crop Ventures, Inc." 537 "Schrader Electronics Ltd." 536 "SSI Technologies" 535 "MOTORPAL, a.s." 534 "Webasto Thermo & Comfort SE" 533 "Doran Manufacturing, LLC" 532 "Onwa Marine Electronics Co Ltd." 531 "Genge & Thoma AG" 530 "NMEA" 529 "National Instruments Korea" 528 "Hoganas AB, Electric Drive Systems" 527 "GKN Walterscheid GmbH" 526 "LOFA Industries, Inc" 525 "Rust Sales INC" 470 "SI-TEX Marine Electronics" 469 "RA Consulting GmbH" 468 "Tyco Fire Protection Products" 467 "Lely Industries N.V." 466 "Veethree Electronics and Marine LLC" 465 "Ashcroft Inc" 464 "Leach International Corporation" 463 "PROBOTIQ" 462 "IHI Shibaura Machinery Corporation" 461 "HAWE Hydraulik SE" 460 "San Giorgio S.E.I.N." 459 "Alltek Marine Electronics Corp" 458 "Control Solutions, Inc." 457 "RUSELPROM-ElectricDrive Ltd" 456 "General Kinetics" 455 "ADZ NAGANO GmbH" 454 "NGK Spark Plug Co. Ltd" 453 "Cooper Bussmann" 452 "WIKA Alexander Wiegand SE & Co. KG" 451 "Parker Hannifin Corp" 450 "Dycor Technologies Ltd." 449 "Polaris Industries Inc" 448 "Stanadyne Corporation, Electronics Systems" 447 "Great Plains Mfg." 446 "CertTech, L.L.C." 445 "KAT MECHATRONIC, Electronic Product Division" 444 "ITT Power Solutions" 443 "SignalQuest, Inc." 442 "Horsch Maschinen GmbH" 441 "PTG Reifendruckregelsysteme GmbH" 440 "Cummins Power Generation" 439 "Hyundai Heavy Industries" 438 "Comar Systems Ltd" 437 "Digital Yacht Limited" 436 "Kinze Manufacturing" 435 "Zunhammer GmbH" 434 "Stored Energy Systems" 433 "Rowe Electronics" 432 "S&A Systems, Inc." 431 "Tohatsu Corporation" 430 "Auteq Telematica S.A." 429 "Rota Engineering Ltd." 425 "Methode Electronics Inc, MDI" 424 "Odyne LLC" 423 "BSM Wireless, Inc." 422 "True Heading AB" 421 "Vertex Standard Co, Ltd" 420 "Vermeer Corporation, ACS Group" 419 "Fusion Electronics Ltd" 418 "Intellistick Inc" 417 "KZValve" 416 "Kubota Corporation" 415 "Valid Manufacturing Ltd." 414 "Cattron Group International" 413 "Datapross Nijbroek bv" 412 "WebTech Wireless Inc." 411 "Hy-Drive Technologies Ltd." 410 "COBO S.p.A. Divisione 3B6" 409 "Transfluid S.r.L." 408 "Corvus Energy Ltd." 407 "Comtech Mobile Datacom" 406 "Vecima Networks Inc." 405 "Wema System AS" 404 "Com Nav Marine Ltd" 403 "Trackwell ADS, Inc." 402 "Simma Software, Inc." 401 "Torqeedo GmbH" 400 "Livorsi Marine" 399 "ISEKI & Co., Ltd." 398 "Hilite International" 397 "Sanyo-kiki Co Ltd." 396 "Beyond Measure" 395 "GENTEC S.R.L." 394 "Capi 2 Nederland B.V." 393 "Harvest Tec, Inc" 392 "Tianyuan Technology Co Ltd." 391 "Electronic Design for Industry, Inc" 390 "Partech Inc." 389 "Benchmark Electronics, Minnesota Division" 388 "Innomatix, LLC" 387 "Orscheln Products, LLC" 386 "JLG Automation BVBA" 385 "Johnson Outdoor Marine Electronics" 384 "Camano Light" 383 "MCL Industries" 382 "National Agriculture and Food Research Organization" 381 "B & G" 380 "Suntech International Ltd." 379 "Yamabiko Corporation" 378 "Glendinning Marine Products" 377 "ifm electronic gmbh" 376 "Quake Global" 375 "Williams Controls Inc." 374 "Northern Lights, Inc." 373 "Electronic Design Inc." 372 "Delphi" 371 "Heinzmann GmbH & Co. KG" 370 "Rolls-Royce Marine AS" 369 "Power Torque Engineering Ltd" 368 "HANSENHOF_electronic" 367 "Fliegl Agrartechnik" 366 "Viewnyx Corp." 365 "Digi-Star, LLC" 364 "OEM Controls Inc." 363 "BEI Duncan" 362 "Poettinger Landtechnik GmbH (formerly Alois Poettinger Maschinenfabrik GmbH)" 361 "InMach" 360 "HJS Emission Technology GmbH & Co KG   (formerly HJS Fahrzeugtechnik GmbH & Co KG)" 359 "Ludwig Bergmann GmbH" 358 "Victron Energy B.V." 357 "Hardi International A/S" 356 "Fischer Panda Generators, Inc" 355 "Mastervolt International B.V." 354 "Junkkari OY" 353 "Hegemon Electronics, Inc." 352 "SAME DEUTZ-FAHR GROUP S.p.A." 351 "Thrane & Thrane" 350 "Noris Marine Systems GmbH & Co KG" 349 "Suonentieto" 348 "Amazonen Werke H. Dreyer" 347 "Honeywell" 346 "Control Solutions" 345 "Korean Maritime University" 344 "Parvus Corporation" 343 "Baumer Group" 342 "THOMAS MAGNETE GmbH" 341 "Boning GmbH & Co" 340 "Continental AG" 339 "Competence Center ISOBUS e.V." 338 "GRAF-SYTECO" 337 "Carraro S.p.A." 336 "APE s.r.o." 335 "Evo Electric Ltd" 334 "Takata-Petri AG" 333 "Hadley Products Corporation" 332 "HWH Corporation" 331 "Horton, Inc." 330 "Kidde Aerospace and Defense" 329 "Deif A/S" 328 "Qwerty Electronik AB" 327 "Sonceboz SA" 326 "Akron Brass Company" 325 "ASM Automation Sensorik Messtechnik GmbH" 324 "Snap-on Diagnostics" 323 "Mobileye Vision Technologies Ltd." 322 "MICHENKA s.r.o." 321 "Ultra Electronics, Electrics" 320 "Miedema Landbouwwerktuigenfabriek B.V." 319 "Cadec Global" 318 "SAT Plan" 317 "Navtronics Bvba" 263 "IMMI" 262 "HydraForce, Inc" 261 "Red Dot Corporation" 260 "Reichhardt GmbH Steuerungstechnik" 259 "Jetter AG" 258 "ARAG" 257 "Honda Motor Co., Ltd" 256 "Tyco Electronics AMP" 255 "MEAS France" 254 "GE Sensing" 253 "Mobile Control Systems" 252 "Sensor-Technik Wiedemann GmbH" 251 "German Agricultural Society, Test Center (DLG)" 250 "Kuhn Group" 249 "Schaltbau GmbH" 248 "Cooper Standard Automotive Active Systems Group" 247 "ePULSE" 246 "Class 1, Inc" 245 "Capstan Ag Systems, Inc." 244 "Techno-Matic" 243 "eRide, Inc." 242 "Kokusandenki Co. Ltd" 241 "Schneider Automation SAS" 240 "Vanair Mfg" 239 "May & Scofield Ltd" 238 "ZF Friedrichshafen AG" 237 "Agtron Enterprises Inc" 236 "NORAC Systems International Inc" 235 "SailorMade Marine Telemetry - Tetra Technology Ltd." 234 "Mondial electronic GmbH" 233 "Yacht Monitoring Solutions Inc." 232 "TSD Integrated Controls" 231 "Topcon Positioning Systems, Inc." 230 "Saucon Technologies" 229 "Garmin International Inc." 228 "Unused (formerly ZF Marine Electronics)" 227 "Lykketronic A/S" 226 "Monaco Coach Corporation" 225 "SKF" 224 "EMMI Network, S.L." 223 "Vaueo Retarder Co., Ltd." 222 "Generac Power Systems, Inc." 221 "SiE" 220 "Beede Electrical Instrument Company, Inc" 219 "Cat OEM Solutions" 218 "Gits Manufacturing Company" 217 "RM Michaelides Software & Elektronik GmbH" 216 "Paneltronics Inc." 215 "Aetna Engineering/Fireboy-Xintex" 214 "MC elettronica Srl" 164 "MTU Friedrichshafen GmbH (formerly DaimlerChrysler Off-Highway)" 163 "BRP Inc." 162 "Axiomatic Technologies" 161 "Offshore Systems (UK) Ltd" 160 "Nido" 159 "NTech Industries Inc" 158 "Firestone Industrial Products Company" 157 "ISSPRO Inc." 156 "ITT Industries - Cannon" 155 "Vetronix Corporation" 154 "Westerbeke Corporation" 153 "Woodward, Industrial Controls Division" 152 "elobau GmbH & Co. KG" 151 "Raven Industries, Inc." 150 "Fleetguard" 149 "Holset" 148 "Blue Water Data, Inc." 147 "Nautibus electronic GmbH" 146 "Maxima Technologies" 145 "MurCal Controls" 144 "Mercury Marine" 143 "W. Gmeiner GmbH & Co." 142 "TRW Automotive (Commercial Steering Systems)" 141 "Thales Navigation Ltd." 140 "Lowrance Electronics, Inc." 139 "Caterpillar Trimble Control Technologies (CTCT), LLC" 138 "Georg Fritzmeier GmbH & Co. KG" 137 "Maretron" 136 "Komatsu Ltd" 135 "Airmar Technology Corporation" 134 "Iris Technology Ltd" 133 "Bucher Schoerling GmbH" 132 "Mulag-Fahrzeugwerk" 131 "ITT Industries" 130 "Nido - Universal Machines B.V." 129 "OMNEX Control Systems Inc." 128 "Gerhard Duecker GmbH & Co. KG" 127 "Holland USA" 126 "Driver Tech" 125 "Nevada Automotive Test Center" 124 "Hydac Electronic" 123 "Basler Electric" 122 "FG Wilson (Engineering) Limited" 121 "HED (Hydro Electronic Devices, Inc.)" 120 "RDS Technology Ltd" 119 "IntegriNautics  " 118 "Intron GmbH" 117 "HUSCO International" 116 "BEELINE Technologies" 115 "NACCO Materials Handling Group, Inc." 114 "EControls, Inc." 113 "Stress-Tek, Inc." 112 "MECALAC" 111 "Bernard Krone Holding SE & Co. KG (formerly Maschinenfabrik Bernard Krone GmbH)" 110 "EPIQ Sensor-Nite" 109 "TeeJet Technologies Denmark (formerly LH Technologies ApS)" 108 "WTK-Elecktronik GmbH" 107 "Grimme Landmaschinen GmbH & Co. KG" 106 "BAE Systems Controls, Inc." 105 "Kiepe Elektrik GmbH & Co. KG" 104 "CLAAS KGaA mbH (formerly CLAAS Selbstfahrende Erntemaschinen GmbH)" 103 "CLAAS E-Systems GmbH (formerly CLAAS E-Systems KGaA mbH & Co. KG)" 102 "AGCO (formerly AGCO GmbH & Co.)" 101 "Sensoria" 100 "VDO Technik AG" 99 "International Transmissions Ltd (ITL)" 98 "Mueller-Elektronik GmbH & Co" 97 "Ag Leader Technology, Inc." 96 "Mech@tronic IT GmbH" 95 "Pacific Insight Electronics Corp." 94 "CNH Industrial N.V. (formerly CNH Global N.V.)" 93 "Perkins Engines Company Ltd." 92 "Ag-Chem Equipment Co., Inc." 91 "BSG Bodensee Steuergeraete GmbH" 90 "Knorr-Bremse SfN GmbH" 89 "Kverneland Group, Electronics Division" 88 "Hemisphere GPS Inc (formerly Satloc Precision GPS)" 87 "J.C. Bamford Excavators Ltd (JCB)" 86 "C. E. Niehoff & Company" 85 "Kohler Co" 84 "New Holland UK Limited" 83 "Bendix VORAD Technologies (formerly Eaton VORAD Technologies)" 82 "Bobcat/Ingersoll-Rand (formerly Melroe/Ingersoll-Rand)" 81 "Fire Research Corp." 80 "Twin Disc, Inc." 79 "Daimler Benz AG - Engine Division (PBM)" 78 "Frank W. Murphy Manufacturing, Inc" 77 "Deere Power Systems Group" 76 "unused (formerly Deere & Co, Construction Division)" 75 "Deere & Co, Agricultural Division" 74 "Eaton Axle-Brake Division" 73 "LeTourneau, Inc." 72 "Sisu Corporation" 71 "Vansco Electronics Ltd." 70 "Flex-coil Limited" 69 "Trimble Navigation" 316 "ITT Flow Control" 315 "Icom Incorporated" 314 "CSM GmbH" 313 "Ilmor Engineering, Inc." 312 "Lectronix, Inc." 311 "Patrick Power Products" 310 "TECNORD srl" 309 "Krauss-Maffei Wegmann GmbH & Co. KG" 308 "Cyntrx" 307 "MAS Technologies" 306 "Sleipner Motor AB" 305 "NovAtel Inc" 304 "EmpirBus AB" 303 "CTS Corporation" 302 "Nissin Kogyo Co., LTD" 301 "Parker Hannifin (UK) Ltd FDE group" 300 "Systron Donner Automotive" 299 "Rauch" 298 "Holley Performance" 297 "Zonar Systems Inc" 296 "micro dynamics GmbH" 295 "BEP Marine" 294 "Grayhill Inc." 293 "Spyder Controls Corp." 292 "IKUSI - Angel Iglesias S.A." 291 "Groeneveld Transport Efficiency BV" 290 "Kuebler GmbH" 289 "Watlow" 288 "Mitsubishi FUSO Truck & Bus Corp." 287 "NTech Industries, Inc" 286 "Coelmo srl" 285 "Sea Recovery Corp" 284 "Mobile Tech Chile" 283 "CWF Hamilton & Co Ltd" 282 "Medallion Instrumentation Systems" 281 "Precision Governors LLC" 280 "Leica Geosystems Pty Ltd" 279 "Geometris LP" 278 "Takata Electronics" 277 "LHP Telematics" 276 "Aqua-Hot Heating Systems" 275 "Navico Egersund AS" 274 "LTW Technology Co., LTD" 273 "Active Research Limited" 272 "Gross Mechanical Laboratories, Inc" 271 "Cole Hersee" 270 "Tennant" 269 "Saft America Inc.,  Space & Defense Division" 268 "Accurate Technologies" 267 "Red Lion Controls, Inc" 266 "International Thermal Research Ltd" 265 "MTS Sensor Technologie GmbH" 264 "Autolync" 213 "CNH Belgium N.V." 212 "Sure Power Industries, Inc" 211 "DNA Group" 210 "Iteris, Inc." 209 "Bell Equip. Co. SA (PTY) LTD" 208 "Drew Technologies, Inc" 207 "Otto Engineering" 206 "port GmbH" 205 "SmarTire Systems Inc" 204 "The Morey Corporation" 203 "MILtronik GmbH" 202 "Curtis Instruments, Inc" 201 "Disenos y Tecnologia S.A." 200 "MGM Brakes" 199 "ACTIA Group (formerly Actia Corp)" 198 "Mystic Valley Communications" 197 "Mechron Power Systems" 196 "LEMKEN GmbH & Co KG" 195 "General Engine Products" 194 "TriMark Corporation" 193 "Jeppesen Marine" 192 "Floscan" 191 "XRS Corporation (formerly XATA Corporation)" 190 "Hella KGaA Hueck & Co" 189 "QUALCOMM" 188 "EMP Corp" 187 "Air-Weigh" 186 "Altronic, Inc" 185 "Beede Electrical Instrument Company" 184 "EIA Electronics" 183 "KDS Controls, Inc" 182 "Vehicle Systems Engineering B.V." 181 "Coretronics, Inc." 180 "Smart Power Systems" 179 "TeeJet Technologies Springfield (formerly Midwest Technologies Illinois, LLC)" 178 "Continental Automotive GmbH (formerly Siemens VDO Automotive AG)" 177 "Diagnostic Systems Associates" 176 "Moritz Aerospace" 175 "Veris Technologies, Inc." 174 "AB Volvo Penta" 173 "Ryeso, Inc." 172 "Yanmar Co., Ltd. (formerly Yanmar Marine USA)" 171 "Topcon Electronics GmbH & Co. KG (formerly Wachendorff Elektronik GmbH & Co. KG)" 170 "Computronics Corporation Ltd." 169 "Marlin Technologies Inc." 168 "Xantrex" 167 "JLG Industries Inc" 166 "John Deere Electronic Solutions (formerly Phoenix International)" 165 "CPAC Systems AB" 68 "Scania" 67 "John Deere Coffeyville Works (formerly Funk Manufacturing Company)" 66 "John Deere Construction Equipment Division" 65 "MAN Nutzfahrzeuge AG" 64 "Unused (formerly SpectraPrecision Laserplane, then SpectraPhysics)" 63 "ZF Industries Inc." 62 "Wabco" 61 "Volvo Truck Corp." 60 "Volvo Trucks North America Inc." 59 "VES Inc." 58 "SPX Corporation, OTC Div" 57 "Danfoss  (formerly Sauer Sundstrand Co, then Sauer-Danfoss Co)" 56 "SAIC" 55 "Ryder System Inc." 54 "Meritor Wabco" 53 "Continental Automotive Systems US, Inc. (formerly Rockwell Land Transportation)" 52 "Meritor Automotive, Inc. (formerly Rockwell Automotive)" 51 "Robert Bosch GmbH" 50 "Robert Bosch Corp" 49 "RE America Inc." 48 "Pollak Alphabet" 47 "Phillips Semiconductor" 46 "Noregon Systems, Inc  (formerly Parasoft Computing Solutions)" 45 "PACCAR" 44 "Nippondenso Co. Ltd." 43 "International Truck and Engine Corporation - Vehicle Electronics (formerly Navistar Intl Trans Corp.)" 42 "International Truck and Engine Corporation - Engine Electronics  (formerly Navistar Intl Trans Co., Engine Electronics)" 41 "Motorola Inc." 40 "Motorola AIEG Inc." 39 "Microfirm Inc." 38 "Micro Processor Systems Inc." 37 "Mack Trucks Inc." 36 "Lucas Ind." 35 "Kenworth Truck Co." 34 "Kelsey Hayes Co." 33 "John Deere" 32 "Jacobs Vehicle Systems" 31 "J Pollak Corp" 30 "Isuzu Motors Ltd" 29 "Hino Motors Ltd." 28 "Grote Ind. Inc." 27 "GMC" 26 "General Motors Corp, Service Technology Grp" 25 "Daimler Trucks North America LLC (formerly Freightliner LLC)" 24 "Ford Motor Co., Vehicle Controls" 23 "Ford Motor Co., Heavy Truck" 22 "Ford Motor Co., Electronic Concepts & Systems" 21 "Echlin Inc., Midland Brake Inc." 20 "Eaton Ltd" 19 "Eaton Corp. Trucking Info Services" 18 "Eaton Corp, Transmission Div." 17 "Eaton Corp, Corp Res & Dev" 16 "Eaton Corp" 15 "DICKEY-john Corporation" 14 "Detroit Diesel Corporation" 13 "Delco Electronics" 12 "Deere & Company, Precision Farming" 11 "Dearborn Group Inc." 10 "Cummins Inc (formerly Cummins Engine Co)" 9 "Chrysler Corp." 8 "Caterpillar Inc." 7 "Case Corp." 6 "Berifors Electronics AB" 5 "AMP Inc." 4 "Ametek-Dixson" 3 "Ametek, US Gauge Division" 2 "Allison Transmission, Inc." 1 "Bendix Commercial Vehicle Systems LLC (formerly Allied Signal Inc.)" 0 "Reserved" ;
VAL_ 2566734590 CertLaboratoryType_FirstDef 7 "Not available (not certified) " 0 "Non-certified laboratory/self-test" 1 "AEF certified laboratory " 2 "Reserved " ;
VAL_ 2566734590 MessageRevision 1 "Third and later edition message revision" 0 "Format of message in second edition." ;
VAL_ 2566734590 CertificationReferenceNumber 0 "NotCertified" 1 "CertificationTestPerformed" ;
VAL_ 2566734590 CertTypeTaskController 0 "NotCertified" 1 "CertificationTestPerformed" ;
VAL_ 2566734590 CertTypeTCWorkingSetMaster 0 "NotCertified" 1 "CertificationTestPerformed" ;
VAL_ 2566734590 CertTypeTCWorkingSetMember 0 "NotCertified" 1 "CertificationTestPerformed" ;
VAL_ 2566734590 CertTypeFileServer 0 "NotCertified" 1 "CertificationTestPerformed" ;
VAL_ 2566734590 CertTypeGPSReceiver 0 "NotCertified" 1 "CertificationTestPerformed" ;
VAL_ 2566734590 CertTypeMinimumECU 0 "NotCertified" 1 "CertificationTestPerformed" ;
VAL_ 2566734590 CertTypeTECUClass1 0 "NotCertified" 1 "CertificationTestPerformed" ;
VAL_ 2566734590 CertTypeTECUClass2 0 "NotCertified" 1 "CertificationTestPerformed" ;
VAL_ 2566734590 CertTypeTECUClass3 0 "NotCertified" 1 "CertificationTestPerformed" ;
VAL_ 2566734590 CertTypeClass3ECU 0 "NotCertified" 1 "CertificationTestPerformed" ;
VAL_ 2566734590 CertTypeVirtualTerminal 0 "NotCertified" 1 "CertificationTestPerformed" ;
VAL_ 2566734590 CertTypeVTWorkingSetMaster 0 "NotCertified" 1 "CertificationTestPerformed" ;
VAL_ 2566734590 CertTypeVTWorkingSetMember 0 "NotCertified" 1 "CertificationTestPerformed" ;
VAL_ 2566734590 CertLaboratoryType_SecondDef 3 "Not available (not certified) " 0 "Non-certified Laboratory/self-certification" 1 "AEF certified laboratory " 2 "Reserved " ;
VAL_ 2566734590 TestProtocolRevision 0 "FirstRevision" 1 "SecondRevision" 2 "ThirdRevision" 3 "NotAvailable" ;
VAL_ 2365391614 StopAllImplOpSwitchState 0 "StopImplementOperations" 1 "PermitAllImplementsToON" 2 "ErrorIndication" 3 "NotAvailable" ;
SG_MUL_VAL_ 2498166526 AffectedMaskObjectID VTFunctionVTtoECU 189-189;
SG_MUL_VAL_ 2498166526 AuxiliaryFunctionID VTFunctionVTtoECU 32-32;
SG_MUL_VAL_ 2498166526 AuxiliaryInputNumber VTFunctionVTtoECU 32-32;
SG_MUL_VAL_ 2498166526 SourceAddressOfAuxiliaryInputDev VTFunctionVTtoECU 32-32;
SG_MUL_VAL_ 2498166526 ErrorCodeSelectColourMap3 VTFunctionVTtoECU 186-186;
SG_MUL_VAL_ 2498166526 ErrorCodeGetAttributeValue3 AttributeID 65535-65535;
SG_MUL_VAL_ 2498166526 ErrorCodeGetAttributeValue2 AttributeID 65535-65535;
SG_MUL_VAL_ 2498166526 ErrorCodeGetAttributeValue1 AttributeID 65535-65535;
SG_MUL_VAL_ 2498166526 GetAttributeValueObjectID AttributeID 65535-65535;
SG_MUL_VAL_ 2498166526 AttributeValue AttributeID 0-65534;
SG_MUL_VAL_ 2498166526 ErrorCodeChangeSoftKeyMask3 VTFunctionVTtoECU 174-174;
SG_MUL_VAL_ 2498166526 ErrorCodeChangeSoftKeyMask4 VTFunctionVTtoECU 174-174;
SG_MUL_VAL_ 2498166526 ErrorCodeAudioVolume3 VTFunctionVTtoECU 164-164;
SG_MUL_VAL_ 2498166526 ErrorCodeHideShowObj4 VTFunctionVTtoECU 160-160;
SG_MUL_VAL_ 2498166526 ErrorCodeGetSupportedWideChars3 VTFunctionVTtoECU 193-193;
SG_MUL_VAL_ 2498166526 Hardware8 VTFunctionVTtoECU 199-199;
SG_MUL_VAL_ 2498166526 Hardware7 VTFunctionVTtoECU 199-199;
SG_MUL_VAL_ 2498166526 ImageIdentificationNumber VTFunctionVTtoECU 198-198;
SG_MUL_VAL_ 2498166526 VTControlAudioSigTerminationTAN VTFunctionVTtoECU 10-10;
SG_MUL_VAL_ 2498166526 ParentMaskObjectID VTFunctionVTtoECU 2-2;
SG_MUL_VAL_ 2498166526 OperatingState4 VTFunctionVTtoECU 38-38;
SG_MUL_VAL_ 2498166526 OperatingState3 VTFunctionVTtoECU 38-38;
SG_MUL_VAL_ 2498166526 VTSelectInputObjectMessageTAN VTFunctionVTtoECU 3-3;
SG_MUL_VAL_ 2498166526 VTOnUserLayoutHideShowMessageTAN VTFunctionVTtoECU 9-9;
SG_MUL_VAL_ 2498166526 VTESCMessageTAN VTFunctionVTtoECU 4-4;
SG_MUL_VAL_ 2498166526 VTChangeNumericValueMessageTAN VTFunctionVTtoECU 5-5;
SG_MUL_VAL_ 2498166526 SoftKeyActivationMessageTAN VTFunctionVTtoECU 0-0;
SG_MUL_VAL_ 2498166526 PointingEventMessageTAN VTFunctionVTtoECU 2-2;
SG_MUL_VAL_ 2498166526 ButtonActivationMessageTAN VTFunctionVTtoECU 1-1;
SG_MUL_VAL_ 2498166526 PathRequested VTFunctionVTtoECU 198-198;
SG_MUL_VAL_ 2498166526 ItemRequested VTFunctionVTtoECU 198-198;
SG_MUL_VAL_ 2498166526 ErrorCodeShowWorkingSet8 VTFunctionVTtoECU 144-144;
SG_MUL_VAL_ 2498166526 ErrorCodeShowWorkingSet5 VTFunctionVTtoECU 144-144;
SG_MUL_VAL_ 2498166526 ErrorCodeShowWorkingSet4 VTFunctionVTtoECU 144-144;
SG_MUL_VAL_ 2498166526 ErrorCodeShowWorkingSet3 VTFunctionVTtoECU 144-144;
SG_MUL_VAL_ 2498166526 ErrorCodeShowWorkingSet2 VTFunctionVTtoECU 144-144;
SG_MUL_VAL_ 2498166526 ErrorCodeShowWorkingSet1 VTFunctionVTtoECU 144-144;
SG_MUL_VAL_ 2498166526 ErrorCodeScreenCapture6 VTFunctionVTtoECU 198-198;
SG_MUL_VAL_ 2498166526 ErrorCodeScreenCapture5 VTFunctionVTtoECU 198-198;
SG_MUL_VAL_ 2498166526 ErrorCodeScreenCapture4 VTFunctionVTtoECU 198-198;
SG_MUL_VAL_ 2498166526 ErrorCodeScreenCapture3 VTFunctionVTtoECU 198-198;
SG_MUL_VAL_ 2498166526 ErrorCodeScreenCapture2 VTFunctionVTtoECU 198-198;
SG_MUL_VAL_ 2498166526 ErrorCodeScreenCapture1 VTFunctionVTtoECU 198-198;
SG_MUL_VAL_ 2498166526 UnsupportedVtFunction VTFunctionVTtoECU 253-253;
SG_MUL_VAL_ 2498166526 AssignedAttribute2OfSet1 VTFunctionVTtoECU 39-39;
SG_MUL_VAL_ 2498166526 AssignedAttribute1OfSet1 VTFunctionVTtoECU 39-39;
SG_MUL_VAL_ 2498166526 FunctionAttributeOfSet1 VTFunctionVTtoECU 39-39;
SG_MUL_VAL_ 2498166526 AuxiliaryFunctionObjectID VTFunctionVTtoECU 36-36;
SG_MUL_VAL_ 2498166526 NumberOfInstancesOfSet1 VTFunctionVTtoECU 39-39;
SG_MUL_VAL_ 2498166526 NumberOfDifferentSetsOfUnit1 VTFunctionVTtoECU 39-39;
SG_MUL_VAL_ 2498166526 AuxiliaryInputObjectID VTFunctionVTtoECU 36-36;
SG_MUL_VAL_ 2498166526 StoreAsPreferredAssignment VTFunctionVTtoECU 36-36;
SG_MUL_VAL_ 2498166526 ErrorCodeChangeAttribute5 VTFunctionVTtoECU 175-175;
SG_MUL_VAL_ 2498166526 AuxiliaryFunctionType VTFunctionVTtoECU 36-36;
SG_MUL_VAL_ 2498166526 SelfConfigurableAddress VTFunctionVTtoECU 36-36;
SG_MUL_VAL_ 2498166526 DeviceClassInstance VTFunctionVTtoECU 36-36;
SG_MUL_VAL_ 2498166526 IndustryGroup VTFunctionVTtoECU 36-36;
SG_MUL_VAL_ 2498166526 FontType_ProportionalFont VTFunctionVTtoECU 195-195;
SG_MUL_VAL_ 2498166526 FontType_FlashHidden VTFunctionVTtoECU 195-195;
SG_MUL_VAL_ 2498166526 FontType_FlashInverted VTFunctionVTtoECU 195-195;
SG_MUL_VAL_ 2498166526 FontType_InvertedText VTFunctionVTtoECU 195-195;
SG_MUL_VAL_ 2498166526 ErrorCodeChangePolygonScale5 VTFunctionVTtoECU 183-183;
SG_MUL_VAL_ 2498166526 FontType_ItalicsText VTFunctionVTtoECU 195-195;
SG_MUL_VAL_ 2498166526 FontType_UnderlinedText VTFunctionVTtoECU 195-195;
SG_MUL_VAL_ 2498166526 FontType_CrossedOutText VTFunctionVTtoECU 195-195;
SG_MUL_VAL_ 2498166526 DeviceClass VTFunctionVTtoECU 36-36;
SG_MUL_VAL_ 2498166526 OperatingState2 VTFunctionVTtoECU 38-38;
SG_MUL_VAL_ 2498166526 VTFunctionCode VTFunctionVTtoECU 254-254;
SG_MUL_VAL_ 2498166526 FontType_BoldText VTFunctionVTtoECU 195-195;
SG_MUL_VAL_ 2498166526 NumberOfPhysicalSoftKeys VTFunctionVTtoECU 194-194;
SG_MUL_VAL_ 2498166526 NumberOfRanges VTFunctionVTtoECU 193-193;
SG_MUL_VAL_ 2498166526 ErrorCodeChangePolygonScale1 VTFunctionVTtoECU 183-183;
SG_MUL_VAL_ 2498166526 OperatingState1 VTFunctionVTtoECU 38-38;
SG_MUL_VAL_ 2498166526 VTBusyCode8 VTFunctionVTtoECU 254-254;
SG_MUL_VAL_ 2498166526 FontSize_128x192 VTFunctionVTtoECU 195-195;
SG_MUL_VAL_ 2498166526 VTBusyCode7 VTFunctionVTtoECU 254-254;
SG_MUL_VAL_ 2498166526 FontSize_128x128 VTFunctionVTtoECU 195-195;
SG_MUL_VAL_ 2498166526 VTBusyCode5 VTFunctionVTtoECU 254-254;
SG_MUL_VAL_ 2498166526 FontSize_96x128 VTFunctionVTtoECU 195-195;
SG_MUL_VAL_ 2498166526 ErrorCodeGetSupportedWideChars2 VTFunctionVTtoECU 193-193;
SG_MUL_VAL_ 2498166526 ErrorCodeChangeListItem5 VTFunctionVTtoECU 177-177;
SG_MUL_VAL_ 2498166526 ErrorCodeChangeListItem4 VTFunctionVTtoECU 177-177;
SG_MUL_VAL_ 2498166526 VTBusyCode4 VTFunctionVTtoECU 254-254;
SG_MUL_VAL_ 2498166526 FontSize_64x96 VTFunctionVTtoECU 195-195;
SG_MUL_VAL_ 2498166526 ErrorCodeObjectPool4 VTFunctionVTtoECU 18-18;
SG_MUL_VAL_ 2498166526 VTBusyCode3 VTFunctionVTtoECU 254-254;
SG_MUL_VAL_ 2498166526 FontSize_64x64 VTFunctionVTtoECU 195-195;
SG_MUL_VAL_ 2498166526 ErrorCodeChangeListItem3 VTFunctionVTtoECU 177-177;
SG_MUL_VAL_ 2498166526 ErrorCodeObjectPool3 VTFunctionVTtoECU 18-18;
SG_MUL_VAL_ 2498166526 VTBusyCode2 VTFunctionVTtoECU 254-254;
SG_MUL_VAL_ 2498166526 FontSize_48x64 VTFunctionVTtoECU 195-195;
SG_MUL_VAL_ 2498166526 ErrorCodeChangeListItem2 VTFunctionVTtoECU 177-177;
SG_MUL_VAL_ 2498166526 ErrorCodeObjectPool2 VTFunctionVTtoECU 18-18;
SG_MUL_VAL_ 2498166526 VTBusyCode1 VTFunctionVTtoECU 254-254;
SG_MUL_VAL_ 2498166526 NrOfYPixelsInDataAreaMask VTFunctionVTtoECU 199-199;
SG_MUL_VAL_ 2498166526 FontSize_32x48 VTFunctionVTtoECU 195-195;
SG_MUL_VAL_ 2498166526 NumberOfPossibleVirtualSoftKeys VTFunctionVTtoECU 194-194;
SG_MUL_VAL_ 2498166526 ErrorCodeGetSupportedWideChars1 VTFunctionVTtoECU 193-193;
SG_MUL_VAL_ 2498166526 ErrorCodeChangeListItem1 VTFunctionVTtoECU 177-177;
SG_MUL_VAL_ 2498166526 Function VTFunctionVTtoECU 36-36;
SG_MUL_VAL_ 2498166526 ErrorCodeObjectPool1 VTFunctionVTtoECU 18-18;
SG_MUL_VAL_ 2498166526 VTChangeActiveMaskParentID VTFunctionVTtoECU 6-6;
SG_MUL_VAL_ 2498166526 ButtonKeyCode VTFunctionVTtoECU 1-1;
SG_MUL_VAL_ 2498166526 SoftKeyCode VTFunctionVTtoECU 0-0;
SG_MUL_VAL_ 2498166526 BooleanValue VTFunctionVTtoECU 33-33;
SG_MUL_VAL_ 2498166526 Status_2 VTFunctionVTtoECU 9-9;
SG_MUL_VAL_ 2498166526 ErrorCodeVTChangeSoftKeyMask4 VTFunctionVTtoECU 7-7;
SG_MUL_VAL_ 2498166526 FontSize_32x32 VTFunctionVTtoECU 195-195;
SG_MUL_VAL_ 2498166526 FontSize_24x32 VTFunctionVTtoECU 195-195;
SG_MUL_VAL_ 2498166526 FontSize_16x24 VTFunctionVTtoECU 195-195;
SG_MUL_VAL_ 2498166526 ErrorCodeChangePosInvalidError VTFunctionVTtoECU 180-180;
SG_MUL_VAL_ 2498166526 ErrorCodeChangeSoftKeyMask5 VTFunctionVTtoECU 174-174;
SG_MUL_VAL_ 2498166526 ErrorCodeChangeChildLocation5 VTFunctionVTtoECU 165-165;
SG_MUL_VAL_ 2498166526 ErrorCodeVTChangeSoftKeyMask3 VTFunctionVTtoECU 7-7;
SG_MUL_VAL_ 2498166526 ErrorCodeChangeStrValueInUse VTFunctionVTtoECU 179-179;
SG_MUL_VAL_ 2498166526 ErrorCodeVtObjPoolError4 VTFunctionVTtoECU 240-240;
SG_MUL_VAL_ 2498166526 FontSize_16x16 VTFunctionVTtoECU 195-195;
SG_MUL_VAL_ 2498166526 ErrorCodeChangeStrError VTFunctionVTtoECU 179-179;
SG_MUL_VAL_ 2498166526 FunctionInstance VTFunctionVTtoECU 36-36;
SG_MUL_VAL_ 2498166526 ErrorCodeVTChangeSoftKeyMask2 VTFunctionVTtoECU 7-7;
SG_MUL_VAL_ 2498166526 ErrorCodeVtObjPoolError3 VTFunctionVTtoECU 240-240;
SG_MUL_VAL_ 2498166526 FontSize_12x16 VTFunctionVTtoECU 195-195;
SG_MUL_VAL_ 2498166526 ErrorCodeChangeStrTooLong VTFunctionVTtoECU 179-179;
SG_MUL_VAL_ 2498166526 ErrorCodeVTChangeSoftKeyMask1 VTFunctionVTtoECU 7-7;
SG_MUL_VAL_ 2498166526 ErrorCodeVtObjPoolError2 VTFunctionVTtoECU 240-240;
SG_MUL_VAL_ 2498166526 FontSize_8x12 VTFunctionVTtoECU 195-195;
SG_MUL_VAL_ 2498166526 ErrorCodeChangePosInvalidObject VTFunctionVTtoECU 180-180;
SG_MUL_VAL_ 2498166526 ErrorCodeChangeStrObjectID VTFunctionVTtoECU 179-179;
SG_MUL_VAL_ 2498166526 ErrorCodeChangeSoftKeyMask2 VTFunctionVTtoECU 174-174;
SG_MUL_VAL_ 2498166526 ErrorCodeChangeChildLocation2 VTFunctionVTtoECU 165-165;
SG_MUL_VAL_ 2498166526 ErrorCodeVtObjPoolError1 VTFunctionVTtoECU 240-240;
SG_MUL_VAL_ 2498166526 AcknowledgmentDeleteVersion VTFunctionVTtoECU 210-210, 214-214;
SG_MUL_VAL_ 2498166526 AcknowledgmentLoadVersion VTFunctionVTtoECU 209-209, 213-213;
SG_MUL_VAL_ 2498166526 AcknowledgmentStoreVersion VTFunctionVTtoECU 208-208, 212-212;
SG_MUL_VAL_ 2498166526 FontSize_8x8 VTFunctionVTtoECU 195-195;
SG_MUL_VAL_ 2498166526 YDotsForSoftKeyDescriptor VTFunctionVTtoECU 194-194;
SG_MUL_VAL_ 2498166526 NewHeigthAttribute VTFunctionVTtoECU 183-183;
SG_MUL_VAL_ 2498166526 ErrorCodeChangePosInvalidParent VTFunctionVTtoECU 180-180;
SG_MUL_VAL_ 2498166526 ErrorCodeChangeSoftKeyMask1 VTFunctionVTtoECU 174-174;
SG_MUL_VAL_ 2498166526 ErrorCodeChangeChildLocation1 VTFunctionVTtoECU 165-165;
SG_MUL_VAL_ 2498166526 Value2 VTFunctionVTtoECU 38-38;
SG_MUL_VAL_ 2498166526 ECUInstance VTFunctionVTtoECU 36-36;
SG_MUL_VAL_ 2498166526 TouchState VTFunctionVTtoECU 2-2;
SG_MUL_VAL_ 2498166526 ErrorCodeSelectObject6 VTFunctionVTtoECU 162-162;
SG_MUL_VAL_ 2498166526 ErrorCodeGraphicsContextCmd5 VTFunctionVTtoECU 184-184;
SG_MUL_VAL_ 2498166526 ErrorCodeChangePriority3 VTFunctionVTtoECU 176-176;
SG_MUL_VAL_ 2498166526 ErrorCodeChangeAttribute4 VTFunctionVTtoECU 175-175;
SG_MUL_VAL_ 2498166526 ErrorCodeChangeColour3 VTFunctionVTtoECU 167-167;
SG_MUL_VAL_ 2498166526 ErrorCodeSelectObject5 VTFunctionVTtoECU 162-162;
SG_MUL_VAL_ 2498166526 ErrorCodeEnableDisableObj4 VTFunctionVTtoECU 161-161;
SG_MUL_VAL_ 2498166526 ErrorCodeGraphicsContextCmd4 VTFunctionVTtoECU 184-184;
SG_MUL_VAL_ 2498166526 ErrorCodeSelectObject4 VTFunctionVTtoECU 162-162;
SG_MUL_VAL_ 2498166526 ErrorCodeEnableDisableObj3 VTFunctionVTtoECU 161-161;
SG_MUL_VAL_ 2498166526 ErrorCodeHideShowObj3 VTFunctionVTtoECU 160-160;
SG_MUL_VAL_ 2498166526 ErrorCodeGraphicsContextCmd3 VTFunctionVTtoECU 184-184;
SG_MUL_VAL_ 2498166526 ErrorCodeChangeAttribute3 VTFunctionVTtoECU 175-175;
SG_MUL_VAL_ 2498166526 ErrorCodeSelectObject3 VTFunctionVTtoECU 162-162;
SG_MUL_VAL_ 2498166526 ErrorCodeEnableDisableObj2 VTFunctionVTtoECU 161-161;
SG_MUL_VAL_ 2498166526 ErrorCodeGraphicsContextCmd2 VTFunctionVTtoECU 184-184;
SG_MUL_VAL_ 2498166526 ErrorCodeChangePriority2 VTFunctionVTtoECU 176-176;
SG_MUL_VAL_ 2498166526 ErrorCodeChangeAttribute2 VTFunctionVTtoECU 175-175;
SG_MUL_VAL_ 2498166526 ErrorCodeChangeColour2 VTFunctionVTtoECU 167-167;
SG_MUL_VAL_ 2498166526 ErrorCodeSelectObject2 VTFunctionVTtoECU 162-162;
SG_MUL_VAL_ 2498166526 ErrorCodeEnableDisableObj1 VTFunctionVTtoECU 161-161;
SG_MUL_VAL_ 2498166526 ErrorCodeHideShowObj2 VTFunctionVTtoECU 160-160;
SG_MUL_VAL_ 2498166526 VisibleSoftKeyMaskObjectID VTFunctionVTtoECU 254-254;
SG_MUL_VAL_ 2498166526 NrOfXPixelsInDataAreaMask VTFunctionVTtoECU 199-199;
SG_MUL_VAL_ 2498166526 XDotsForSoftKeyDescriptor VTFunctionVTtoECU 194-194;
SG_MUL_VAL_ 2498166526 LastWideChar VTFunctionVTtoECU 193-193;
SG_MUL_VAL_ 2498166526 ErrorCodeGraphicsContextCmd1 VTFunctionVTtoECU 184-184;
SG_MUL_VAL_ 2498166526 NewObjectID VTFunctionVTtoECU 177-177;
SG_MUL_VAL_ 2498166526 ErrorCodeChangePriority1 VTFunctionVTtoECU 176-176;
SG_MUL_VAL_ 2498166526 ErrorCodeChangeAttribute1 VTFunctionVTtoECU 175-175;
SG_MUL_VAL_ 2498166526 ValueOfTheObject VTFunctionVTtoECU 168-168;
SG_MUL_VAL_ 2498166526 ErrorCodeChangeColour1 VTFunctionVTtoECU 167-167;
SG_MUL_VAL_ 2498166526 ErrorCodeSelectObject1 VTFunctionVTtoECU 162-162;
SG_MUL_VAL_ 2498166526 ErrorCodeHideShowObj1 VTFunctionVTtoECU 160-160;
SG_MUL_VAL_ 2498166526 ObjectIdOfFaultyObject VTFunctionVTtoECU 18-18;
SG_MUL_VAL_ 2498166526 VTChangeActiveMaskErrorID VTFunctionVTtoECU 6-6;
SG_MUL_VAL_ 2498166526 VTChangeNumericValueValue VTFunctionVTtoECU 5-5;
SG_MUL_VAL_ 2498166526 VTSelectInputObjectIsEdited VTFunctionVTtoECU 3-3;
SG_MUL_VAL_ 2498166526 ButtonObjectParentID VTFunctionVTtoECU 1-1;
SG_MUL_VAL_ 2498166526 KeyObjectParentID VTFunctionVTtoECU 0-0;
SG_MUL_VAL_ 2498166526 NumTransitionsDisabledToEnabled VTFunctionVTtoECU 33-33;
SG_MUL_VAL_ 2498166526 ObjectID_2 VTFunctionVTtoECU 9-9;
SG_MUL_VAL_ 2498166526 Hardware6 VTFunctionVTtoECU 199-199;
SG_MUL_VAL_ 2498166526 ErrorCodeChangeFont6 VTFunctionVTtoECU 170-170;
SG_MUL_VAL_ 2498166526 ManufacturerCode VTFunctionVTtoECU 36-36;
SG_MUL_VAL_ 2498166526 ErrorCodePoolDeleted VTFunctionVTtoECU 6-6;
SG_MUL_VAL_ 2498166526 Hardware5 VTFunctionVTtoECU 199-199;
SG_MUL_VAL_ 2498166526 ErrorCodeChangeActiveMask3 VTFunctionVTtoECU 173-173;
SG_MUL_VAL_ 2498166526 ErrorCodeChangeFillAttributes5 VTFunctionVTtoECU 172-172;
SG_MUL_VAL_ 2498166526 ErrorCodeChangeLineAttribute4 VTFunctionVTtoECU 171-171;
SG_MUL_VAL_ 2498166526 ErrorCodeChangeFont5 VTFunctionVTtoECU 170-170;
SG_MUL_VAL_ 2498166526 ErrorCodeChangeEditPoint3 VTFunctionVTtoECU 169-169;
SG_MUL_VAL_ 2498166526 ErrorCodeObjToSize2 VTFunctionVTtoECU 166-166;
SG_MUL_VAL_ 2498166526 ErrorCodeEscapeObj2 VTFunctionVTtoECU 146-146;
SG_MUL_VAL_ 2498166526 ErrorCodeAnyOtherError VTFunctionVTtoECU 6-6;
SG_MUL_VAL_ 2498166526 ErrorCodeVTEsc5 VTFunctionVTtoECU 4-4;
SG_MUL_VAL_ 2498166526 ErrorCodeChangeNumValue4 VTFunctionVTtoECU 168-168;
SG_MUL_VAL_ 2498166526 Hardware4 VTFunctionVTtoECU 199-199;
SG_MUL_VAL_ 2498166526 ErrorCodeChangeFillAttributes4 VTFunctionVTtoECU 172-172;
SG_MUL_VAL_ 2498166526 ErrorCodeChangeFont4 VTFunctionVTtoECU 170-170;
SG_MUL_VAL_ 2498166526 ErrorCodeMaskOrChildObjectError VTFunctionVTtoECU 6-6;
SG_MUL_VAL_ 2498166526 ErrorCodeChangeNumValue3 VTFunctionVTtoECU 168-168;
SG_MUL_VAL_ 2498166526 Hardware3 VTFunctionVTtoECU 199-199;
SG_MUL_VAL_ 2498166526 ErrorCodeChangePoygonPoint3 VTFunctionVTtoECU 182-182;
SG_MUL_VAL_ 2498166526 ErrorCodeChangeFillAttributes3 VTFunctionVTtoECU 172-172;
SG_MUL_VAL_ 2498166526 ErrorCodeChangeLineAttribute3 VTFunctionVTtoECU 171-171;
SG_MUL_VAL_ 2498166526 ErrorCodeChangeFont3 VTFunctionVTtoECU 170-170;
SG_MUL_VAL_ 2498166526 ErrorCodeMissingObjects VTFunctionVTtoECU 6-6;
SG_MUL_VAL_ 2498166526 ErrorCodeExecuteExtendedMacro3 VTFunctionVTtoECU 188-188;
SG_MUL_VAL_ 2498166526 Hardware2 VTFunctionVTtoECU 199-199;
SG_MUL_VAL_ 2498166526 ErrorCodeSelectColourMap2 VTFunctionVTtoECU 186-186;
SG_MUL_VAL_ 2498166526 ErrorCodeChangePoygonPoint2 VTFunctionVTtoECU 182-182;
SG_MUL_VAL_ 2498166526 ErrorCodeChangeActiveMask2 VTFunctionVTtoECU 173-173;
SG_MUL_VAL_ 2498166526 ErrorCodeChangeFillAttributes2 VTFunctionVTtoECU 172-172;
SG_MUL_VAL_ 2498166526 ErrorCodeChangeLineAttribute2 VTFunctionVTtoECU 171-171;
SG_MUL_VAL_ 2498166526 ErrorCodeChangeFont2 VTFunctionVTtoECU 170-170;
SG_MUL_VAL_ 2498166526 ErrorCodeChangeEditPoint2 VTFunctionVTtoECU 169-169;
SG_MUL_VAL_ 2498166526 ErrorCodeChangeNumValue2 VTFunctionVTtoECU 168-168;
SG_MUL_VAL_ 2498166526 ErrorCodeExecuteExtendedMacro2 VTFunctionVTtoECU 188-188;
SG_MUL_VAL_ 2498166526 ObjectIDOfFaultyObject VTFunctionVTtoECU 240-240;
SG_MUL_VAL_ 2498166526 Hardware1 VTFunctionVTtoECU 199-199;
SG_MUL_VAL_ 2498166526 ErrorCodeSelectColourMap1 VTFunctionVTtoECU 186-186;
SG_MUL_VAL_ 2498166526 AttributeID VTFunctionVTtoECU 185-185;
SG_MUL_VAL_ 2498166526 SubCommandID VTFunctionVTtoECU 184-184;
SG_MUL_VAL_ 2498166526 NewWidthAttribute VTFunctionVTtoECU 183-183;
SG_MUL_VAL_ 2498166526 ErrorCodeChangePoygonPoint1 VTFunctionVTtoECU 182-182;
SG_MUL_VAL_ 2498166526 ChangeChildPosObjID VTFunctionVTtoECU 180-180;
SG_MUL_VAL_ 2498166526 ChangeStringValueObjID VTFunctionVTtoECU 179-179;
SG_MUL_VAL_ 2498166526 ListIndex VTFunctionVTtoECU 177-177;
SG_MUL_VAL_ 2498166526 NewPriority VTFunctionVTtoECU 176-176;
SG_MUL_VAL_ 2498166526 AttributeToChangeID VTFunctionVTtoECU 175-175;
SG_MUL_VAL_ 2498166526 SoftKeyMaskObjectID VTFunctionVTtoECU 174-174;
SG_MUL_VAL_ 2498166526 ErrorCodeChangeActiveMask1 VTFunctionVTtoECU 173-173;
SG_MUL_VAL_ 2498166526 ErrorCodeChangeFillAttributes1 VTFunctionVTtoECU 172-172;
SG_MUL_VAL_ 2498166526 ErrorCodeChangeLineAttribute1 VTFunctionVTtoECU 171-171;
SG_MUL_VAL_ 2498166526 ErrorCodeChangeFont1 VTFunctionVTtoECU 170-170;
SG_MUL_VAL_ 2498166526 ErrorCodeChangeEditPoint1 VTFunctionVTtoECU 169-169;
SG_MUL_VAL_ 2498166526 ErrorCodeChangeNumValue1 VTFunctionVTtoECU 168-168;
SG_MUL_VAL_ 2498166526 NewBackgroundColour VTFunctionVTtoECU 167-167;
SG_MUL_VAL_ 2498166526 ErrorCodeObjToSize1 VTFunctionVTtoECU 166-166;
SG_MUL_VAL_ 2498166526 ChangeChildLocObjID VTFunctionVTtoECU 165-165;
SG_MUL_VAL_ 2498166526 ObjectSelectStatus VTFunctionVTtoECU 162-162;
SG_MUL_VAL_ 2498166526 ObjectEnableStatus VTFunctionVTtoECU 161-161;
SG_MUL_VAL_ 2498166526 ObjectShowStatus VTFunctionVTtoECU 160-160;
SG_MUL_VAL_ 2498166526 ErrorCodeEscapeObj1 VTFunctionVTtoECU 146-146;
SG_MUL_VAL_ 2498166526 AuxInputEnable VTFunctionVTtoECU 37-37;
SG_MUL_VAL_ 2498166526 Value1 VTFunctionVTtoECU 38-38;
SG_MUL_VAL_ 2498166526 EnteredStringValue VTFunctionVTtoECU 8-8;
SG_MUL_VAL_ 2498166526 VTChangeSoftKeyMaskObjectID VTFunctionVTtoECU 7-7;
SG_MUL_VAL_ 2498166526 ErrorCodeVTEsc1 VTFunctionVTtoECU 4-4;
SG_MUL_VAL_ 2498166526 VTSelectInputObjectStatus VTFunctionVTtoECU 3-3;
SG_MUL_VAL_ 2498166526 YPosition VTFunctionVTtoECU 2-2;
SG_MUL_VAL_ 2498166526 Status_1 VTFunctionVTtoECU 9-9;
SG_MUL_VAL_ 2498166526 ErrorCodeExecuteExtendedMacro1 VTFunctionVTtoECU 188-188;
SG_MUL_VAL_ 2498166526 ErrorCodeLockUnlockMask8 VTFunctionVTtoECU 189-189;
SG_MUL_VAL_ 2498166526 ErrorCodeLockUnlockMask7 VTFunctionVTtoECU 189-189;
SG_MUL_VAL_ 2498166526 ErrorCodeLockUnlockMask6 VTFunctionVTtoECU 189-189;
SG_MUL_VAL_ 2498166526 ErrorCodeLockUnlockMask5 VTFunctionVTtoECU 189-189;
SG_MUL_VAL_ 2498166526 ErrorCodeLockUnlockMask4 VTFunctionVTtoECU 189-189;
SG_MUL_VAL_ 2498166526 ErrorCodeExecuteMacro3 VTFunctionVTtoECU 190-190;
SG_MUL_VAL_ 2498166526 ErrorCodeLockUnlockMask3 VTFunctionVTtoECU 189-189;
SG_MUL_VAL_ 2498166526 ErrorCodeExecuteMacro2 VTFunctionVTtoECU 190-190;
SG_MUL_VAL_ 2498166526 ErrorCodeLockUnlockMask2 VTFunctionVTtoECU 189-189;
SG_MUL_VAL_ 2498166526 NameOfAuxiliaryUnit1 VTFunctionVTtoECU 39-39;
SG_MUL_VAL_ 2498166526 ExtendedVersionLables VTFunctionVTtoECU 211-211;
SG_MUL_VAL_ 2498166526 VisibleDataOrAlarmMaskObjectID VTFunctionVTtoECU 254-254;
SG_MUL_VAL_ 2498166526 VersionLables VTFunctionVTtoECU 224-224;
SG_MUL_VAL_ 2498166526 SupportedGraphicMode VTFunctionVTtoECU 199-199;
SG_MUL_VAL_ 2498166526 FirstWideChar VTFunctionVTtoECU 193-193;
SG_MUL_VAL_ 2498166526 MemoryStatus VTFunctionVTtoECU 192-192;
SG_MUL_VAL_ 2498166526 ErrorCodeExecuteMacro1 VTFunctionVTtoECU 190-190;
SG_MUL_VAL_ 2498166526 ErrorCodeLockUnlockMask1 VTFunctionVTtoECU 189-189;
SG_MUL_VAL_ 2498166526 ParentObjectIDOfFaultyObject VTFunctionVTtoECU 18-18;
SG_MUL_VAL_ 2498166526 ButtonObjectID VTFunctionVTtoECU 1-1;
SG_MUL_VAL_ 2498166526 KeyObjectID VTFunctionVTtoECU 0-0;
SG_MUL_VAL_ 2498166526 AuxFunctObjOfFaultyAssignment VTFunctionVTtoECU 34-34;
SG_MUL_VAL_ 2498166526 AnalogValue VTFunctionVTtoECU 33-33;
SG_MUL_VAL_ 2498166526 BgrColourUserLayoutSoftkeyMask VTFunctionVTtoECU 196-196;
SG_MUL_VAL_ 2498166526 ErrorCodeSetObjectLabel6 VTFunctionVTtoECU 181-181;
SG_MUL_VAL_ 2498166526 ErrorCodeSetObjectLabel5 VTFunctionVTtoECU 181-181;
SG_MUL_VAL_ 2498166526 ErrorCodeDeleteObjectPool2 VTFunctionVTtoECU 178-178;
SG_MUL_VAL_ 2498166526 ErrorCodeAudioVolume2 VTFunctionVTtoECU 164-164;
SG_MUL_VAL_ 2498166526 ErrorCodeControlAudioDevice2 VTFunctionVTtoECU 163-163;
SG_MUL_VAL_ 2498166526 ErrorCodeEndOfObjectPool3 VTFunctionVTtoECU 18-18;
SG_MUL_VAL_ 2498166526 AuxPreferredAssignmentRespError5 VTFunctionVTtoECU 34-34;
SG_MUL_VAL_ 2498166526 ErrorCodeSetObjectLabel4 VTFunctionVTtoECU 181-181;
SG_MUL_VAL_ 2498166526 AuxPreferredAssignmentRespError4 VTFunctionVTtoECU 34-34;
SG_MUL_VAL_ 2498166526 ErrorCodeSetObjectLabel3 VTFunctionVTtoECU 181-181;
SG_MUL_VAL_ 2498166526 AuxPreferredAssignmentRespError3 VTFunctionVTtoECU 34-34;
SG_MUL_VAL_ 2498166526 ErrorCodeSetObjectLabel2 VTFunctionVTtoECU 181-181;
SG_MUL_VAL_ 2498166526 AuxPreferredAssignmentRespError2 VTFunctionVTtoECU 34-34;
SG_MUL_VAL_ 2498166526 ErrorCodeEndOfObjectPool2 VTFunctionVTtoECU 18-18;
SG_MUL_VAL_ 2498166526 SourceAdressOfActiveWSM VTFunctionVTtoECU 254-254;
SG_MUL_VAL_ 2498166526 ParentIDOfFaultyObject VTFunctionVTtoECU 240-240;
SG_MUL_VAL_ 2498166526 NrOfVersionStrings VTFunctionVTtoECU 224-224, 211-211;
SG_MUL_VAL_ 2498166526 NavigationSoftKeys VTFunctionVTtoECU 194-194;
SG_MUL_VAL_ 2498166526 CodePlane VTFunctionVTtoECU 193-193;
SG_MUL_VAL_ 2498166526 VersionNumberISO11783Part6 VTFunctionVTtoECU 192-192;
SG_MUL_VAL_ 2498166526 MacroObjectID VTFunctionVTtoECU 190-190;
SG_MUL_VAL_ 2498166526 LockUnlockCommand VTFunctionVTtoECU 189-189;
SG_MUL_VAL_ 2498166526 ColourMapObjectID VTFunctionVTtoECU 186-186;
SG_MUL_VAL_ 2498166526 ObjectToGetAttributeID VTFunctionVTtoECU 185-185;
SG_MUL_VAL_ 2498166526 GraphicsContextObjectID VTFunctionVTtoECU 184-184;
SG_MUL_VAL_ 2498166526 PolygonObjectToScaleID VTFunctionVTtoECU 183-183;
SG_MUL_VAL_ 2498166526 PolygonObjectToChangeID VTFunctionVTtoECU 182-182;
SG_MUL_VAL_ 2498166526 ErrorCodeSetObjectLabel1 VTFunctionVTtoECU 181-181;
SG_MUL_VAL_ 2498166526 ChangeChildPosParObjID VTFunctionVTtoECU 180-180;
SG_MUL_VAL_ 2498166526 ErrorCodeDeleteObjectPool1 VTFunctionVTtoECU 178-178;
SG_MUL_VAL_ 2498166526 ListInputObjectID VTFunctionVTtoECU 177-177;
SG_MUL_VAL_ 2498166526 AlarmMaskObjectID VTFunctionVTtoECU 176-176;
SG_MUL_VAL_ 2498166526 ObjectToChangeAttributeID VTFunctionVTtoECU 175-175;
SG_MUL_VAL_ 2498166526 DataOrAlarmMaskObjectID VTFunctionVTtoECU 174-174;
SG_MUL_VAL_ 2498166526 ActiveMaskObjectID VTFunctionVTtoECU 173-173;
SG_MUL_VAL_ 2498166526 ObjectToChangeFillAttributesID VTFunctionVTtoECU 172-172;
SG_MUL_VAL_ 2498166526 ObjectToChangeLineAttributeID VTFunctionVTtoECU 171-171;
SG_MUL_VAL_ 2498166526 ObjectToChangeFontID VTFunctionVTtoECU 170-170;
SG_MUL_VAL_ 2498166526 ObjectToChangeEndPointID VTFunctionVTtoECU 169-169;
SG_MUL_VAL_ 2498166526 ObjectToChangeNumValueID VTFunctionVTtoECU 168-168;
SG_MUL_VAL_ 2498166526 ObjectToChangeColourID VTFunctionVTtoECU 167-167;
SG_MUL_VAL_ 2498166526 ObjectToSizeID VTFunctionVTtoECU 166-166;
SG_MUL_VAL_ 2498166526 ChangeChildLocParObjID VTFunctionVTtoECU 165-165;
SG_MUL_VAL_ 2498166526 ErrorCodeAudioVolume1 VTFunctionVTtoECU 164-164;
SG_MUL_VAL_ 2498166526 ErrorCodeControlAudioDevice1 VTFunctionVTtoECU 163-163;
SG_MUL_VAL_ 2498166526 SelectInputObjectID VTFunctionVTtoECU 162-162;
SG_MUL_VAL_ 2498166526 ObjectToEnableDisableID VTFunctionVTtoECU 161-161;
SG_MUL_VAL_ 2498166526 ObjectToHideShowID VTFunctionVTtoECU 160-160;
SG_MUL_VAL_ 2498166526 ObjectEscapeID VTFunctionVTtoECU 146-146;
SG_MUL_VAL_ 2498166526 InputStatusObjectId VTFunctionVTtoECU 37-37;
SG_MUL_VAL_ 2498166526 AuxPreferredAssignmentRespError1 VTFunctionVTtoECU 34-34;
SG_MUL_VAL_ 2498166526 InputObjectId VTFunctionVTtoECU 38-38;
SG_MUL_VAL_ 2498166526 IdentityNumber VTFunctionVTtoECU 36-36;
SG_MUL_VAL_ 2498166526 ErrorCodeEndOfObjectPool1 VTFunctionVTtoECU 18-18;
SG_MUL_VAL_ 2498166526 ObjectToChangeStringID VTFunctionVTtoECU 8-8;
SG_MUL_VAL_ 2498166526 VTChangeSoftKeyMaskParentID VTFunctionVTtoECU 7-7;
SG_MUL_VAL_ 2498166526 VTChangeActiveMaskObjectID VTFunctionVTtoECU 6-6;
SG_MUL_VAL_ 2498166526 VTChangeNumericValueObjectID VTFunctionVTtoECU 5-5;
SG_MUL_VAL_ 2498166526 VTEscObjectID VTFunctionVTtoECU 4-4;
SG_MUL_VAL_ 2498166526 VTSelectInputObjectID VTFunctionVTtoECU 3-3;
SG_MUL_VAL_ 2498166526 XPosition VTFunctionVTtoECU 2-2;
SG_MUL_VAL_ 2498166526 ButtonActivationCode VTFunctionVTtoECU 1-1;
SG_MUL_VAL_ 2498166526 KeyActivationCode VTFunctionVTtoECU 0-0;
SG_MUL_VAL_ 2498166526 TerminationCause VTFunctionVTtoECU 10-10;
SG_MUL_VAL_ 2498166526 InputNumber VTFunctionVTtoECU 33-33;
SG_MUL_VAL_ 2498166526 ObjectID_1 VTFunctionVTtoECU 9-9;
SG_MUL_VAL_ 2498166526 BgrColourUserLayoutDataMask VTFunctionVTtoECU 196-196;
SG_MUL_VAL_ 2498166526 NumberOfSupportedObjects VTFunctionVTtoECU 197-197;
SG_MUL_VAL_ 2498166526 BootTime VTFunctionVTtoECU 199-199;
SG_MUL_VAL_ 2498166526 NumberOfAuxiliaryUnits VTFunctionVTtoECU 39-39;
SG_MUL_VAL_ 2498166526 MacroObjectID_2 VTFunctionVTtoECU 188-188;
